VERSION ""

NS_ :

BS_:

BU_: Vector__XXX
BA_DEF_ BO_ "VFrameFormat" ENUM "StandardCAN","ExtendedCAN","reserved","J1939PG";
BA_DEF_DEF_ "VFrameFormat" 0;

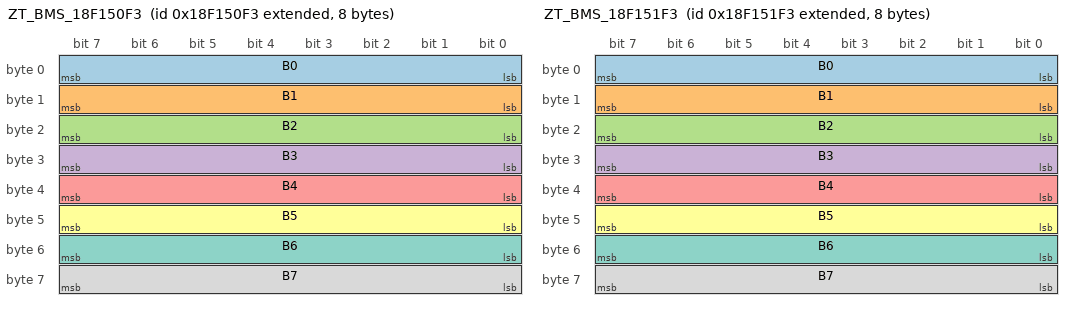
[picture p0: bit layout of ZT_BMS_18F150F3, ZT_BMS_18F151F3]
BO_ 2565951731 ZT_BMS_18F150F3: 8 Vector__XXX
 SG_ B0 : 0|8@1+ (1,0) [0|255] "" Vector__XXX
 SG_ B1 : 8|8@1+ (1,0) [0|255] "" Vector__XXX
 SG_ B2 : 16|8@1+ (1,0) [0|255] "" Vector__XXX
 SG_ B3 : 24|8@1+ (1,0) [0|255] "" Vector__XXX
 SG_ B4 : 32|8@1+ (1,0) [0|255] "" Vector__XXX
 SG_ B5 : 40|8@1+ (1,0) [0|255] "" Vector__XXX
 SG_ B6 : 48|8@1+ (1,0) [0|255] "" Vector__XXX
 SG_ B7 : 56|8@1+ (1,0) [0|255] "" Vector__XXX

BA_ "VFrameFormat" BO_ 2565951731 1;
CM_ BO_ 2565951731 "0xB3000005 中通新能源 > 纯电动客车 > 10-12米纯电公交客车 > 电池管理系统 | 0xB300006A 中通新能源 > 纯电动客车 > 电动新大巴客车 > 电池管理系统 | 部件: 电池管理系统";

BO_ 2565951987 ZT_BMS_18F151F3: 8 Vector__XXX
 SG_ B0 : 0|8@1+ (1,0) [0|255] "" Vector__XXX
 SG_ B1 : 8|8@1+ (1,0) [0|255] "" Vector__XXX
 SG_ B2 : 16|8@1+ (1,0) [0|255] "" Vector__XXX
 SG_ B3 : 24|8@1+ (1,0) [0|255] "" Vector__XXX
 SG_ B4 : 32|8@1+ (1,0) [0|255] "" Vector__XXX
 SG_ B5 : 40|8@1+ (1,0) [0|255] "" Vector__XXX
 SG_ B6 : 48|8@1+ (1,0) [0|255] "" Vector__XXX
 SG_ B7 : 56|8@1+ (1,0) [0|255] "" Vector__XXX

BA_ "VFrameFormat" BO_ 2565951987 1;
CM_ BO_ 2565951987 "0xB3000005 中通新能源 > 纯电动客车 > 10-12米纯电公交客车 > 电池管理系统 | 0xB300006A 中通新能源 > 纯电动客车 > 电动新大巴客车 > 电池管理系统 | 部件: 电池管理系统";

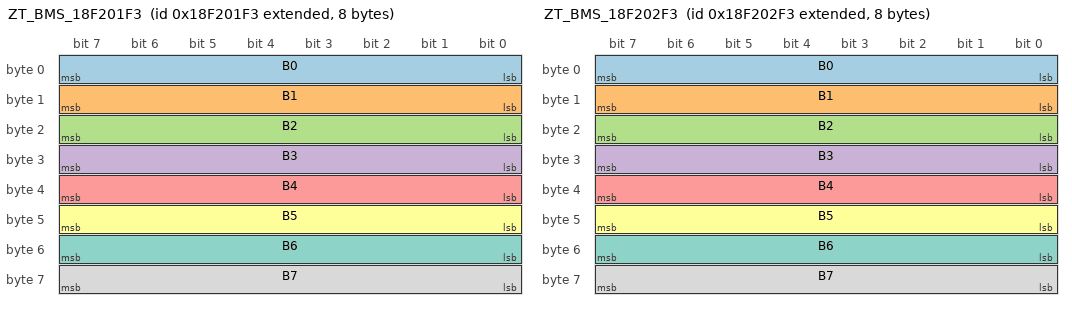
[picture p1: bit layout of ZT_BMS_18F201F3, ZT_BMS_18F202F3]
BO_ 2565997043 ZT_BMS_18F201F3: 8 Vector__XXX
 SG_ B0 : 0|8@1+ (1,0) [0|255] "" Vector__XXX
 SG_ B1 : 8|8@1+ (1,0) [0|255] "" Vector__XXX
 SG_ B2 : 16|8@1+ (1,0) [0|255] "" Vector__XXX
 SG_ B3 : 24|8@1+ (1,0) [0|255] "" Vector__XXX
 SG_ B4 : 32|8@1+ (1,0) [0|255] "" Vector__XXX
 SG_ B5 : 40|8@1+ (1,0) [0|255] "" Vector__XXX
 SG_ B6 : 48|8@1+ (1,0) [0|255] "" Vector__XXX
 SG_ B7 : 56|8@1+ (1,0) [0|255] "" Vector__XXX

BA_ "VFrameFormat" BO_ 2565997043 1;
CM_ BO_ 2565997043 "0xB3000005 中通新能源 > 纯电动客车 > 10-12米纯电公交客车 > 电池管理系统 | 0xB3000022 中通新能源 > 纯电动客车 > 6米微巴客车 > 电池管理系统 | 0xB300003D 中通新能源 > 纯电动客车 > 8米纯电公交客车 > 电池管理系统 | 0xB300006A 中通新能源 > 纯电动客车 > 电动新大巴客车 > 电池管理系统 | 0xB3000086 中通新能源 > 燃料电池客车 > 电池管理系统 | 0xB30000A8 中通新能源 > 澳巴混合动力 > 7米澳巴混合动力客车 > 电池管理系统 | 0xB30000C9 中通新能源 > 澳巴混合动力 > 9米11米澳巴混合动力客车 > 电池管理系统 | 部件: 电池管理系统";

BO_ 2565997299 ZT_BMS_18F202F3: 8 Vector__XXX
 SG_ B0 : 0|8@1+ (1,0) [0|255] "" Vector__XXX
 SG_ B1 : 8|8@1+ (1,0) [0|255] "" Vector__XXX
 SG_ B2 : 16|8@1+ (1,0) [0|255] "" Vector__XXX
 SG_ B3 : 24|8@1+ (1,0) [0|255] "" Vector__XXX
 SG_ B4 : 32|8@1+ (1,0) [0|255] "" Vector__XXX
 SG_ B5 : 40|8@1+ (1,0) [0|255] "" Vector__XXX
 SG_ B6 : 48|8@1+ (1,0) [0|255] "" Vector__XXX
 SG_ B7 : 56|8@1+ (1,0) [0|255] "" Vector__XXX

BA_ "VFrameFormat" BO_ 2565997299 1;
CM_ BO_ 2565997299 "0xB3000005 中通新能源 > 纯电动客车 > 10-12米纯电公交客车 > 电池管理系统 | 0xB3000022 中通新能源 > 纯电动客车 > 6米微巴客车 > 电池管理系统 | 0xB300003D 中通新能源 > 纯电动客车 > 8米纯电公交客车 > 电池管理系统 | 0xB300006A 中通新能源 > 纯电动客车 > 电动新大巴客车 > 电池管理系统 | 0xB3000086 中通新能源 > 燃料电池客车 > 电池管理系统 | 0xB30000A8 中通新能源 > 澳巴混合动力 > 7米澳巴混合动力客车 > 电池管理系统 | 0xB30000C9 中通新能源 > 澳巴混合动力 > 9米11米澳巴混合动力客车 > 电池管理系统 | 部件: 电池管理系统";

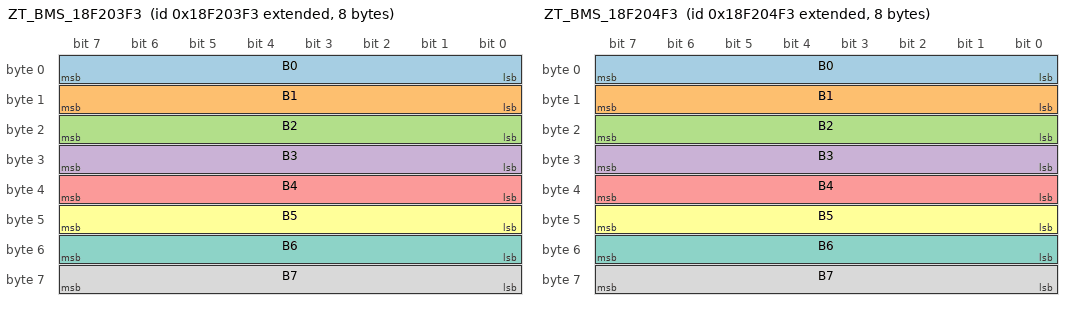
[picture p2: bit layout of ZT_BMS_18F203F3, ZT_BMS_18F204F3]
BO_ 2565997555 ZT_BMS_18F203F3: 8 Vector__XXX
 SG_ B0 : 0|8@1+ (1,0) [0|255] "" Vector__XXX
 SG_ B1 : 8|8@1+ (1,0) [0|255] "" Vector__XXX
 SG_ B2 : 16|8@1+ (1,0) [0|255] "" Vector__XXX
 SG_ B3 : 24|8@1+ (1,0) [0|255] "" Vector__XXX
 SG_ B4 : 32|8@1+ (1,0) [0|255] "" Vector__XXX
 SG_ B5 : 40|8@1+ (1,0) [0|255] "" Vector__XXX
 SG_ B6 : 48|8@1+ (1,0) [0|255] "" Vector__XXX
 SG_ B7 : 56|8@1+ (1,0) [0|255] "" Vector__XXX

BA_ "VFrameFormat" BO_ 2565997555 1;
CM_ BO_ 2565997555 "0xB3000005 中通新能源 > 纯电动客车 > 10-12米纯电公交客车 > 电池管理系统 | 0xB3000022 中通新能源 > 纯电动客车 > 6米微巴客车 > 电池管理系统 | 0xB300003D 中通新能源 > 纯电动客车 > 8米纯电公交客车 > 电池管理系统 | 0xB300006A 中通新能源 > 纯电动客车 > 电动新大巴客车 > 电池管理系统 | 0xB3000086 中通新能源 > 燃料电池客车 > 电池管理系统 | 0xB30000A8 中通新能源 > 澳巴混合动力 > 7米澳巴混合动力客车 > 电池管理系统 | 0xB30000C9 中通新能源 > 澳巴混合动力 > 9米11米澳巴混合动力客车 > 电池管理系统 | 部件: 电池管理系统";

BO_ 2565997811 ZT_BMS_18F204F3: 8 Vector__XXX
 SG_ B0 : 0|8@1+ (1,0) [0|255] "" Vector__XXX
 SG_ B1 : 8|8@1+ (1,0) [0|255] "" Vector__XXX
 SG_ B2 : 16|8@1+ (1,0) [0|255] "" Vector__XXX
 SG_ B3 : 24|8@1+ (1,0) [0|255] "" Vector__XXX
 SG_ B4 : 32|8@1+ (1,0) [0|255] "" Vector__XXX
 SG_ B5 : 40|8@1+ (1,0) [0|255] "" Vector__XXX
 SG_ B6 : 48|8@1+ (1,0) [0|255] "" Vector__XXX
 SG_ B7 : 56|8@1+ (1,0) [0|255] "" Vector__XXX

BA_ "VFrameFormat" BO_ 2565997811 1;
CM_ BO_ 2565997811 "0xB3000005 中通新能源 > 纯电动客车 > 10-12米纯电公交客车 > 电池管理系统 | 0xB300003D 中通新能源 > 纯电动客车 > 8米纯电公交客车 > 电池管理系统 | 0xB300006A 中通新能源 > 纯电动客车 > 电动新大巴客车 > 电池管理系统 | 0xB30000C9 中通新能源 > 澳巴混合动力 > 9米11米澳巴混合动力客车 > 电池管理系统 | 部件: 电池管理系统";

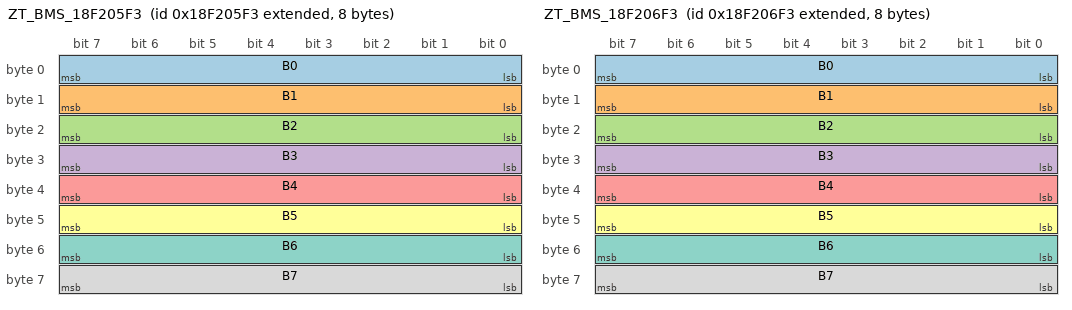
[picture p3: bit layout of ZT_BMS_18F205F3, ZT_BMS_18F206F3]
BO_ 2565998067 ZT_BMS_18F205F3: 8 Vector__XXX
 SG_ B0 : 0|8@1+ (1,0) [0|255] "" Vector__XXX
 SG_ B1 : 8|8@1+ (1,0) [0|255] "" Vector__XXX
 SG_ B2 : 16|8@1+ (1,0) [0|255] "" Vector__XXX
 SG_ B3 : 24|8@1+ (1,0) [0|255] "" Vector__XXX
 SG_ B4 : 32|8@1+ (1,0) [0|255] "" Vector__XXX
 SG_ B5 : 40|8@1+ (1,0) [0|255] "" Vector__XXX
 SG_ B6 : 48|8@1+ (1,0) [0|255] "" Vector__XXX
 SG_ B7 : 56|8@1+ (1,0) [0|255] "" Vector__XXX

BA_ "VFrameFormat" BO_ 2565998067 1;
CM_ BO_ 2565998067 "0xB3000005 中通新能源 > 纯电动客车 > 10-12米纯电公交客车 > 电池管理系统 | 0xB300006A 中通新能源 > 纯电动客车 > 电动新大巴客车 > 电池管理系统 | 部件: 电池管理系统";

BO_ 2565998323 ZT_BMS_18F206F3: 8 Vector__XXX
 SG_ B0 : 0|8@1+ (1,0) [0|255] "" Vector__XXX
 SG_ B1 : 8|8@1+ (1,0) [0|255] "" Vector__XXX
 SG_ B2 : 16|8@1+ (1,0) [0|255] "" Vector__XXX
 SG_ B3 : 24|8@1+ (1,0) [0|255] "" Vector__XXX
 SG_ B4 : 32|8@1+ (1,0) [0|255] "" Vector__XXX
 SG_ B5 : 40|8@1+ (1,0) [0|255] "" Vector__XXX
 SG_ B6 : 48|8@1+ (1,0) [0|255] "" Vector__XXX
 SG_ B7 : 56|8@1+ (1,0) [0|255] "" Vector__XXX

BA_ "VFrameFormat" BO_ 2565998323 1;
CM_ BO_ 2565998323 "0xB3000005 中通新能源 > 纯电动客车 > 10-12米纯电公交客车 > 电池管理系统 | 0xB300006A 中通新能源 > 纯电动客车 > 电动新大巴客车 > 电池管理系统 | 部件: 电池管理系统";

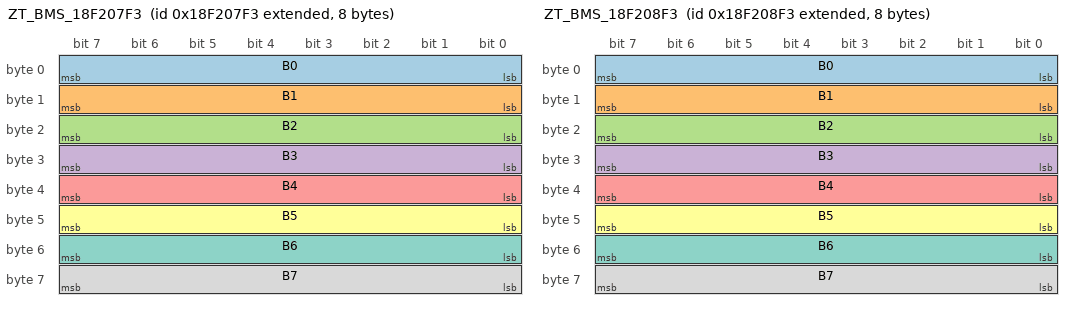
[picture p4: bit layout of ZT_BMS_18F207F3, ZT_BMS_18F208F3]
BO_ 2565998579 ZT_BMS_18F207F3: 8 Vector__XXX
 SG_ B0 : 0|8@1+ (1,0) [0|255] "" Vector__XXX
 SG_ B1 : 8|8@1+ (1,0) [0|255] "" Vector__XXX
 SG_ B2 : 16|8@1+ (1,0) [0|255] "" Vector__XXX
 SG_ B3 : 24|8@1+ (1,0) [0|255] "" Vector__XXX
 SG_ B4 : 32|8@1+ (1,0) [0|255] "" Vector__XXX
 SG_ B5 : 40|8@1+ (1,0) [0|255] "" Vector__XXX
 SG_ B6 : 48|8@1+ (1,0) [0|255] "" Vector__XXX
 SG_ B7 : 56|8@1+ (1,0) [0|255] "" Vector__XXX

BA_ "VFrameFormat" BO_ 2565998579 1;
CM_ BO_ 2565998579 "0xB3000005 中通新能源 > 纯电动客车 > 10-12米纯电公交客车 > 电池管理系统 | 部件: 电池管理系统";

BO_ 2565998835 ZT_BMS_18F208F3: 8 Vector__XXX
 SG_ B0 : 0|8@1+ (1,0) [0|255] "" Vector__XXX
 SG_ B1 : 8|8@1+ (1,0) [0|255] "" Vector__XXX
 SG_ B2 : 16|8@1+ (1,0) [0|255] "" Vector__XXX
 SG_ B3 : 24|8@1+ (1,0) [0|255] "" Vector__XXX
 SG_ B4 : 32|8@1+ (1,0) [0|255] "" Vector__XXX
 SG_ B5 : 40|8@1+ (1,0) [0|255] "" Vector__XXX
 SG_ B6 : 48|8@1+ (1,0) [0|255] "" Vector__XXX
 SG_ B7 : 56|8@1+ (1,0) [0|255] "" Vector__XXX

BA_ "VFrameFormat" BO_ 2565998835 1;
CM_ BO_ 2565998835 "0xB3000005 中通新能源 > 纯电动客车 > 10-12米纯电公交客车 > 电池管理系统 | 部件: 电池管理系统";

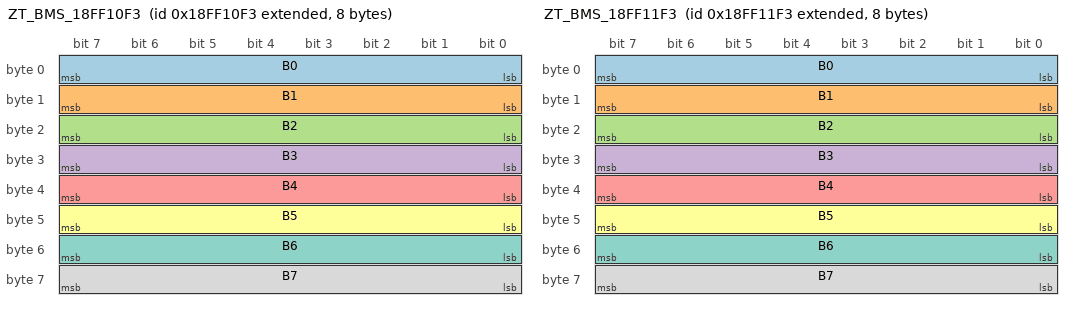
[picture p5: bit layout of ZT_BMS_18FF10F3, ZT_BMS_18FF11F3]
BO_ 2566852851 ZT_BMS_18FF10F3: 8 Vector__XXX
 SG_ B0 : 0|8@1+ (1,0) [0|255] "" Vector__XXX
 SG_ B1 : 8|8@1+ (1,0) [0|255] "" Vector__XXX
 SG_ B2 : 16|8@1+ (1,0) [0|255] "" Vector__XXX
 SG_ B3 : 24|8@1+ (1,0) [0|255] "" Vector__XXX
 SG_ B4 : 32|8@1+ (1,0) [0|255] "" Vector__XXX
 SG_ B5 : 40|8@1+ (1,0) [0|255] "" Vector__XXX
 SG_ B6 : 48|8@1+ (1,0) [0|255] "" Vector__XXX
 SG_ B7 : 56|8@1+ (1,0) [0|255] "" Vector__XXX

BA_ "VFrameFormat" BO_ 2566852851 1;
CM_ BO_ 2566852851 "0xB3000005 中通新能源 > 纯电动客车 > 10-12米纯电公交客车 > 电池管理系统 | 0xB3000022 中通新能源 > 纯电动客车 > 6米微巴客车 > 电池管理系统 | 0xB300003D 中通新能源 > 纯电动客车 > 8米纯电公交客车 > 电池管理系统 | 0xB300006A 中通新能源 > 纯电动客车 > 电动新大巴客车 > 电池管理系统 | 0xB3000086 中通新能源 > 燃料电池客车 > 电池管理系统 | 0xB30000A8 中通新能源 > 澳巴混合动力 > 7米澳巴混合动力客车 > 电池管理系统 | 0xB30000C9 中通新能源 > 澳巴混合动力 > 9米11米澳巴混合动力客车 > 电池管理系统 | 部件: 电池管理系统";

BO_ 2566853107 ZT_BMS_18FF11F3: 8 Vector__XXX
 SG_ B0 : 0|8@1+ (1,0) [0|255] "" Vector__XXX
 SG_ B1 : 8|8@1+ (1,0) [0|255] "" Vector__XXX
 SG_ B2 : 16|8@1+ (1,0) [0|255] "" Vector__XXX
 SG_ B3 : 24|8@1+ (1,0) [0|255] "" Vector__XXX
 SG_ B4 : 32|8@1+ (1,0) [0|255] "" Vector__XXX
 SG_ B5 : 40|8@1+ (1,0) [0|255] "" Vector__XXX
 SG_ B6 : 48|8@1+ (1,0) [0|255] "" Vector__XXX
 SG_ B7 : 56|8@1+ (1,0) [0|255] "" Vector__XXX

BA_ "VFrameFormat" BO_ 2566853107 1;
CM_ BO_ 2566853107 "0xB3000005 中通新能源 > 纯电动客车 > 10-12米纯电公交客车 > 电池管理系统 | 0xB3000022 中通新能源 > 纯电动客车 > 6米微巴客车 > 电池管理系统 | 0xB300003D 中通新能源 > 纯电动客车 > 8米纯电公交客车 > 电池管理系统 | 0xB300006A 中通新能源 > 纯电动客车 > 电动新大巴客车 > 电池管理系统 | 0xB3000086 中通新能源 > 燃料电池客车 > 电池管理系统 | 0xB30000A8 中通新能源 > 澳巴混合动力 > 7米澳巴混合动力客车 > 电池管理系统 | 0xB30000C9 中通新能源 > 澳巴混合动力 > 9米11米澳巴混合动力客车 > 电池管理系统 | 部件: 电池管理系统";

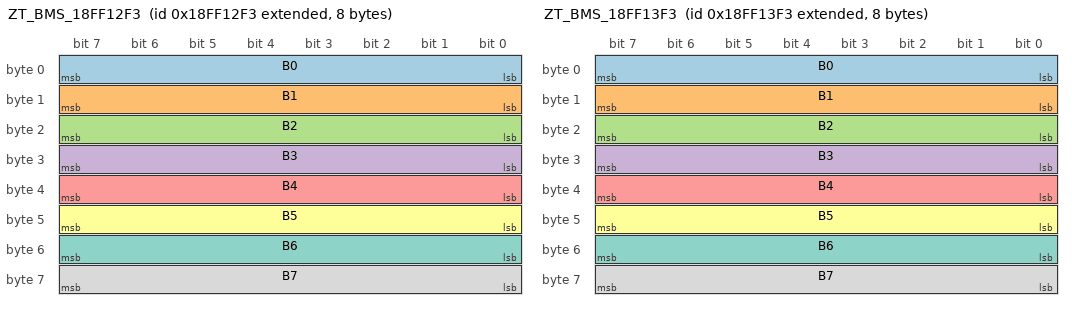
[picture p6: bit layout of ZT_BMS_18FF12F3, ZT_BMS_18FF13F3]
BO_ 2566853363 ZT_BMS_18FF12F3: 8 Vector__XXX
 SG_ B0 : 0|8@1+ (1,0) [0|255] "" Vector__XXX
 SG_ B1 : 8|8@1+ (1,0) [0|255] "" Vector__XXX
 SG_ B2 : 16|8@1+ (1,0) [0|255] "" Vector__XXX
 SG_ B3 : 24|8@1+ (1,0) [0|255] "" Vector__XXX
 SG_ B4 : 32|8@1+ (1,0) [0|255] "" Vector__XXX
 SG_ B5 : 40|8@1+ (1,0) [0|255] "" Vector__XXX
 SG_ B6 : 48|8@1+ (1,0) [0|255] "" Vector__XXX
 SG_ B7 : 56|8@1+ (1,0) [0|255] "" Vector__XXX

BA_ "VFrameFormat" BO_ 2566853363 1;
CM_ BO_ 2566853363 "0xB3000005 中通新能源 > 纯电动客车 > 10-12米纯电公交客车 > 电池管理系统 | 0xB3000022 中通新能源 > 纯电动客车 > 6米微巴客车 > 电池管理系统 | 0xB300003D 中通新能源 > 纯电动客车 > 8米纯电公交客车 > 电池管理系统 | 0xB300006A 中通新能源 > 纯电动客车 > 电动新大巴客车 > 电池管理系统 | 0xB3000086 中通新能源 > 燃料电池客车 > 电池管理系统 | 0xB30000A8 中通新能源 > 澳巴混合动力 > 7米澳巴混合动力客车 > 电池管理系统 | 0xB30000C9 中通新能源 > 澳巴混合动力 > 9米11米澳巴混合动力客车 > 电池管理系统 | 部件: 电池管理系统";

BO_ 2566853619 ZT_BMS_18FF13F3: 8 Vector__XXX
 SG_ B0 : 0|8@1+ (1,0) [0|255] "" Vector__XXX
 SG_ B1 : 8|8@1+ (1,0) [0|255] "" Vector__XXX
 SG_ B2 : 16|8@1+ (1,0) [0|255] "" Vector__XXX
 SG_ B3 : 24|8@1+ (1,0) [0|255] "" Vector__XXX
 SG_ B4 : 32|8@1+ (1,0) [0|255] "" Vector__XXX
 SG_ B5 : 40|8@1+ (1,0) [0|255] "" Vector__XXX
 SG_ B6 : 48|8@1+ (1,0) [0|255] "" Vector__XXX
 SG_ B7 : 56|8@1+ (1,0) [0|255] "" Vector__XXX

BA_ "VFrameFormat" BO_ 2566853619 1;
CM_ BO_ 2566853619 "0xB3000005 中通新能源 > 纯电动客车 > 10-12米纯电公交客车 > 电池管理系统 | 0xB3000022 中通新能源 > 纯电动客车 > 6米微巴客车 > 电池管理系统 | 0xB300003D 中通新能源 > 纯电动客车 > 8米纯电公交客车 > 电池管理系统 | 0xB300006A 中通新能源 > 纯电动客车 > 电动新大巴客车 > 电池管理系统 | 0xB3000086 中通新能源 > 燃料电池客车 > 电池管理系统 | 0xB30000A8 中通新能源 > 澳巴混合动力 > 7米澳巴混合动力客车 > 电池管理系统 | 0xB30000C9 中通新能源 > 澳巴混合动力 > 9米11米澳巴混合动力客车 > 电池管理系统 | 部件: 电池管理系统";

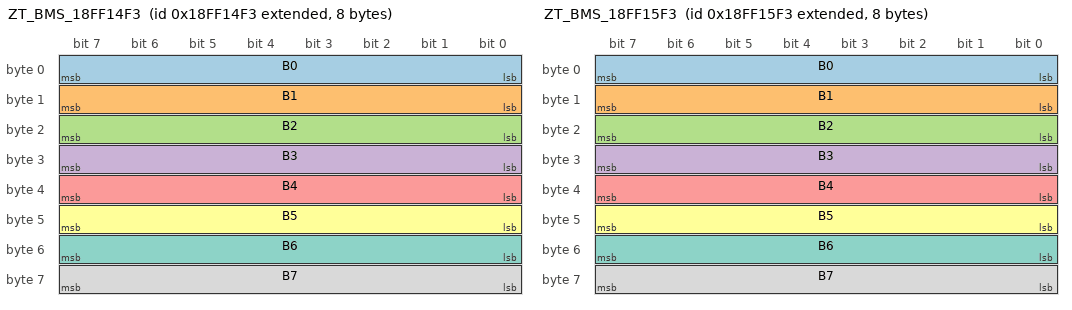
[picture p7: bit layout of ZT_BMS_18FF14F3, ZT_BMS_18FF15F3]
BO_ 2566853875 ZT_BMS_18FF14F3: 8 Vector__XXX
 SG_ B0 : 0|8@1+ (1,0) [0|255] "" Vector__XXX
 SG_ B1 : 8|8@1+ (1,0) [0|255] "" Vector__XXX
 SG_ B2 : 16|8@1+ (1,0) [0|255] "" Vector__XXX
 SG_ B3 : 24|8@1+ (1,0) [0|255] "" Vector__XXX
 SG_ B4 : 32|8@1+ (1,0) [0|255] "" Vector__XXX
 SG_ B5 : 40|8@1+ (1,0) [0|255] "" Vector__XXX
 SG_ B6 : 48|8@1+ (1,0) [0|255] "" Vector__XXX
 SG_ B7 : 56|8@1+ (1,0) [0|255] "" Vector__XXX

BA_ "VFrameFormat" BO_ 2566853875 1;
CM_ BO_ 2566853875 "0xB3000005 中通新能源 > 纯电动客车 > 10-12米纯电公交客车 > 电池管理系统 | 0xB3000022 中通新能源 > 纯电动客车 > 6米微巴客车 > 电池管理系统 | 0xB300003D 中通新能源 > 纯电动客车 > 8米纯电公交客车 > 电池管理系统 | 0xB300006A 中通新能源 > 纯电动客车 > 电动新大巴客车 > 电池管理系统 | 0xB3000086 中通新能源 > 燃料电池客车 > 电池管理系统 | 0xB30000A8 中通新能源 > 澳巴混合动力 > 7米澳巴混合动力客车 > 电池管理系统 | 0xB30000C9 中通新能源 > 澳巴混合动力 > 9米11米澳巴混合动力客车 > 电池管理系统 | 部件: 电池管理系统";

BO_ 2566854131 ZT_BMS_18FF15F3: 8 Vector__XXX
 SG_ B0 : 0|8@1+ (1,0) [0|255] "" Vector__XXX
 SG_ B1 : 8|8@1+ (1,0) [0|255] "" Vector__XXX
 SG_ B2 : 16|8@1+ (1,0) [0|255] "" Vector__XXX
 SG_ B3 : 24|8@1+ (1,0) [0|255] "" Vector__XXX
 SG_ B4 : 32|8@1+ (1,0) [0|255] "" Vector__XXX
 SG_ B5 : 40|8@1+ (1,0) [0|255] "" Vector__XXX
 SG_ B6 : 48|8@1+ (1,0) [0|255] "" Vector__XXX
 SG_ B7 : 56|8@1+ (1,0) [0|255] "" Vector__XXX

BA_ "VFrameFormat" BO_ 2566854131 1;
CM_ BO_ 2566854131 "0xB3000005 中通新能源 > 纯电动客车 > 10-12米纯电公交客车 > 电池管理系统 | 0xB3000022 中通新能源 > 纯电动客车 > 6米微巴客车 > 电池管理系统 | 0xB300003D 中通新能源 > 纯电动客车 > 8米纯电公交客车 > 电池管理系统 | 0xB300006A 中通新能源 > 纯电动客车 > 电动新大巴客车 > 电池管理系统 | 0xB3000086 中通新能源 > 燃料电池客车 > 电池管理系统 | 0xB30000A8 中通新能源 > 澳巴混合动力 > 7米澳巴混合动力客车 > 电池管理系统 | 0xB30000C9 中通新能源 > 澳巴混合动力 > 9米11米澳巴混合动力客车 > 电池管理系统 | 部件: 电池管理系统";

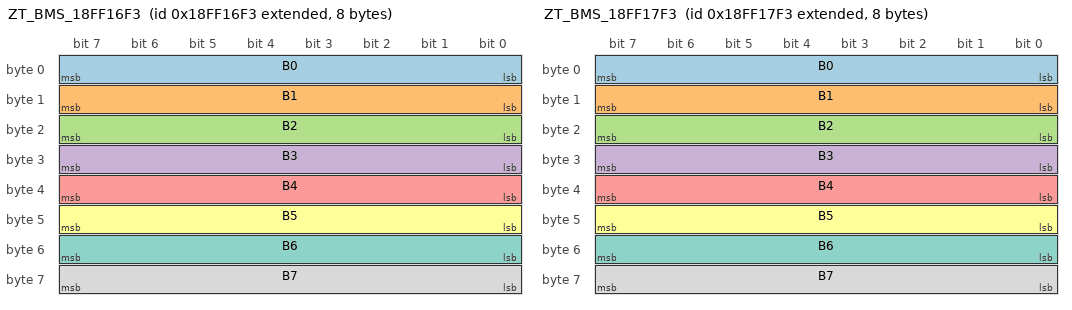
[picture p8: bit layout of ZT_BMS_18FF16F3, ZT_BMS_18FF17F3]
BO_ 2566854387 ZT_BMS_18FF16F3: 8 Vector__XXX
 SG_ B0 : 0|8@1+ (1,0) [0|255] "" Vector__XXX
 SG_ B1 : 8|8@1+ (1,0) [0|255] "" Vector__XXX
 SG_ B2 : 16|8@1+ (1,0) [0|255] "" Vector__XXX
 SG_ B3 : 24|8@1+ (1,0) [0|255] "" Vector__XXX
 SG_ B4 : 32|8@1+ (1,0) [0|255] "" Vector__XXX
 SG_ B5 : 40|8@1+ (1,0) [0|255] "" Vector__XXX
 SG_ B6 : 48|8@1+ (1,0) [0|255] "" Vector__XXX
 SG_ B7 : 56|8@1+ (1,0) [0|255] "" Vector__XXX

BA_ "VFrameFormat" BO_ 2566854387 1;
CM_ BO_ 2566854387 "0xB3000005 中通新能源 > 纯电动客车 > 10-12米纯电公交客车 > 电池管理系统 | 0xB300006A 中通新能源 > 纯电动客车 > 电动新大巴客车 > 电池管理系统 | 部件: 电池管理系统";

BO_ 2566854643 ZT_BMS_18FF17F3: 8 Vector__XXX
 SG_ B0 : 0|8@1+ (1,0) [0|255] "" Vector__XXX
 SG_ B1 : 8|8@1+ (1,0) [0|255] "" Vector__XXX
 SG_ B2 : 16|8@1+ (1,0) [0|255] "" Vector__XXX
 SG_ B3 : 24|8@1+ (1,0) [0|255] "" Vector__XXX
 SG_ B4 : 32|8@1+ (1,0) [0|255] "" Vector__XXX
 SG_ B5 : 40|8@1+ (1,0) [0|255] "" Vector__XXX
 SG_ B6 : 48|8@1+ (1,0) [0|255] "" Vector__XXX
 SG_ B7 : 56|8@1+ (1,0) [0|255] "" Vector__XXX

BA_ "VFrameFormat" BO_ 2566854643 1;
CM_ BO_ 2566854643 "0xB3000005 中通新能源 > 纯电动客车 > 10-12米纯电公交客车 > 电池管理系统 | 0xB300006A 中通新能源 > 纯电动客车 > 电动新大巴客车 > 电池管理系统 | 部件: 电池管理系统";

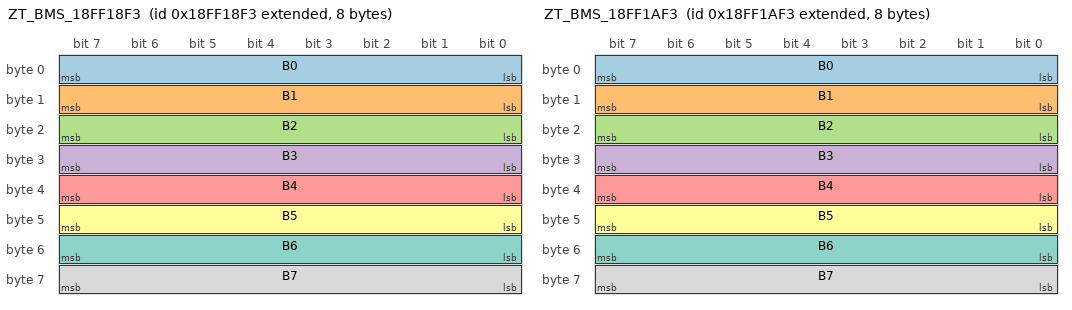
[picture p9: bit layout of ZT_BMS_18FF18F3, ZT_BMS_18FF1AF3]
BO_ 2566854899 ZT_BMS_18FF18F3: 8 Vector__XXX
 SG_ B0 : 0|8@1+ (1,0) [0|255] "" Vector__XXX
 SG_ B1 : 8|8@1+ (1,0) [0|255] "" Vector__XXX
 SG_ B2 : 16|8@1+ (1,0) [0|255] "" Vector__XXX
 SG_ B3 : 24|8@1+ (1,0) [0|255] "" Vector__XXX
 SG_ B4 : 32|8@1+ (1,0) [0|255] "" Vector__XXX
 SG_ B5 : 40|8@1+ (1,0) [0|255] "" Vector__XXX
 SG_ B6 : 48|8@1+ (1,0) [0|255] "" Vector__XXX
 SG_ B7 : 56|8@1+ (1,0) [0|255] "" Vector__XXX

BA_ "VFrameFormat" BO_ 2566854899 1;
CM_ BO_ 2566854899 "0xB3000005 中通新能源 > 纯电动客车 > 10-12米纯电公交客车 > 电池管理系统 | 0xB3000022 中通新能源 > 纯电动客车 > 6米微巴客车 > 电池管理系统 | 0xB300003D 中通新能源 > 纯电动客车 > 8米纯电公交客车 > 电池管理系统 | 0xB300006A 中通新能源 > 纯电动客车 > 电动新大巴客车 > 电池管理系统 | 0xB3000086 中通新能源 > 燃料电池客车 > 电池管理系统 | 0xB30000A8 中通新能源 > 澳巴混合动力 > 7米澳巴混合动力客车 > 电池管理系统 | 0xB30000C9 中通新能源 > 澳巴混合动力 > 9米11米澳巴混合动力客车 > 电池管理系统 | 部件: 电池管理系统";

BO_ 2566855411 ZT_BMS_18FF1AF3: 8 Vector__XXX
 SG_ B0 : 0|8@1+ (1,0) [0|255] "" Vector__XXX
 SG_ B1 : 8|8@1+ (1,0) [0|255] "" Vector__XXX
 SG_ B2 : 16|8@1+ (1,0) [0|255] "" Vector__XXX
 SG_ B3 : 24|8@1+ (1,0) [0|255] "" Vector__XXX
 SG_ B4 : 32|8@1+ (1,0) [0|255] "" Vector__XXX
 SG_ B5 : 40|8@1+ (1,0) [0|255] "" Vector__XXX
 SG_ B6 : 48|8@1+ (1,0) [0|255] "" Vector__XXX
 SG_ B7 : 56|8@1+ (1,0) [0|255] "" Vector__XXX

BA_ "VFrameFormat" BO_ 2566855411 1;
CM_ BO_ 2566855411 "0xB3000005 中通新能源 > 纯电动客车 > 10-12米纯电公交客车 > 电池管理系统 | 0xB300003D 中通新能源 > 纯电动客车 > 8米纯电公交客车 > 电池管理系统 | 0xB300006A 中通新能源 > 纯电动客车 > 电动新大巴客车 > 电池管理系统 | 0xB3000086 中通新能源 > 燃料电池客车 > 电池管理系统 | 0xB30000A8 中通新能源 > 澳巴混合动力 > 7米澳巴混合动力客车 > 电池管理系统 | 0xB30000C9 中通新能源 > 澳巴混合动力 > 9米11米澳巴混合动力客车 > 电池管理系统 | 部件: 电池管理系统";

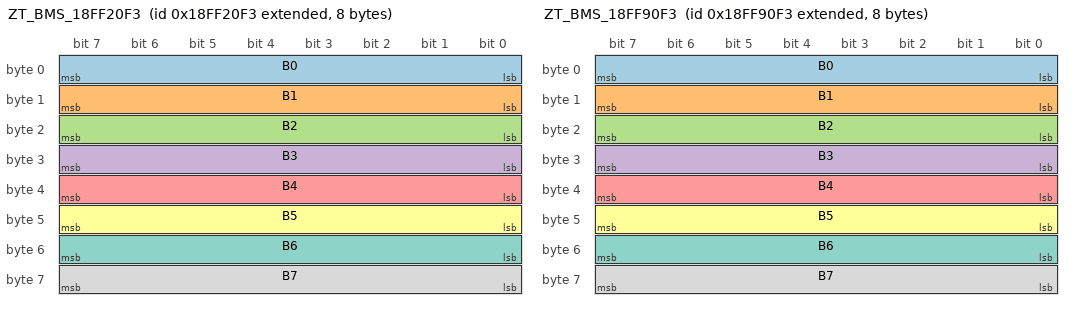
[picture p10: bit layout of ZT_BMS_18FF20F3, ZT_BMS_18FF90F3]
BO_ 2566856947 ZT_BMS_18FF20F3: 8 Vector__XXX
 SG_ B0 : 0|8@1+ (1,0) [0|255] "" Vector__XXX
 SG_ B1 : 8|8@1+ (1,0) [0|255] "" Vector__XXX
 SG_ B2 : 16|8@1+ (1,0) [0|255] "" Vector__XXX
 SG_ B3 : 24|8@1+ (1,0) [0|255] "" Vector__XXX
 SG_ B4 : 32|8@1+ (1,0) [0|255] "" Vector__XXX
 SG_ B5 : 40|8@1+ (1,0) [0|255] "" Vector__XXX
 SG_ B6 : 48|8@1+ (1,0) [0|255] "" Vector__XXX
 SG_ B7 : 56|8@1+ (1,0) [0|255] "" Vector__XXX

BA_ "VFrameFormat" BO_ 2566856947 1;
CM_ BO_ 2566856947 "0xB3000005 中通新能源 > 纯电动客车 > 10-12米纯电公交客车 > 电池管理系统 | 0xB3000022 中通新能源 > 纯电动客车 > 6米微巴客车 > 电池管理系统 | 0xB300003D 中通新能源 > 纯电动客车 > 8米纯电公交客车 > 电池管理系统 | 0xB300006A 中通新能源 > 纯电动客车 > 电动新大巴客车 > 电池管理系统 | 0xB3000086 中通新能源 > 燃料电池客车 > 电池管理系统 | 0xB30000A8 中通新能源 > 澳巴混合动力 > 7米澳巴混合动力客车 > 电池管理系统 | 0xB30000C9 中通新能源 > 澳巴混合动力 > 9米11米澳巴混合动力客车 > 电池管理系统 | 部件: 电池管理系统";

BO_ 2566885619 ZT_BMS_18FF90F3: 8 Vector__XXX
 SG_ B0 : 0|8@1+ (1,0) [0|255] "" Vector__XXX
 SG_ B1 : 8|8@1+ (1,0) [0|255] "" Vector__XXX
 SG_ B2 : 16|8@1+ (1,0) [0|255] "" Vector__XXX
 SG_ B3 : 24|8@1+ (1,0) [0|255] "" Vector__XXX
 SG_ B4 : 32|8@1+ (1,0) [0|255] "" Vector__XXX
 SG_ B5 : 40|8@1+ (1,0) [0|255] "" Vector__XXX
 SG_ B6 : 48|8@1+ (1,0) [0|255] "" Vector__XXX
 SG_ B7 : 56|8@1+ (1,0) [0|255] "" Vector__XXX

BA_ "VFrameFormat" BO_ 2566885619 1;
CM_ BO_ 2566885619 "0xB3000005 中通新能源 > 纯电动客车 > 10-12米纯电公交客车 > 电池管理系统 | 0xB3000022 中通新能源 > 纯电动客车 > 6米微巴客车 > 电池管理系统 | 0xB300003D 中通新能源 > 纯电动客车 > 8米纯电公交客车 > 电池管理系统 | 0xB300006A 中通新能源 > 纯电动客车 > 电动新大巴客车 > 电池管理系统 | 0xB3000086 中通新能源 > 燃料电池客车 > 电池管理系统 | 0xB30000A8 中通新能源 > 澳巴混合动力 > 7米澳巴混合动力客车 > 电池管理系统 | 0xB30000C9 中通新能源 > 澳巴混合动力 > 9米11米澳巴混合动力客车 > 电池管理系统 | 部件: 电池管理系统";

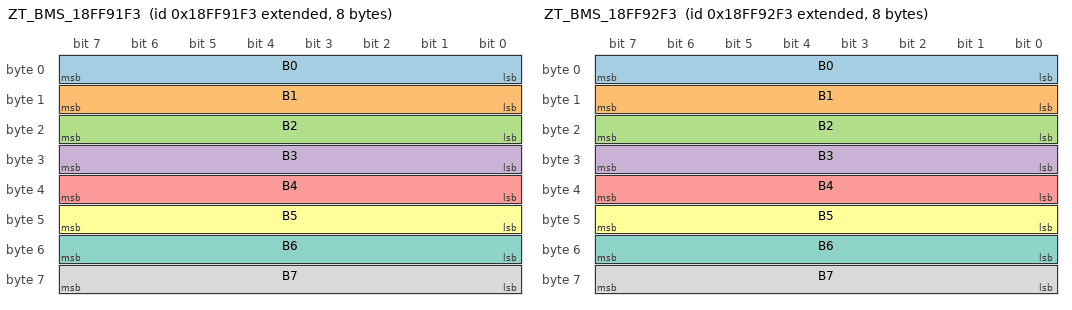
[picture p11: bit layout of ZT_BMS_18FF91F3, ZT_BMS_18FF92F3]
BO_ 2566885875 ZT_BMS_18FF91F3: 8 Vector__XXX
 SG_ B0 : 0|8@1+ (1,0) [0|255] "" Vector__XXX
 SG_ B1 : 8|8@1+ (1,0) [0|255] "" Vector__XXX
 SG_ B2 : 16|8@1+ (1,0) [0|255] "" Vector__XXX
 SG_ B3 : 24|8@1+ (1,0) [0|255] "" Vector__XXX
 SG_ B4 : 32|8@1+ (1,0) [0|255] "" Vector__XXX
 SG_ B5 : 40|8@1+ (1,0) [0|255] "" Vector__XXX
 SG_ B6 : 48|8@1+ (1,0) [0|255] "" Vector__XXX
 SG_ B7 : 56|8@1+ (1,0) [0|255] "" Vector__XXX

BA_ "VFrameFormat" BO_ 2566885875 1;
CM_ BO_ 2566885875 "0xB3000005 中通新能源 > 纯电动客车 > 10-12米纯电公交客车 > 电池管理系统 | 0xB3000022 中通新能源 > 纯电动客车 > 6米微巴客车 > 电池管理系统 | 0xB300003D 中通新能源 > 纯电动客车 > 8米纯电公交客车 > 电池管理系统 | 0xB300006A 中通新能源 > 纯电动客车 > 电动新大巴客车 > 电池管理系统 | 0xB3000086 中通新能源 > 燃料电池客车 > 电池管理系统 | 0xB30000A8 中通新能源 > 澳巴混合动力 > 7米澳巴混合动力客车 > 电池管理系统 | 0xB30000C9 中通新能源 > 澳巴混合动力 > 9米11米澳巴混合动力客车 > 电池管理系统 | 部件: 电池管理系统";

BO_ 2566886131 ZT_BMS_18FF92F3: 8 Vector__XXX
 SG_ B0 : 0|8@1+ (1,0) [0|255] "" Vector__XXX
 SG_ B1 : 8|8@1+ (1,0) [0|255] "" Vector__XXX
 SG_ B2 : 16|8@1+ (1,0) [0|255] "" Vector__XXX
 SG_ B3 : 24|8@1+ (1,0) [0|255] "" Vector__XXX
 SG_ B4 : 32|8@1+ (1,0) [0|255] "" Vector__XXX
 SG_ B5 : 40|8@1+ (1,0) [0|255] "" Vector__XXX
 SG_ B6 : 48|8@1+ (1,0) [0|255] "" Vector__XXX
 SG_ B7 : 56|8@1+ (1,0) [0|255] "" Vector__XXX

BA_ "VFrameFormat" BO_ 2566886131 1;
CM_ BO_ 2566886131 "0xB3000005 中通新能源 > 纯电动客车 > 10-12米纯电公交客车 > 电池管理系统 | 0xB3000022 中通新能源 > 纯电动客车 > 6米微巴客车 > 电池管理系统 | 0xB300003D 中通新能源 > 纯电动客车 > 8米纯电公交客车 > 电池管理系统 | 0xB300006A 中通新能源 > 纯电动客车 > 电动新大巴客车 > 电池管理系统 | 0xB3000086 中通新能源 > 燃料电池客车 > 电池管理系统 | 0xB30000A8 中通新能源 > 澳巴混合动力 > 7米澳巴混合动力客车 > 电池管理系统 | 0xB30000C9 中通新能源 > 澳巴混合动力 > 9米11米澳巴混合动力客车 > 电池管理系统 | 部件: 电池管理系统";

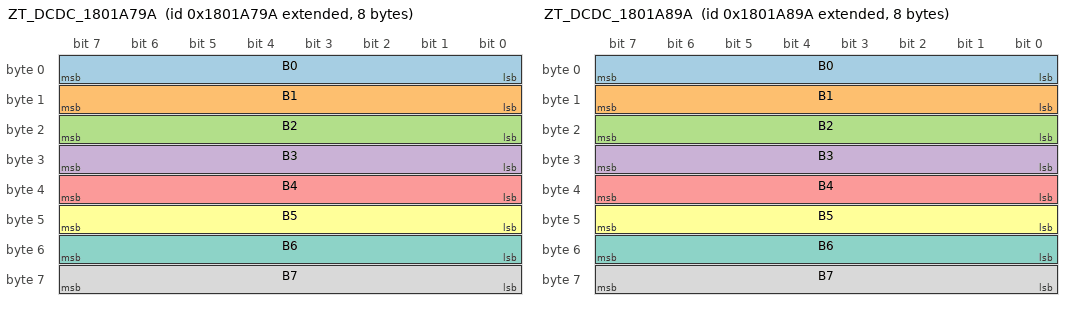
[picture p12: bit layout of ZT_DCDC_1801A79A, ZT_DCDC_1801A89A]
BO_ 2550245274 ZT_DCDC_1801A79A: 8 Vector__XXX
 SG_ B0 : 0|8@1+ (1,0) [0|255] "" Vector__XXX
 SG_ B1 : 8|8@1+ (1,0) [0|255] "" Vector__XXX
 SG_ B2 : 16|8@1+ (1,0) [0|255] "" Vector__XXX
 SG_ B3 : 24|8@1+ (1,0) [0|255] "" Vector__XXX
 SG_ B4 : 32|8@1+ (1,0) [0|255] "" Vector__XXX
 SG_ B5 : 40|8@1+ (1,0) [0|255] "" Vector__XXX
 SG_ B6 : 48|8@1+ (1,0) [0|255] "" Vector__XXX
 SG_ B7 : 56|8@1+ (1,0) [0|255] "" Vector__XXX

BA_ "VFrameFormat" BO_ 2550245274 1;
CM_ BO_ 2550245274 "0xB3000006 中通新能源 > 纯电动客车 > 10-12米纯电公交客车 > DCDC 直流变压器 | 0xB3000023 中通新能源 > 纯电动客车 > 6米微巴客车 > DCDC 直流变压器 | 0xB300003E 中通新能源 > 纯电动客车 > 8米纯电公交客车 > DCDC 直流变压器 | 0xB300006B 中通新能源 > 纯电动客车 > 电动新大巴客车 > DCDC 直流变压器 | 0xB30000A0 中通新能源 > 燃料电池客车 > 3KW DC/DC（燃料电池系统散热） | 0xB30000A9 中通新能源 > 澳巴混合动力 > 7米澳巴混合动力客车 > DCDC 直流变压器 | 0xB30000CA 中通新能源 > 澳巴混合动力 > 9米11米澳巴混合动力客车 > DCDC 直流变压器 | 部件: DCDC 直流变压器";

BO_ 2550245530 ZT_DCDC_1801A89A: 8 Vector__XXX
 SG_ B0 : 0|8@1+ (1,0) [0|255] "" Vector__XXX
 SG_ B1 : 8|8@1+ (1,0) [0|255] "" Vector__XXX
 SG_ B2 : 16|8@1+ (1,0) [0|255] "" Vector__XXX
 SG_ B3 : 24|8@1+ (1,0) [0|255] "" Vector__XXX
 SG_ B4 : 32|8@1+ (1,0) [0|255] "" Vector__XXX
 SG_ B5 : 40|8@1+ (1,0) [0|255] "" Vector__XXX
 SG_ B6 : 48|8@1+ (1,0) [0|255] "" Vector__XXX
 SG_ B7 : 56|8@1+ (1,0) [0|255] "" Vector__XXX

BA_ "VFrameFormat" BO_ 2550245530 1;
CM_ BO_ 2550245530 "0xB3000006 中通新能源 > 纯电动客车 > 10-12米纯电公交客车 > DCDC 直流变压器 | 0xB3000023 中通新能源 > 纯电动客车 > 6米微巴客车 > DCDC 直流变压器 | 0xB300003E 中通新能源 > 纯电动客车 > 8米纯电公交客车 > DCDC 直流变压器 | 0xB300006B 中通新能源 > 纯电动客车 > 电动新大巴客车 > DCDC 直流变压器 | 0xB30000A0 中通新能源 > 燃料电池客车 > 3KW DC/DC（燃料电池系统散热） | 0xB30000A9 中通新能源 > 澳巴混合动力 > 7米澳巴混合动力客车 > DCDC 直流变压器 | 0xB30000CA 中通新能源 > 澳巴混合动力 > 9米11米澳巴混合动力客车 > DCDC 直流变压器 | 部件: DCDC 直流变压器";

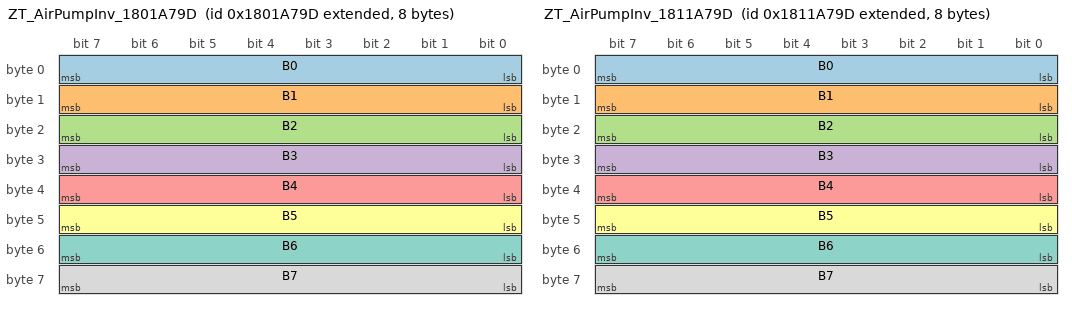
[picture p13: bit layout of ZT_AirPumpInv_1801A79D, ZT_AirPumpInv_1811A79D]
BO_ 2550245277 ZT_AirPumpInv_1801A79D: 8 Vector__XXX
 SG_ B0 : 0|8@1+ (1,0) [0|255] "" Vector__XXX
 SG_ B1 : 8|8@1+ (1,0) [0|255] "" Vector__XXX
 SG_ B2 : 16|8@1+ (1,0) [0|255] "" Vector__XXX
 SG_ B3 : 24|8@1+ (1,0) [0|255] "" Vector__XXX
 SG_ B4 : 32|8@1+ (1,0) [0|255] "" Vector__XXX
 SG_ B5 : 40|8@1+ (1,0) [0|255] "" Vector__XXX
 SG_ B6 : 48|8@1+ (1,0) [0|255] "" Vector__XXX
 SG_ B7 : 56|8@1+ (1,0) [0|255] "" Vector__XXX

BA_ "VFrameFormat" BO_ 2550245277 1;
CM_ BO_ 2550245277 "0xB3000008 中通新能源 > 纯电动客车 > 10-12米纯电公交客车 > 气泵 DC-AC | 0xB3000040 中通新能源 > 纯电动客车 > 8米纯电公交客车 > 气泵 DC-AC | 0xB300006D 中通新能源 > 纯电动客车 > 电动新大巴客车 > 气泵 DC-AC | 0xB3000089 中通新能源 > 燃料电池客车 > 气泵 DC-AC | 0xB30000AA 中通新能源 > 澳巴混合动力 > 7米澳巴混合动力客车 > 气泵 DC-AC | 0xB30000CB 中通新能源 > 澳巴混合动力 > 9米11米澳巴混合动力客车 > 气泵 DC-AC | 部件: 气泵 DC-AC";

BO_ 2551293853 ZT_AirPumpInv_1811A79D: 8 Vector__XXX
 SG_ B0 : 0|8@1+ (1,0) [0|255] "" Vector__XXX
 SG_ B1 : 8|8@1+ (1,0) [0|255] "" Vector__XXX
 SG_ B2 : 16|8@1+ (1,0) [0|255] "" Vector__XXX
 SG_ B3 : 24|8@1+ (1,0) [0|255] "" Vector__XXX
 SG_ B4 : 32|8@1+ (1,0) [0|255] "" Vector__XXX
 SG_ B5 : 40|8@1+ (1,0) [0|255] "" Vector__XXX
 SG_ B6 : 48|8@1+ (1,0) [0|255] "" Vector__XXX
 SG_ B7 : 56|8@1+ (1,0) [0|255] "" Vector__XXX

BA_ "VFrameFormat" BO_ 2551293853 1;
CM_ BO_ 2551293853 "0xB3000008 中通新能源 > 纯电动客车 > 10-12米纯电公交客车 > 气泵 DC-AC | 0xB3000040 中通新能源 > 纯电动客车 > 8米纯电公交客车 > 气泵 DC-AC | 0xB300006D 中通新能源 > 纯电动客车 > 电动新大巴客车 > 气泵 DC-AC | 0xB3000089 中通新能源 > 燃料电池客车 > 气泵 DC-AC | 0xB30000AA 中通新能源 > 澳巴混合动力 > 7米澳巴混合动力客车 > 气泵 DC-AC | 0xB30000CB 中通新能源 > 澳巴混合动力 > 9米11米澳巴混合动力客车 > 气泵 DC-AC | 部件: 气泵 DC-AC";

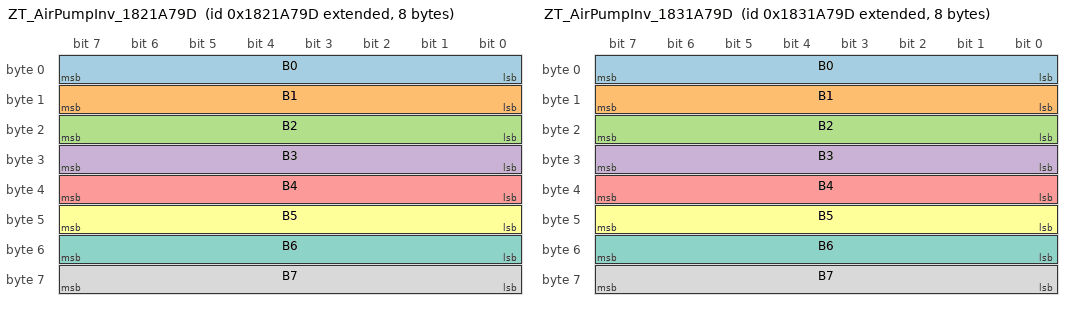
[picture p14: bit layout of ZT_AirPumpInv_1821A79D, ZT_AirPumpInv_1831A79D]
BO_ 2552342429 ZT_AirPumpInv_1821A79D: 8 Vector__XXX
 SG_ B0 : 0|8@1+ (1,0) [0|255] "" Vector__XXX
 SG_ B1 : 8|8@1+ (1,0) [0|255] "" Vector__XXX
 SG_ B2 : 16|8@1+ (1,0) [0|255] "" Vector__XXX
 SG_ B3 : 24|8@1+ (1,0) [0|255] "" Vector__XXX
 SG_ B4 : 32|8@1+ (1,0) [0|255] "" Vector__XXX
 SG_ B5 : 40|8@1+ (1,0) [0|255] "" Vector__XXX
 SG_ B6 : 48|8@1+ (1,0) [0|255] "" Vector__XXX
 SG_ B7 : 56|8@1+ (1,0) [0|255] "" Vector__XXX

BA_ "VFrameFormat" BO_ 2552342429 1;
CM_ BO_ 2552342429 "0xB3000008 中通新能源 > 纯电动客车 > 10-12米纯电公交客车 > 气泵 DC-AC | 0xB3000040 中通新能源 > 纯电动客车 > 8米纯电公交客车 > 气泵 DC-AC | 0xB300006D 中通新能源 > 纯电动客车 > 电动新大巴客车 > 气泵 DC-AC | 0xB3000089 中通新能源 > 燃料电池客车 > 气泵 DC-AC | 0xB30000AA 中通新能源 > 澳巴混合动力 > 7米澳巴混合动力客车 > 气泵 DC-AC | 0xB30000CB 中通新能源 > 澳巴混合动力 > 9米11米澳巴混合动力客车 > 气泵 DC-AC | 部件: 气泵 DC-AC";

BO_ 2553391005 ZT_AirPumpInv_1831A79D: 8 Vector__XXX
 SG_ B0 : 0|8@1+ (1,0) [0|255] "" Vector__XXX
 SG_ B1 : 8|8@1+ (1,0) [0|255] "" Vector__XXX
 SG_ B2 : 16|8@1+ (1,0) [0|255] "" Vector__XXX
 SG_ B3 : 24|8@1+ (1,0) [0|255] "" Vector__XXX
 SG_ B4 : 32|8@1+ (1,0) [0|255] "" Vector__XXX
 SG_ B5 : 40|8@1+ (1,0) [0|255] "" Vector__XXX
 SG_ B6 : 48|8@1+ (1,0) [0|255] "" Vector__XXX
 SG_ B7 : 56|8@1+ (1,0) [0|255] "" Vector__XXX

BA_ "VFrameFormat" BO_ 2553391005 1;
CM_ BO_ 2553391005 "0xB3000008 中通新能源 > 纯电动客车 > 10-12米纯电公交客车 > 气泵 DC-AC | 0xB3000040 中通新能源 > 纯电动客车 > 8米纯电公交客车 > 气泵 DC-AC | 0xB300006D 中通新能源 > 纯电动客车 > 电动新大巴客车 > 气泵 DC-AC | 0xB3000089 中通新能源 > 燃料电池客车 > 气泵 DC-AC | 0xB30000AA 中通新能源 > 澳巴混合动力 > 7米澳巴混合动力客车 > 气泵 DC-AC | 0xB30000CB 中通新能源 > 澳巴混合动力 > 9米11米澳巴混合动力客车 > 气泵 DC-AC | 部件: 气泵 DC-AC";

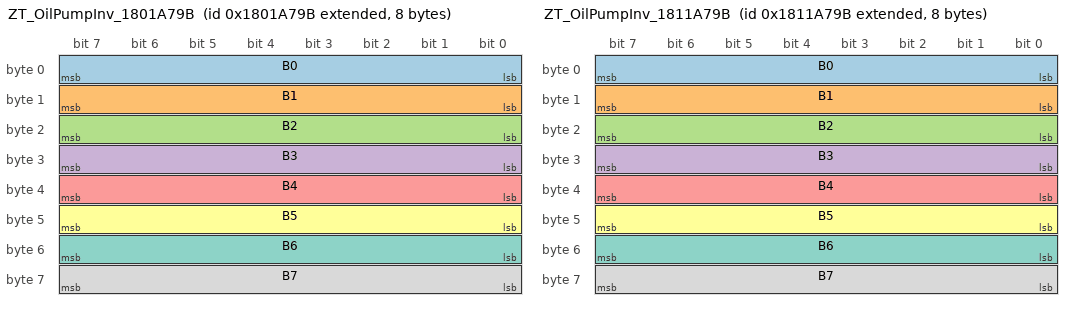
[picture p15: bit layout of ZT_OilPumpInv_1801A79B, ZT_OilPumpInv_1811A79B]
BO_ 2550245275 ZT_OilPumpInv_1801A79B: 8 Vector__XXX
 SG_ B0 : 0|8@1+ (1,0) [0|255] "" Vector__XXX
 SG_ B1 : 8|8@1+ (1,0) [0|255] "" Vector__XXX
 SG_ B2 : 16|8@1+ (1,0) [0|255] "" Vector__XXX
 SG_ B3 : 24|8@1+ (1,0) [0|255] "" Vector__XXX
 SG_ B4 : 32|8@1+ (1,0) [0|255] "" Vector__XXX
 SG_ B5 : 40|8@1+ (1,0) [0|255] "" Vector__XXX
 SG_ B6 : 48|8@1+ (1,0) [0|255] "" Vector__XXX
 SG_ B7 : 56|8@1+ (1,0) [0|255] "" Vector__XXX

BA_ "VFrameFormat" BO_ 2550245275 1;
CM_ BO_ 2550245275 "0xB3000009 中通新能源 > 纯电动客车 > 10-12米纯电公交客车 > 油泵 DC-AC | 0xB3000026 中通新能源 > 纯电动客车 > 6米微巴客车 > 油泵 DC-AC | 0xB3000041 中通新能源 > 纯电动客车 > 8米纯电公交客车 > 油泵 DC-AC | 0xB300006E 中通新能源 > 纯电动客车 > 电动新大巴客车 > 油泵 DC-AC | 0xB300008A 中通新能源 > 燃料电池客车 > 油泵 DC-AC | 0xB30000AB 中通新能源 > 澳巴混合动力 > 7米澳巴混合动力客车 > 油泵 DC-AC | 0xB30000CC 中通新能源 > 澳巴混合动力 > 9米11米澳巴混合动力客车 > 油泵 DC-AC | 部件: 油泵 DC-AC";

BO_ 2551293851 ZT_OilPumpInv_1811A79B: 8 Vector__XXX
 SG_ B0 : 0|8@1+ (1,0) [0|255] "" Vector__XXX
 SG_ B1 : 8|8@1+ (1,0) [0|255] "" Vector__XXX
 SG_ B2 : 16|8@1+ (1,0) [0|255] "" Vector__XXX
 SG_ B3 : 24|8@1+ (1,0) [0|255] "" Vector__XXX
 SG_ B4 : 32|8@1+ (1,0) [0|255] "" Vector__XXX
 SG_ B5 : 40|8@1+ (1,0) [0|255] "" Vector__XXX
 SG_ B6 : 48|8@1+ (1,0) [0|255] "" Vector__XXX
 SG_ B7 : 56|8@1+ (1,0) [0|255] "" Vector__XXX

BA_ "VFrameFormat" BO_ 2551293851 1;
CM_ BO_ 2551293851 "0xB3000009 中通新能源 > 纯电动客车 > 10-12米纯电公交客车 > 油泵 DC-AC | 0xB3000026 中通新能源 > 纯电动客车 > 6米微巴客车 > 油泵 DC-AC | 0xB3000041 中通新能源 > 纯电动客车 > 8米纯电公交客车 > 油泵 DC-AC | 0xB300006E 中通新能源 > 纯电动客车 > 电动新大巴客车 > 油泵 DC-AC | 0xB300008A 中通新能源 > 燃料电池客车 > 油泵 DC-AC | 0xB30000AB 中通新能源 > 澳巴混合动力 > 7米澳巴混合动力客车 > 油泵 DC-AC | 0xB30000CC 中通新能源 > 澳巴混合动力 > 9米11米澳巴混合动力客车 > 油泵 DC-AC | 部件: 油泵 DC-AC";

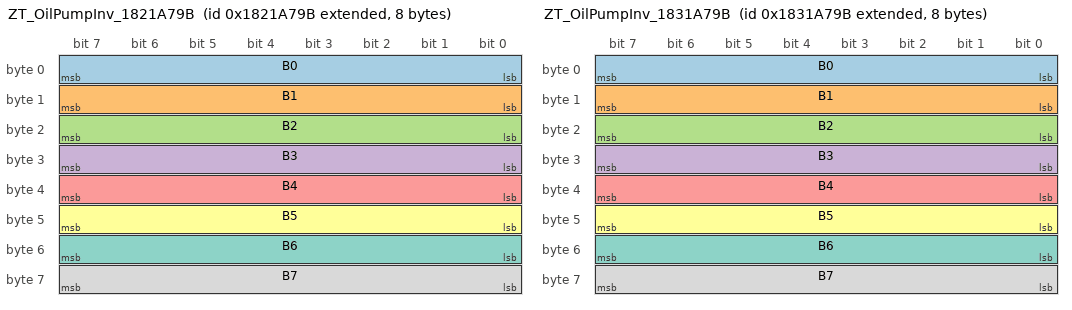
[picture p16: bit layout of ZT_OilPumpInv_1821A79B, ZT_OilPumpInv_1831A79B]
BO_ 2552342427 ZT_OilPumpInv_1821A79B: 8 Vector__XXX
 SG_ B0 : 0|8@1+ (1,0) [0|255] "" Vector__XXX
 SG_ B1 : 8|8@1+ (1,0) [0|255] "" Vector__XXX
 SG_ B2 : 16|8@1+ (1,0) [0|255] "" Vector__XXX
 SG_ B3 : 24|8@1+ (1,0) [0|255] "" Vector__XXX
 SG_ B4 : 32|8@1+ (1,0) [0|255] "" Vector__XXX
 SG_ B5 : 40|8@1+ (1,0) [0|255] "" Vector__XXX
 SG_ B6 : 48|8@1+ (1,0) [0|255] "" Vector__XXX
 SG_ B7 : 56|8@1+ (1,0) [0|255] "" Vector__XXX

BA_ "VFrameFormat" BO_ 2552342427 1;
CM_ BO_ 2552342427 "0xB3000009 中通新能源 > 纯电动客车 > 10-12米纯电公交客车 > 油泵 DC-AC | 0xB3000026 中通新能源 > 纯电动客车 > 6米微巴客车 > 油泵 DC-AC | 0xB3000041 中通新能源 > 纯电动客车 > 8米纯电公交客车 > 油泵 DC-AC | 0xB300006E 中通新能源 > 纯电动客车 > 电动新大巴客车 > 油泵 DC-AC | 0xB300008A 中通新能源 > 燃料电池客车 > 油泵 DC-AC | 0xB30000AB 中通新能源 > 澳巴混合动力 > 7米澳巴混合动力客车 > 油泵 DC-AC | 0xB30000CC 中通新能源 > 澳巴混合动力 > 9米11米澳巴混合动力客车 > 油泵 DC-AC | 部件: 油泵 DC-AC";

BO_ 2553391003 ZT_OilPumpInv_1831A79B: 8 Vector__XXX
 SG_ B0 : 0|8@1+ (1,0) [0|255] "" Vector__XXX
 SG_ B1 : 8|8@1+ (1,0) [0|255] "" Vector__XXX
 SG_ B2 : 16|8@1+ (1,0) [0|255] "" Vector__XXX
 SG_ B3 : 24|8@1+ (1,0) [0|255] "" Vector__XXX
 SG_ B4 : 32|8@1+ (1,0) [0|255] "" Vector__XXX
 SG_ B5 : 40|8@1+ (1,0) [0|255] "" Vector__XXX
 SG_ B6 : 48|8@1+ (1,0) [0|255] "" Vector__XXX
 SG_ B7 : 56|8@1+ (1,0) [0|255] "" Vector__XXX

BA_ "VFrameFormat" BO_ 2553391003 1;
CM_ BO_ 2553391003 "0xB3000009 中通新能源 > 纯电动客车 > 10-12米纯电公交客车 > 油泵 DC-AC | 0xB3000026 中通新能源 > 纯电动客车 > 6米微巴客车 > 油泵 DC-AC | 0xB3000041 中通新能源 > 纯电动客车 > 8米纯电公交客车 > 油泵 DC-AC | 0xB300006E 中通新能源 > 纯电动客车 > 电动新大巴客车 > 油泵 DC-AC | 0xB30000AB 中通新能源 > 澳巴混合动力 > 7米澳巴混合动力客车 > 油泵 DC-AC | 0xB30000CC 中通新能源 > 澳巴混合动力 > 9米11米澳巴混合动力客车 > 油泵 DC-AC | 部件: 油泵 DC-AC";

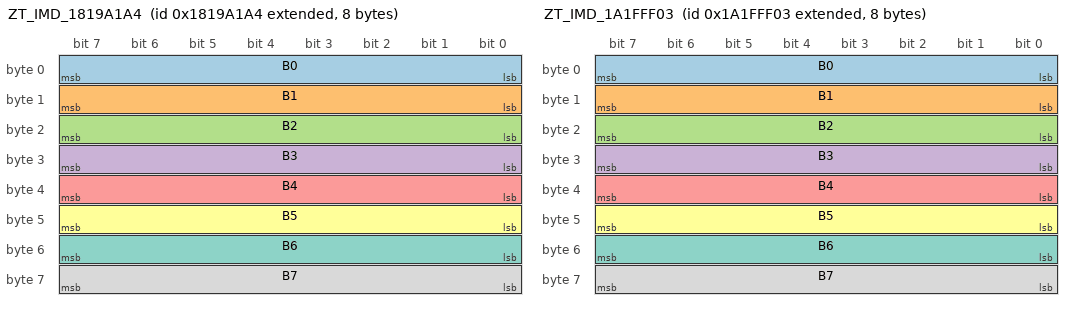
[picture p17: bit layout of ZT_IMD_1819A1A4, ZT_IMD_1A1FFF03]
BO_ 2551816612 ZT_IMD_1819A1A4: 8 Vector__XXX
 SG_ B0 : 0|8@1+ (1,0) [0|255] "" Vector__XXX
 SG_ B1 : 8|8@1+ (1,0) [0|255] "" Vector__XXX
 SG_ B2 : 16|8@1+ (1,0) [0|255] "" Vector__XXX
 SG_ B3 : 24|8@1+ (1,0) [0|255] "" Vector__XXX
 SG_ B4 : 32|8@1+ (1,0) [0|255] "" Vector__XXX
 SG_ B5 : 40|8@1+ (1,0) [0|255] "" Vector__XXX
 SG_ B6 : 48|8@1+ (1,0) [0|255] "" Vector__XXX
 SG_ B7 : 56|8@1+ (1,0) [0|255] "" Vector__XXX

BA_ "VFrameFormat" BO_ 2551816612 1;
CM_ BO_ 2551816612 "0xB300000B 中通新能源 > 纯电动客车 > 10-12米纯电公交客车 > 绝缘检测/监测 | 0xB3000028 中通新能源 > 纯电动客车 > 6米微巴客车 > 绝缘检测/监测 | 0xB3000043 中通新能源 > 纯电动客车 > 8米纯电公交客车 > 绝缘检测/监测 | 0xB300005E 中通新能源 > 纯电动客车 > 轻客6米纯电公交 > 绝缘检测仪 | 0xB3000070 中通新能源 > 纯电动客车 > 电动新大巴客车 > 绝缘检测/监测 | 0xB300008C 中通新能源 > 燃料电池客车 > 绝缘检测/监测 | 0xB30000AD 中通新能源 > 澳巴混合动力 > 7米澳巴混合动力客车 > 绝缘检测/监测 | 0xB30000CE 中通新能源 > 澳巴混合动力 > 9米11米澳巴混合动力客车 > 绝缘检测/监测 | 部件: 绝缘检测/监测";

BO_ 2585788163 ZT_IMD_1A1FFF03: 8 Vector__XXX
 SG_ B0 : 0|8@1+ (1,0) [0|255] "" Vector__XXX
 SG_ B1 : 8|8@1+ (1,0) [0|255] "" Vector__XXX
 SG_ B2 : 16|8@1+ (1,0) [0|255] "" Vector__XXX
 SG_ B3 : 24|8@1+ (1,0) [0|255] "" Vector__XXX
 SG_ B4 : 32|8@1+ (1,0) [0|255] "" Vector__XXX
 SG_ B5 : 40|8@1+ (1,0) [0|255] "" Vector__XXX
 SG_ B6 : 48|8@1+ (1,0) [0|255] "" Vector__XXX
 SG_ B7 : 56|8@1+ (1,0) [0|255] "" Vector__XXX

BA_ "VFrameFormat" BO_ 2585788163 1;
CM_ BO_ 2585788163 "0xB300000B 中通新能源 > 纯电动客车 > 10-12米纯电公交客车 > 绝缘检测/监测 | 0xB3000028 中通新能源 > 纯电动客车 > 6米微巴客车 > 绝缘检测/监测 | 0xB3000043 中通新能源 > 纯电动客车 > 8米纯电公交客车 > 绝缘检测/监测 | 0xB3000070 中通新能源 > 纯电动客车 > 电动新大巴客车 > 绝缘检测/监测 | 0xB30000A2 中通新能源 > 燃料电池客车 > 变速箱控制器 | 0xB30000AD 中通新能源 > 澳巴混合动力 > 7米澳巴混合动力客车 > 绝缘检测/监测 | 0xB30000CE 中通新能源 > 澳巴混合动力 > 9米11米澳巴混合动力客车 > 绝缘检测/监测 | 部件: 绝缘检测/监测";

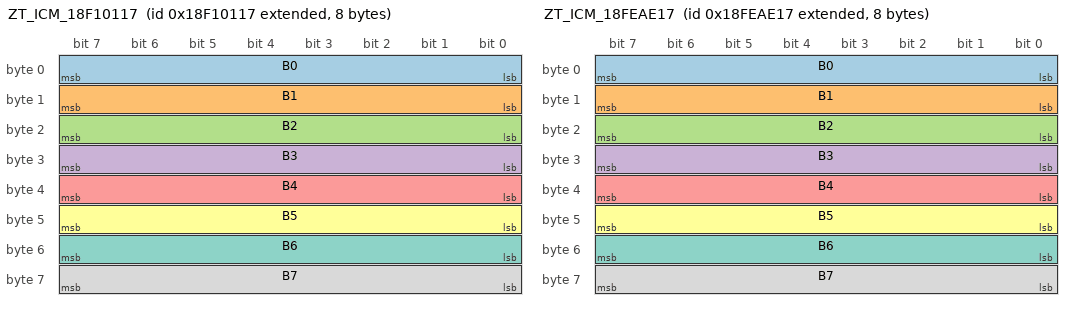
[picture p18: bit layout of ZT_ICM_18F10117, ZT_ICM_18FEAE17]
BO_ 2565931287 ZT_ICM_18F10117: 8 Vector__XXX
 SG_ B0 : 0|8@1+ (1,0) [0|255] "" Vector__XXX
 SG_ B1 : 8|8@1+ (1,0) [0|255] "" Vector__XXX
 SG_ B2 : 16|8@1+ (1,0) [0|255] "" Vector__XXX
 SG_ B3 : 24|8@1+ (1,0) [0|255] "" Vector__XXX
 SG_ B4 : 32|8@1+ (1,0) [0|255] "" Vector__XXX
 SG_ B5 : 40|8@1+ (1,0) [0|255] "" Vector__XXX
 SG_ B6 : 48|8@1+ (1,0) [0|255] "" Vector__XXX
 SG_ B7 : 56|8@1+ (1,0) [0|255] "" Vector__XXX

BA_ "VFrameFormat" BO_ 2565931287 1;
CM_ BO_ 2565931287 "0xB3000014 中通新能源 > 纯电动客车 > 10-12米纯电公交客车 > IC 组合仪表 | 0xB3000031 中通新能源 > 纯电动客车 > 6米微巴客车 > IC 组合仪表 | 0xB300004C 中通新能源 > 纯电动客车 > 8米纯电公交客车 > IC 组合仪表 | 0xB3000079 中通新能源 > 纯电动客车 > 电动新大巴客车 > IC 组合仪表 | 0xB3000095 中通新能源 > 燃料电池客车 > IC 组合仪表 | 0xB30000B6 中通新能源 > 澳巴混合动力 > 7米澳巴混合动力客车 > IC 组合仪表 | 0xB30000D7 中通新能源 > 澳巴混合动力 > 9米11米澳巴混合动力客车 > IC 组合仪表 | 部件: IC 组合仪表";

BO_ 2566827543 ZT_ICM_18FEAE17: 8 Vector__XXX
 SG_ B0 : 0|8@1+ (1,0) [0|255] "" Vector__XXX
 SG_ B1 : 8|8@1+ (1,0) [0|255] "" Vector__XXX
 SG_ B2 : 16|8@1+ (1,0) [0|255] "" Vector__XXX
 SG_ B3 : 24|8@1+ (1,0) [0|255] "" Vector__XXX
 SG_ B4 : 32|8@1+ (1,0) [0|255] "" Vector__XXX
 SG_ B5 : 40|8@1+ (1,0) [0|255] "" Vector__XXX
 SG_ B6 : 48|8@1+ (1,0) [0|255] "" Vector__XXX
 SG_ B7 : 56|8@1+ (1,0) [0|255] "" Vector__XXX

BA_ "VFrameFormat" BO_ 2566827543 1;
CM_ BO_ 2566827543 "0xB3000014 中通新能源 > 纯电动客车 > 10-12米纯电公交客车 > IC 组合仪表 | 0xB3000031 中通新能源 > 纯电动客车 > 6米微巴客车 > IC 组合仪表 | 0xB300004C 中通新能源 > 纯电动客车 > 8米纯电公交客车 > IC 组合仪表 | 0xB3000079 中通新能源 > 纯电动客车 > 电动新大巴客车 > IC 组合仪表 | 0xB3000095 中通新能源 > 燃料电池客车 > IC 组合仪表 | 0xB30000B6 中通新能源 > 澳巴混合动力 > 7米澳巴混合动力客车 > IC 组合仪表 | 0xB30000D7 中通新能源 > 澳巴混合动力 > 9米11米澳巴混合动力客车 > IC 组合仪表 | 部件: IC 组合仪表";

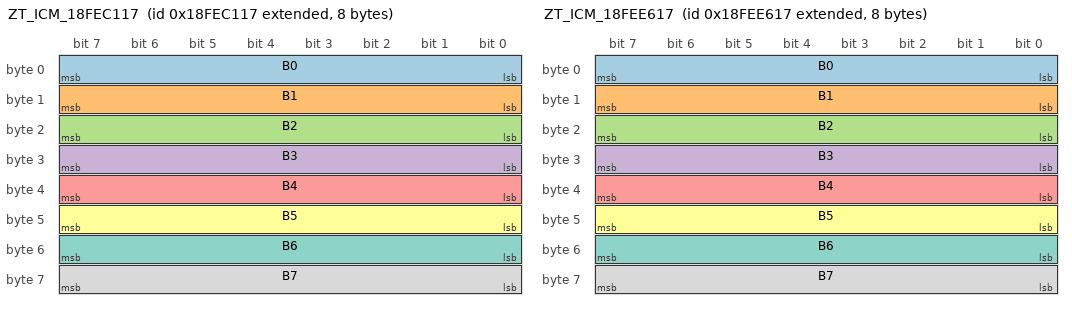
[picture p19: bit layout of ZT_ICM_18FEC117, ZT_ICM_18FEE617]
BO_ 2566832407 ZT_ICM_18FEC117: 8 Vector__XXX
 SG_ B0 : 0|8@1+ (1,0) [0|255] "" Vector__XXX
 SG_ B1 : 8|8@1+ (1,0) [0|255] "" Vector__XXX
 SG_ B2 : 16|8@1+ (1,0) [0|255] "" Vector__XXX
 SG_ B3 : 24|8@1+ (1,0) [0|255] "" Vector__XXX
 SG_ B4 : 32|8@1+ (1,0) [0|255] "" Vector__XXX
 SG_ B5 : 40|8@1+ (1,0) [0|255] "" Vector__XXX
 SG_ B6 : 48|8@1+ (1,0) [0|255] "" Vector__XXX
 SG_ B7 : 56|8@1+ (1,0) [0|255] "" Vector__XXX

BA_ "VFrameFormat" BO_ 2566832407 1;
CM_ BO_ 2566832407 "0xB3000014 中通新能源 > 纯电动客车 > 10-12米纯电公交客车 > IC 组合仪表 | 0xB3000031 中通新能源 > 纯电动客车 > 6米微巴客车 > IC 组合仪表 | 0xB300004C 中通新能源 > 纯电动客车 > 8米纯电公交客车 > IC 组合仪表 | 0xB3000079 中通新能源 > 纯电动客车 > 电动新大巴客车 > IC 组合仪表 | 0xB3000095 中通新能源 > 燃料电池客车 > IC 组合仪表 | 0xB30000B6 中通新能源 > 澳巴混合动力 > 7米澳巴混合动力客车 > IC 组合仪表 | 0xB30000D7 中通新能源 > 澳巴混合动力 > 9米11米澳巴混合动力客车 > IC 组合仪表 | 部件: IC 组合仪表";

BO_ 2566841879 ZT_ICM_18FEE617: 8 Vector__XXX
 SG_ B0 : 0|8@1+ (1,0) [0|255] "" Vector__XXX
 SG_ B1 : 8|8@1+ (1,0) [0|255] "" Vector__XXX
 SG_ B2 : 16|8@1+ (1,0) [0|255] "" Vector__XXX
 SG_ B3 : 24|8@1+ (1,0) [0|255] "" Vector__XXX
 SG_ B4 : 32|8@1+ (1,0) [0|255] "" Vector__XXX
 SG_ B5 : 40|8@1+ (1,0) [0|255] "" Vector__XXX
 SG_ B6 : 48|8@1+ (1,0) [0|255] "" Vector__XXX
 SG_ B7 : 56|8@1+ (1,0) [0|255] "" Vector__XXX

BA_ "VFrameFormat" BO_ 2566841879 1;
CM_ BO_ 2566841879 "0xB3000014 中通新能源 > 纯电动客车 > 10-12米纯电公交客车 > IC 组合仪表 | 0xB3000031 中通新能源 > 纯电动客车 > 6米微巴客车 > IC 组合仪表 | 0xB300004C 中通新能源 > 纯电动客车 > 8米纯电公交客车 > IC 组合仪表 | 0xB3000079 中通新能源 > 纯电动客车 > 电动新大巴客车 > IC 组合仪表 | 0xB3000095 中通新能源 > 燃料电池客车 > IC 组合仪表 | 0xB30000B6 中通新能源 > 澳巴混合动力 > 7米澳巴混合动力客车 > IC 组合仪表 | 0xB30000D7 中通新能源 > 澳巴混合动力 > 9米11米澳巴混合动力客车 > IC 组合仪表 | 部件: IC 组合仪表";

BO_ 2566844695 ZT_ICM_18FEF117: 8 Vector__XXX
 SG_ B0 : 0|8@1+ (1,0) [0|255] "" Vector__XXX
 SG_ B1 : 8|8@1+ (1,0) [0|255] "" Vector__XXX
 SG_ B2 : 16|8@1+ (1,0) [0|255] "" Vector__XXX
 SG_ B3 : 24|8@1+ (1,0) [0|255] "" Vector__XXX
 SG_ B4 : 32|8@1+ (1,0) [0|255] "" Vector__XXX
 SG_ B5 : 40|8@1+ (1,0) [0|255] "" Vector__XXX
 SG_ B6 : 48|8@1+ (1,0) [0|255] "" Vector__XXX
 SG_ B7 : 56|8@1+ (1,0) [0|255] "" Vector__XXX

BA_ "VFrameFormat" BO_ 2566844695 1;
CM_ BO_ 2566844695 "0xB3000014 中通新能源 > 纯电动客车 > 10-12米纯电公交客车 > IC 组合仪表 | 0xB3000031 中通新能源 > 纯电动客车 > 6米微巴客车 > IC 组合仪表 | 0xB300004C 中通新能源 > 纯电动客车 > 8米纯电公交客车 > IC 组合仪表 | 0xB3000079 中通新能源 > 纯电动客车 > 电动新大巴客车 > IC 组合仪表 | 0xB3000095 中通新能源 > 燃料电池客车 > IC 组合仪表 | 0xB30000B6 中通新能源 > 澳巴混合动力 > 7米澳巴混合动力客车 > IC 组合仪表 | 0xB30000D7 中通新能源 > 澳巴混合动力 > 9米11米澳巴混合动力客车 > IC 组合仪表 | 部件: IC 组合仪表";

BO_ 2566898201 ZT_EAC_18FFC219: 8 Vector__XXX
 SG_ B0 : 0|8@1+ (1,0) [0|255] "" Vector__XXX
 SG_ B1 : 8|8@1+ (1,0) [0|255] "" Vector__XXX
 SG_ B2 : 16|8@1+ (1,0) [0|255] "" Vector__XXX
 SG_ B3 : 24|8@1+ (1,0) [0|255] "" Vector__XXX
 SG_ B4 : 32|8@1+ (1,0) [0|255] "" Vector__XXX
 SG_ B5 : 40|8@1+ (1,0) [0|255] "" Vector__XXX
 SG_ B6 : 48|8@1+ (1,0) [0|255] "" Vector__XXX
 SG_ B7 : 56|8@1+ (1,0) [0|255] "" Vector__XXX

BA_ "VFrameFormat" BO_ 2566898201 1;
CM_ BO_ 2566898201 "0xB3000015 中通新能源 > 纯电动客车 > 10-12米纯电公交客车 > 电动空调 | 0xB3000032 中通新能源 > 纯电动客车 > 6米微巴客车 > 电动空调 | 0xB300004D 中通新能源 > 纯电动客车 > 8米纯电公交客车 > 电动空调 | 0xB300007A 中通新能源 > 纯电动客车 > 电动新大巴客车 > 电动空调 | 0xB3000096 中通新能源 > 燃料电池客车 > 电动空调 | 0xB30000D8 中通新能源 > 澳巴混合动力 > 9米11米澳巴混合动力客车 > 电动空调 | 部件: 电动空调";

BO_ 2566898457 ZT_EAC_18FFC319: 8 Vector__XXX
 SG_ B0 : 0|8@1+ (1,0) [0|255] "" Vector__XXX
 SG_ B1 : 8|8@1+ (1,0) [0|255] "" Vector__XXX
 SG_ B2 : 16|8@1+ (1,0) [0|255] "" Vector__XXX
 SG_ B3 : 24|8@1+ (1,0) [0|255] "" Vector__XXX
 SG_ B4 : 32|8@1+ (1,0) [0|255] "" Vector__XXX
 SG_ B5 : 40|8@1+ (1,0) [0|255] "" Vector__XXX
 SG_ B6 : 48|8@1+ (1,0) [0|255] "" Vector__XXX
 SG_ B7 : 56|8@1+ (1,0) [0|255] "" Vector__XXX

BA_ "VFrameFormat" BO_ 2566898457 1;
CM_ BO_ 2566898457 "0xB3000015 中通新能源 > 纯电动客车 > 10-12米纯电公交客车 > 电动空调 | 0xB3000032 中通新能源 > 纯电动客车 > 6米微巴客车 > 电动空调 | 0xB300004D 中通新能源 > 纯电动客车 > 8米纯电公交客车 > 电动空调 | 0xB300007A 中通新能源 > 纯电动客车 > 电动新大巴客车 > 电动空调 | 0xB3000096 中通新能源 > 燃料电池客车 > 电动空调 | 0xB30000D8 中通新能源 > 澳巴混合动力 > 9米11米澳巴混合动力客车 > 电动空调 | 部件: 电动空调";

BO_ 2566898713 ZT_EAC_18FFC419: 8 Vector__XXX
 SG_ B0 : 0|8@1+ (1,0) [0|255] "" Vector__XXX
 SG_ B1 : 8|8@1+ (1,0) [0|255] "" Vector__XXX
 SG_ B2 : 16|8@1+ (1,0) [0|255] "" Vector__XXX
 SG_ B3 : 24|8@1+ (1,0) [0|255] "" Vector__XXX
 SG_ B4 : 32|8@1+ (1,0) [0|255] "" Vector__XXX
 SG_ B5 : 40|8@1+ (1,0) [0|255] "" Vector__XXX
 SG_ B6 : 48|8@1+ (1,0) [0|255] "" Vector__XXX
 SG_ B7 : 56|8@1+ (1,0) [0|255] "" Vector__XXX

BA_ "VFrameFormat" BO_ 2566898713 1;
CM_ BO_ 2566898713 "0xB3000015 中通新能源 > 纯电动客车 > 10-12米纯电公交客车 > 电动空调 | 0xB3000032 中通新能源 > 纯电动客车 > 6米微巴客车 > 电动空调 | 0xB300004D 中通新能源 > 纯电动客车 > 8米纯电公交客车 > 电动空调 | 0xB300007A 中通新能源 > 纯电动客车 > 电动新大巴客车 > 电动空调 | 0xB3000096 中通新能源 > 燃料电池客车 > 电动空调 | 0xB30000D8 中通新能源 > 澳巴混合动力 > 9米11米澳巴混合动力客车 > 电动空调 | 部件: 电动空调";

BO_ 2566898969 ZT_EAC_18FFC519: 8 Vector__XXX
 SG_ B0 : 0|8@1+ (1,0) [0|255] "" Vector__XXX
 SG_ B1 : 8|8@1+ (1,0) [0|255] "" Vector__XXX
 SG_ B2 : 16|8@1+ (1,0) [0|255] "" Vector__XXX
 SG_ B3 : 24|8@1+ (1,0) [0|255] "" Vector__XXX
 SG_ B4 : 32|8@1+ (1,0) [0|255] "" Vector__XXX
 SG_ B5 : 40|8@1+ (1,0) [0|255] "" Vector__XXX
 SG_ B6 : 48|8@1+ (1,0) [0|255] "" Vector__XXX
 SG_ B7 : 56|8@1+ (1,0) [0|255] "" Vector__XXX

BA_ "VFrameFormat" BO_ 2566898969 1;
CM_ BO_ 2566898969 "0xB3000015 中通新能源 > 纯电动客车 > 10-12米纯电公交客车 > 电动空调 | 0xB3000032 中通新能源 > 纯电动客车 > 6米微巴客车 > 电动空调 | 0xB300004D 中通新能源 > 纯电动客车 > 8米纯电公交客车 > 电动空调 | 0xB30000D8 中通新能源 > 澳巴混合动力 > 9米11米澳巴混合动力客车 > 电动空调 | 部件: 电动空调";

BO_ 2566899225 ZT_EAC_18FFC619: 8 Vector__XXX
 SG_ B0 : 0|8@1+ (1,0) [0|255] "" Vector__XXX
 SG_ B1 : 8|8@1+ (1,0) [0|255] "" Vector__XXX
 SG_ B2 : 16|8@1+ (1,0) [0|255] "" Vector__XXX
 SG_ B3 : 24|8@1+ (1,0) [0|255] "" Vector__XXX
 SG_ B4 : 32|8@1+ (1,0) [0|255] "" Vector__XXX
 SG_ B5 : 40|8@1+ (1,0) [0|255] "" Vector__XXX
 SG_ B6 : 48|8@1+ (1,0) [0|255] "" Vector__XXX
 SG_ B7 : 56|8@1+ (1,0) [0|255] "" Vector__XXX

BA_ "VFrameFormat" BO_ 2566899225 1;
CM_ BO_ 2566899225 "0xB3000015 中通新能源 > 纯电动客车 > 10-12米纯电公交客车 > 电动空调 | 0xB3000032 中通新能源 > 纯电动客车 > 6米微巴客车 > 电动空调 | 0xB300004D 中通新能源 > 纯电动客车 > 8米纯电公交客车 > 电动空调 | 部件: 电动空调";

BO_ 2566897978 ZT_TMS_18FFC13A: 8 Vector__XXX
 SG_ B0 : 0|8@1+ (1,0) [0|255] "" Vector__XXX
 SG_ B1 : 8|8@1+ (1,0) [0|255] "" Vector__XXX
 SG_ B2 : 16|8@1+ (1,0) [0|255] "" Vector__XXX
 SG_ B3 : 24|8@1+ (1,0) [0|255] "" Vector__XXX
 SG_ B4 : 32|8@1+ (1,0) [0|255] "" Vector__XXX
 SG_ B5 : 40|8@1+ (1,0) [0|255] "" Vector__XXX
 SG_ B6 : 48|8@1+ (1,0) [0|255] "" Vector__XXX
 SG_ B7 : 56|8@1+ (1,0) [0|255] "" Vector__XXX

BA_ "VFrameFormat" BO_ 2566897978 1;
CM_ BO_ 2566897978 "0xB3000016 中通新能源 > 纯电动客车 > 10-12米纯电公交客车 > TMS 热管理 | 0xB300004E 中通新能源 > 纯电动客车 > 8米纯电公交客车 > TMS 热管理 | 0xB3000097 中通新能源 > 燃料电池客车 > TMS 水冷机组 | 0xB30000C9 中通新能源 > 澳巴混合动力 > 9米11米澳巴混合动力客车 > 电池管理系统 | 部件: TMS 热管理";

BO_ 2354095260 ZT_LVOilPumpCtrl_0C50A49C: 8 Vector__XXX
 SG_ B0 : 0|8@1+ (1,0) [0|255] "" Vector__XXX
 SG_ B1 : 8|8@1+ (1,0) [0|255] "" Vector__XXX
 SG_ B2 : 16|8@1+ (1,0) [0|255] "" Vector__XXX
 SG_ B3 : 24|8@1+ (1,0) [0|255] "" Vector__XXX
 SG_ B4 : 32|8@1+ (1,0) [0|255] "" Vector__XXX
 SG_ B5 : 40|8@1+ (1,0) [0|255] "" Vector__XXX
 SG_ B6 : 48|8@1+ (1,0) [0|255] "" Vector__XXX
 SG_ B7 : 56|8@1+ (1,0) [0|255] "" Vector__XXX

BA_ "VFrameFormat" BO_ 2354095260 1;
CM_ BO_ 2354095260 "0xB3000017 中通新能源 > 纯电动客车 > 10-12米纯电公交客车 > 低压油泵控制器 | 0xB3000034 中通新能源 > 纯电动客车 > 6米微巴客车 > 低压油泵控制器 | 0xB300004F 中通新能源 > 纯电动客车 > 8米纯电公交客车 > 低压油泵控制器 | 0xB3000058 中通新能源 > 纯电动客车 > 轻客6米纯电公交 > VCU 整车控制器 | 0xB300009F 中通新能源 > 燃料电池客车 > 6KW DC/DC（24V电瓶） | 0xB30000C4 中通新能源 > 澳巴混合动力 > 7米澳巴混合动力客车 > RCU 整车控制接收 | 0xB30000E6 中通新能源 > 澳巴混合动力 > 9米11米澳巴混合动力客车 > RCU 整车控制接收 | 部件: 低压油泵控制器";

BO_ 2559352232 ZT_LVOilPumpCtrl_188C9DA8: 8 Vector__XXX
 SG_ B0 : 0|8@1+ (1,0) [0|255] "" Vector__XXX
 SG_ B1 : 8|8@1+ (1,0) [0|255] "" Vector__XXX
 SG_ B2 : 16|8@1+ (1,0) [0|255] "" Vector__XXX
 SG_ B3 : 24|8@1+ (1,0) [0|255] "" Vector__XXX
 SG_ B4 : 32|8@1+ (1,0) [0|255] "" Vector__XXX
 SG_ B5 : 40|8@1+ (1,0) [0|255] "" Vector__XXX
 SG_ B6 : 48|8@1+ (1,0) [0|255] "" Vector__XXX
 SG_ B7 : 56|8@1+ (1,0) [0|255] "" Vector__XXX

BA_ "VFrameFormat" BO_ 2559352232 1;
CM_ BO_ 2559352232 "0xB3000017 中通新能源 > 纯电动客车 > 10-12米纯电公交客车 > 低压油泵控制器 | 0xB3000034 中通新能源 > 纯电动客车 > 6米微巴客车 > 低压油泵控制器 | 0xB300004F 中通新能源 > 纯电动客车 > 8米纯电公交客车 > 低压油泵控制器 | 0xB30000B9 中通新能源 > 澳巴混合动力 > 7米澳巴混合动力客车 > 低压油泵控制器 | 0xB30000DA 中通新能源 > 澳巴混合动力 > 9米11米澳巴混合动力客车 > 低压油泵控制器 | 部件: 低压油泵控制器";

BO_ 2566866420 ZT_ChgCAN_18FF45F4: 8 Vector__XXX
 SG_ B0 : 0|8@1+ (1,0) [0|255] "" Vector__XXX
 SG_ B1 : 8|8@1+ (1,0) [0|255] "" Vector__XXX
 SG_ B2 : 16|8@1+ (1,0) [0|255] "" Vector__XXX
 SG_ B3 : 24|8@1+ (1,0) [0|255] "" Vector__XXX
 SG_ B4 : 32|8@1+ (1,0) [0|255] "" Vector__XXX
 SG_ B5 : 40|8@1+ (1,0) [0|255] "" Vector__XXX
 SG_ B6 : 48|8@1+ (1,0) [0|255] "" Vector__XXX
 SG_ B7 : 56|8@1+ (1,0) [0|255] "" Vector__XXX

BA_ "VFrameFormat" BO_ 2566866420 1;
CM_ BO_ 2566866420 "0xB300001A 中通新能源 > 纯电动客车 > 10-12米纯电公交客车 > 充电 CAN 网络 | 0xB3000052 中通新能源 > 纯电动客车 > 8米纯电公交客车 > 充电 CAN 网络 | 0xB300009B 中通新能源 > 燃料电池客车 > 充电 CAN 网络 | 0xB30000BC 中通新能源 > 澳巴混合动力 > 7米澳巴混合动力客车 > 充电 CAN 网络 | 0xB30000DD 中通新能源 > 澳巴混合动力 > 9米11米澳巴混合动力客车 > 充电 CAN 网络 | 部件: 充电 CAN 网络";

BO_ 2566849200 ZT_RMT_18FF02B0: 8 Vector__XXX
 SG_ B0 : 0|8@1+ (1,0) [0|255] "" Vector__XXX
 SG_ B1 : 8|8@1+ (1,0) [0|255] "" Vector__XXX
 SG_ B2 : 16|8@1+ (1,0) [0|255] "" Vector__XXX
 SG_ B3 : 24|8@1+ (1,0) [0|255] "" Vector__XXX
 SG_ B4 : 32|8@1+ (1,0) [0|255] "" Vector__XXX
 SG_ B5 : 40|8@1+ (1,0) [0|255] "" Vector__XXX
 SG_ B6 : 48|8@1+ (1,0) [0|255] "" Vector__XXX
 SG_ B7 : 56|8@1+ (1,0) [0|255] "" Vector__XXX

BA_ "VFrameFormat" BO_ 2566849200 1;
CM_ BO_ 2566849200 "0xB300001B 中通新能源 > 纯电动客车 > 10-12米纯电公交客车 > 远程监控终端 | 0xB3000037 中通新能源 > 纯电动客车 > 6米微巴客车 > 远程监控终端 | 0xB3000053 中通新能源 > 纯电动客车 > 8米纯电公交客车 > 远程监控终端 | 0xB300007F 中通新能源 > 纯电动客车 > 电动新大巴客车 > 远程监控终端 | 0xB300009C 中通新能源 > 燃料电池客车 > 远程监控终端 | 0xB30000BD 中通新能源 > 澳巴混合动力 > 7米澳巴混合动力客车 > 远程监控终端 | 0xB30000DE 中通新能源 > 澳巴混合动力 > 9米11米澳巴混合动力客车 > 远程监控终端 | 部件: 远程监控终端";

BO_ 2566871633 ZT_Smoke_18FF5A51: 8 Vector__XXX
 SG_ B0 : 0|8@1+ (1,0) [0|255] "" Vector__XXX
 SG_ B1 : 8|8@1+ (1,0) [0|255] "" Vector__XXX
 SG_ B2 : 16|8@1+ (1,0) [0|255] "" Vector__XXX
 SG_ B3 : 24|8@1+ (1,0) [0|255] "" Vector__XXX
 SG_ B4 : 32|8@1+ (1,0) [0|255] "" Vector__XXX
 SG_ B5 : 40|8@1+ (1,0) [0|255] "" Vector__XXX
 SG_ B6 : 48|8@1+ (1,0) [0|255] "" Vector__XXX
 SG_ B7 : 56|8@1+ (1,0) [0|255] "" Vector__XXX

BA_ "VFrameFormat" BO_ 2566871633 1;
CM_ BO_ 2566871633 "0xB300001C 中通新能源 > 纯电动客车 > 10-12米纯电公交客车 > 烟雾报警/灭火 | 0xB3000054 中通新能源 > 纯电动客车 > 8米纯电公交客车 > 烟雾报警/灭火 | 0xB3000080 中通新能源 > 纯电动客车 > 电动新大巴客车 > 烟雾报警/灭火 | 0xB30000E1 中通新能源 > 澳巴混合动力 > 9米11米澳巴混合动力客车 > 烟雾报警模块 | 部件: 烟雾报警/灭火";

BO_ 2559574255 ZT_VCU_189000EF: 8 Vector__XXX
 SG_ B0 : 0|8@1+ (1,0) [0|255] "" Vector__XXX
 SG_ B1 : 8|8@1+ (1,0) [0|255] "" Vector__XXX
 SG_ B2 : 16|8@1+ (1,0) [0|255] "" Vector__XXX
 SG_ B3 : 24|8@1+ (1,0) [0|255] "" Vector__XXX
 SG_ B4 : 32|8@1+ (1,0) [0|255] "" Vector__XXX
 SG_ B5 : 40|8@1+ (1,0) [0|255] "" Vector__XXX
 SG_ B6 : 48|8@1+ (1,0) [0|255] "" Vector__XXX
 SG_ B7 : 56|8@1+ (1,0) [0|255] "" Vector__XXX

BA_ "VFrameFormat" BO_ 2559574255 1;
CM_ BO_ 2559574255 "0xB300001F 中通新能源 > 纯电动客车 > 6米微巴客车 > VCU 整车控制器 | 0xB3000083 中通新能源 > 燃料电池客车 > VCU 整车控制器 | 部件: VCU 整车控制器";

BO_ 2566899183 ZT_VCU_18FFC5EF: 8 Vector__XXX
 SG_ B0 : 0|8@1+ (1,0) [0|255] "" Vector__XXX
 SG_ B1 : 8|8@1+ (1,0) [0|255] "" Vector__XXX
 SG_ B2 : 16|8@1+ (1,0) [0|255] "" Vector__XXX
 SG_ B3 : 24|8@1+ (1,0) [0|255] "" Vector__XXX
 SG_ B4 : 32|8@1+ (1,0) [0|255] "" Vector__XXX
 SG_ B5 : 40|8@1+ (1,0) [0|255] "" Vector__XXX
 SG_ B6 : 48|8@1+ (1,0) [0|255] "" Vector__XXX
 SG_ B7 : 56|8@1+ (1,0) [0|255] "" Vector__XXX

BA_ "VFrameFormat" BO_ 2566899183 1;
CM_ BO_ 2566899183 "0xB300001F 中通新能源 > 纯电动客车 > 6米微巴客车 > VCU 整车控制器 | 部件: VCU 整车控制器";

BO_ 2566000663 ZT_ICM_18F21017: 8 Vector__XXX
 SG_ B0 : 0|8@1+ (1,0) [0|255] "" Vector__XXX
 SG_ B1 : 8|8@1+ (1,0) [0|255] "" Vector__XXX
 SG_ B2 : 16|8@1+ (1,0) [0|255] "" Vector__XXX
 SG_ B3 : 24|8@1+ (1,0) [0|255] "" Vector__XXX
 SG_ B4 : 32|8@1+ (1,0) [0|255] "" Vector__XXX
 SG_ B5 : 40|8@1+ (1,0) [0|255] "" Vector__XXX
 SG_ B6 : 48|8@1+ (1,0) [0|255] "" Vector__XXX
 SG_ B7 : 56|8@1+ (1,0) [0|255] "" Vector__XXX

BA_ "VFrameFormat" BO_ 2566000663 1;
CM_ BO_ 2566000663 "0xB3000031 中通新能源 > 纯电动客车 > 6米微巴客车 > IC 组合仪表 | 0xB30000B6 中通新能源 > 澳巴混合动力 > 7米澳巴混合动力客车 > IC 组合仪表 | 部件: IC 组合仪表";

BO_ 2264865011 ZT_BMS_06FF18F3: 8 Vector__XXX
 SG_ B0 : 0|8@1+ (1,0) [0|255] "" Vector__XXX
 SG_ B1 : 8|8@1+ (1,0) [0|255] "" Vector__XXX
 SG_ B2 : 16|8@1+ (1,0) [0|255] "" Vector__XXX
 SG_ B3 : 24|8@1+ (1,0) [0|255] "" Vector__XXX
 SG_ B4 : 32|8@1+ (1,0) [0|255] "" Vector__XXX
 SG_ B5 : 40|8@1+ (1,0) [0|255] "" Vector__XXX
 SG_ B6 : 48|8@1+ (1,0) [0|255] "" Vector__XXX
 SG_ B7 : 56|8@1+ (1,0) [0|255] "" Vector__XXX

BA_ "VFrameFormat" BO_ 2264865011 1;
CM_ BO_ 2264865011 "0xB3000057 中通新能源 > 纯电动客车 > 轻客6米纯电公交 > BMS 电池管理系统 | 部件: BMS 电池管理系统";

BO_ 2365553923 ZT_BMS_0CFF7D03: 8 Vector__XXX
 SG_ B0 : 0|8@1+ (1,0) [0|255] "" Vector__XXX
 SG_ B1 : 8|8@1+ (1,0) [0|255] "" Vector__XXX
 SG_ B2 : 16|8@1+ (1,0) [0|255] "" Vector__XXX
 SG_ B3 : 24|8@1+ (1,0) [0|255] "" Vector__XXX
 SG_ B4 : 32|8@1+ (1,0) [0|255] "" Vector__XXX
 SG_ B5 : 40|8@1+ (1,0) [0|255] "" Vector__XXX
 SG_ B6 : 48|8@1+ (1,0) [0|255] "" Vector__XXX
 SG_ B7 : 56|8@1+ (1,0) [0|255] "" Vector__XXX

BA_ "VFrameFormat" BO_ 2365553923 1;
CM_ BO_ 2365553923 "0xB3000057 中通新能源 > 纯电动客车 > 轻客6米纯电公交 > BMS 电池管理系统 | 部件: BMS 电池管理系统";

BO_ 2365554179 ZT_BMS_0CFF7E03: 8 Vector__XXX
 SG_ B0 : 0|8@1+ (1,0) [0|255] "" Vector__XXX
 SG_ B1 : 8|8@1+ (1,0) [0|255] "" Vector__XXX
 SG_ B2 : 16|8@1+ (1,0) [0|255] "" Vector__XXX
 SG_ B3 : 24|8@1+ (1,0) [0|255] "" Vector__XXX
 SG_ B4 : 32|8@1+ (1,0) [0|255] "" Vector__XXX
 SG_ B5 : 40|8@1+ (1,0) [0|255] "" Vector__XXX
 SG_ B6 : 48|8@1+ (1,0) [0|255] "" Vector__XXX
 SG_ B7 : 56|8@1+ (1,0) [0|255] "" Vector__XXX

BA_ "VFrameFormat" BO_ 2365554179 1;
CM_ BO_ 2365554179 "0xB3000057 中通新能源 > 纯电动客车 > 轻客6米纯电公交 > BMS 电池管理系统 | 部件: BMS 电池管理系统";

BO_ 2365554435 ZT_BMS_0CFF7F03: 8 Vector__XXX
 SG_ B0 : 0|8@1+ (1,0) [0|255] "" Vector__XXX
 SG_ B1 : 8|8@1+ (1,0) [0|255] "" Vector__XXX
 SG_ B2 : 16|8@1+ (1,0) [0|255] "" Vector__XXX
 SG_ B3 : 24|8@1+ (1,0) [0|255] "" Vector__XXX
 SG_ B4 : 32|8@1+ (1,0) [0|255] "" Vector__XXX
 SG_ B5 : 40|8@1+ (1,0) [0|255] "" Vector__XXX
 SG_ B6 : 48|8@1+ (1,0) [0|255] "" Vector__XXX
 SG_ B7 : 56|8@1+ (1,0) [0|255] "" Vector__XXX

BA_ "VFrameFormat" BO_ 2365554435 1;
CM_ BO_ 2365554435 "0xB3000057 中通新能源 > 纯电动客车 > 轻客6米纯电公交 > BMS 电池管理系统 | 部件: BMS 电池管理系统";

BO_ 2365554691 ZT_BMS_0CFF8003: 8 Vector__XXX
 SG_ B0 : 0|8@1+ (1,0) [0|255] "" Vector__XXX
 SG_ B1 : 8|8@1+ (1,0) [0|255] "" Vector__XXX
 SG_ B2 : 16|8@1+ (1,0) [0|255] "" Vector__XXX
 SG_ B3 : 24|8@1+ (1,0) [0|255] "" Vector__XXX
 SG_ B4 : 32|8@1+ (1,0) [0|255] "" Vector__XXX
 SG_ B5 : 40|8@1+ (1,0) [0|255] "" Vector__XXX
 SG_ B6 : 48|8@1+ (1,0) [0|255] "" Vector__XXX
 SG_ B7 : 56|8@1+ (1,0) [0|255] "" Vector__XXX

BA_ "VFrameFormat" BO_ 2365554691 1;
CM_ BO_ 2365554691 "0xB3000057 中通新能源 > 纯电动客车 > 轻客6米纯电公交 > BMS 电池管理系统 | 部件: BMS 电池管理系统";

BO_ 2365554947 ZT_BMS_0CFF8103: 8 Vector__XXX
 SG_ B0 : 0|8@1+ (1,0) [0|255] "" Vector__XXX
 SG_ B1 : 8|8@1+ (1,0) [0|255] "" Vector__XXX
 SG_ B2 : 16|8@1+ (1,0) [0|255] "" Vector__XXX
 SG_ B3 : 24|8@1+ (1,0) [0|255] "" Vector__XXX
 SG_ B4 : 32|8@1+ (1,0) [0|255] "" Vector__XXX
 SG_ B5 : 40|8@1+ (1,0) [0|255] "" Vector__XXX
 SG_ B6 : 48|8@1+ (1,0) [0|255] "" Vector__XXX
 SG_ B7 : 56|8@1+ (1,0) [0|255] "" Vector__XXX

BA_ "VFrameFormat" BO_ 2365554947 1;
CM_ BO_ 2365554947 "0xB3000057 中通新能源 > 纯电动客车 > 轻客6米纯电公交 > BMS 电池管理系统 | 部件: BMS 电池管理系统";

BO_ 2365555203 ZT_BMS_0CFF8203: 8 Vector__XXX
 SG_ B0 : 0|8@1+ (1,0) [0|255] "" Vector__XXX
 SG_ B1 : 8|8@1+ (1,0) [0|255] "" Vector__XXX
 SG_ B2 : 16|8@1+ (1,0) [0|255] "" Vector__XXX
 SG_ B3 : 24|8@1+ (1,0) [0|255] "" Vector__XXX
 SG_ B4 : 32|8@1+ (1,0) [0|255] "" Vector__XXX
 SG_ B5 : 40|8@1+ (1,0) [0|255] "" Vector__XXX
 SG_ B6 : 48|8@1+ (1,0) [0|255] "" Vector__XXX
 SG_ B7 : 56|8@1+ (1,0) [0|255] "" Vector__XXX

BA_ "VFrameFormat" BO_ 2365555203 1;
CM_ BO_ 2365555203 "0xB3000057 中通新能源 > 纯电动客车 > 轻客6米纯电公交 > BMS 电池管理系统 | 部件: BMS 电池管理系统";

BO_ 2550193155 ZT_BMS_1800DC03: 8 Vector__XXX
 SG_ B0 : 0|8@1+ (1,0) [0|255] "" Vector__XXX
 SG_ B1 : 8|8@1+ (1,0) [0|255] "" Vector__XXX
 SG_ B2 : 16|8@1+ (1,0) [0|255] "" Vector__XXX
 SG_ B3 : 24|8@1+ (1,0) [0|255] "" Vector__XXX
 SG_ B4 : 32|8@1+ (1,0) [0|255] "" Vector__XXX
 SG_ B5 : 40|8@1+ (1,0) [0|255] "" Vector__XXX
 SG_ B6 : 48|8@1+ (1,0) [0|255] "" Vector__XXX
 SG_ B7 : 56|8@1+ (1,0) [0|255] "" Vector__XXX

BA_ "VFrameFormat" BO_ 2550193155 1;
CM_ BO_ 2550193155 "0xB3000057 中通新能源 > 纯电动客车 > 轻客6米纯电公交 > BMS 电池管理系统 | 部件: BMS 电池管理系统";

BO_ 2550193411 ZT_BMS_1800DD03: 8 Vector__XXX
 SG_ B0 : 0|8@1+ (1,0) [0|255] "" Vector__XXX
 SG_ B1 : 8|8@1+ (1,0) [0|255] "" Vector__XXX
 SG_ B2 : 16|8@1+ (1,0) [0|255] "" Vector__XXX
 SG_ B3 : 24|8@1+ (1,0) [0|255] "" Vector__XXX
 SG_ B4 : 32|8@1+ (1,0) [0|255] "" Vector__XXX
 SG_ B5 : 40|8@1+ (1,0) [0|255] "" Vector__XXX
 SG_ B6 : 48|8@1+ (1,0) [0|255] "" Vector__XXX
 SG_ B7 : 56|8@1+ (1,0) [0|255] "" Vector__XXX

BA_ "VFrameFormat" BO_ 2550193411 1;
CM_ BO_ 2550193411 "0xB3000057 中通新能源 > 纯电动客车 > 轻客6米纯电公交 > BMS 电池管理系统 | 部件: BMS 电池管理系统";

BO_ 2550258691 ZT_BMS_1801DC03: 8 Vector__XXX
 SG_ B0 : 0|8@1+ (1,0) [0|255] "" Vector__XXX
 SG_ B1 : 8|8@1+ (1,0) [0|255] "" Vector__XXX
 SG_ B2 : 16|8@1+ (1,0) [0|255] "" Vector__XXX
 SG_ B3 : 24|8@1+ (1,0) [0|255] "" Vector__XXX
 SG_ B4 : 32|8@1+ (1,0) [0|255] "" Vector__XXX
 SG_ B5 : 40|8@1+ (1,0) [0|255] "" Vector__XXX
 SG_ B6 : 48|8@1+ (1,0) [0|255] "" Vector__XXX
 SG_ B7 : 56|8@1+ (1,0) [0|255] "" Vector__XXX

BA_ "VFrameFormat" BO_ 2550258691 1;
CM_ BO_ 2550258691 "0xB3000057 中通新能源 > 纯电动客车 > 轻客6米纯电公交 > BMS 电池管理系统 | 部件: BMS 电池管理系统";

BO_ 2550258947 ZT_BMS_1801DD03: 8 Vector__XXX
 SG_ B0 : 0|8@1+ (1,0) [0|255] "" Vector__XXX
 SG_ B1 : 8|8@1+ (1,0) [0|255] "" Vector__XXX
 SG_ B2 : 16|8@1+ (1,0) [0|255] "" Vector__XXX
 SG_ B3 : 24|8@1+ (1,0) [0|255] "" Vector__XXX
 SG_ B4 : 32|8@1+ (1,0) [0|255] "" Vector__XXX
 SG_ B5 : 40|8@1+ (1,0) [0|255] "" Vector__XXX
 SG_ B6 : 48|8@1+ (1,0) [0|255] "" Vector__XXX
 SG_ B7 : 56|8@1+ (1,0) [0|255] "" Vector__XXX

BA_ "VFrameFormat" BO_ 2550258947 1;
CM_ BO_ 2550258947 "0xB3000057 中通新能源 > 纯电动客车 > 轻客6米纯电公交 > BMS 电池管理系统 | 部件: BMS 电池管理系统";

BO_ 2550324227 ZT_BMS_1802DC03: 8 Vector__XXX
 SG_ B0 : 0|8@1+ (1,0) [0|255] "" Vector__XXX
 SG_ B1 : 8|8@1+ (1,0) [0|255] "" Vector__XXX
 SG_ B2 : 16|8@1+ (1,0) [0|255] "" Vector__XXX
 SG_ B3 : 24|8@1+ (1,0) [0|255] "" Vector__XXX
 SG_ B4 : 32|8@1+ (1,0) [0|255] "" Vector__XXX
 SG_ B5 : 40|8@1+ (1,0) [0|255] "" Vector__XXX
 SG_ B6 : 48|8@1+ (1,0) [0|255] "" Vector__XXX
 SG_ B7 : 56|8@1+ (1,0) [0|255] "" Vector__XXX

BA_ "VFrameFormat" BO_ 2550324227 1;
CM_ BO_ 2550324227 "0xB3000057 中通新能源 > 纯电动客车 > 轻客6米纯电公交 > BMS 电池管理系统 | 部件: BMS 电池管理系统";

BO_ 2550324483 ZT_BMS_1802DD03: 8 Vector__XXX
 SG_ B0 : 0|8@1+ (1,0) [0|255] "" Vector__XXX
 SG_ B1 : 8|8@1+ (1,0) [0|255] "" Vector__XXX
 SG_ B2 : 16|8@1+ (1,0) [0|255] "" Vector__XXX
 SG_ B3 : 24|8@1+ (1,0) [0|255] "" Vector__XXX
 SG_ B4 : 32|8@1+ (1,0) [0|255] "" Vector__XXX
 SG_ B5 : 40|8@1+ (1,0) [0|255] "" Vector__XXX
 SG_ B6 : 48|8@1+ (1,0) [0|255] "" Vector__XXX
 SG_ B7 : 56|8@1+ (1,0) [0|255] "" Vector__XXX

BA_ "VFrameFormat" BO_ 2550324483 1;
CM_ BO_ 2550324483 "0xB3000057 中通新能源 > 纯电动客车 > 轻客6米纯电公交 > BMS 电池管理系统 | 部件: BMS 电池管理系统";

BO_ 2550389763 ZT_BMS_1803DC03: 8 Vector__XXX
 SG_ B0 : 0|8@1+ (1,0) [0|255] "" Vector__XXX
 SG_ B1 : 8|8@1+ (1,0) [0|255] "" Vector__XXX
 SG_ B2 : 16|8@1+ (1,0) [0|255] "" Vector__XXX
 SG_ B3 : 24|8@1+ (1,0) [0|255] "" Vector__XXX
 SG_ B4 : 32|8@1+ (1,0) [0|255] "" Vector__XXX
 SG_ B5 : 40|8@1+ (1,0) [0|255] "" Vector__XXX
 SG_ B6 : 48|8@1+ (1,0) [0|255] "" Vector__XXX
 SG_ B7 : 56|8@1+ (1,0) [0|255] "" Vector__XXX

BA_ "VFrameFormat" BO_ 2550389763 1;
CM_ BO_ 2550389763 "0xB3000057 中通新能源 > 纯电动客车 > 轻客6米纯电公交 > BMS 电池管理系统 | 部件: BMS 电池管理系统";

BO_ 2550390019 ZT_BMS_1803DD03: 8 Vector__XXX
 SG_ B0 : 0|8@1+ (1,0) [0|255] "" Vector__XXX
 SG_ B1 : 8|8@1+ (1,0) [0|255] "" Vector__XXX
 SG_ B2 : 16|8@1+ (1,0) [0|255] "" Vector__XXX
 SG_ B3 : 24|8@1+ (1,0) [0|255] "" Vector__XXX
 SG_ B4 : 32|8@1+ (1,0) [0|255] "" Vector__XXX
 SG_ B5 : 40|8@1+ (1,0) [0|255] "" Vector__XXX
 SG_ B6 : 48|8@1+ (1,0) [0|255] "" Vector__XXX
 SG_ B7 : 56|8@1+ (1,0) [0|255] "" Vector__XXX

BA_ "VFrameFormat" BO_ 2550390019 1;
CM_ BO_ 2550390019 "0xB3000057 中通新能源 > 纯电动客车 > 轻客6米纯电公交 > BMS 电池管理系统 | 部件: BMS 电池管理系统";

BO_ 2550455299 ZT_BMS_1804DC03: 8 Vector__XXX
 SG_ B0 : 0|8@1+ (1,0) [0|255] "" Vector__XXX
 SG_ B1 : 8|8@1+ (1,0) [0|255] "" Vector__XXX
 SG_ B2 : 16|8@1+ (1,0) [0|255] "" Vector__XXX
 SG_ B3 : 24|8@1+ (1,0) [0|255] "" Vector__XXX
 SG_ B4 : 32|8@1+ (1,0) [0|255] "" Vector__XXX
 SG_ B5 : 40|8@1+ (1,0) [0|255] "" Vector__XXX
 SG_ B6 : 48|8@1+ (1,0) [0|255] "" Vector__XXX
 SG_ B7 : 56|8@1+ (1,0) [0|255] "" Vector__XXX

BA_ "VFrameFormat" BO_ 2550455299 1;
CM_ BO_ 2550455299 "0xB3000057 中通新能源 > 纯电动客车 > 轻客6米纯电公交 > BMS 电池管理系统 | 部件: BMS 电池管理系统";

BO_ 2550455555 ZT_BMS_1804DD03: 8 Vector__XXX
 SG_ B0 : 0|8@1+ (1,0) [0|255] "" Vector__XXX
 SG_ B1 : 8|8@1+ (1,0) [0|255] "" Vector__XXX
 SG_ B2 : 16|8@1+ (1,0) [0|255] "" Vector__XXX
 SG_ B3 : 24|8@1+ (1,0) [0|255] "" Vector__XXX
 SG_ B4 : 32|8@1+ (1,0) [0|255] "" Vector__XXX
 SG_ B5 : 40|8@1+ (1,0) [0|255] "" Vector__XXX
 SG_ B6 : 48|8@1+ (1,0) [0|255] "" Vector__XXX
 SG_ B7 : 56|8@1+ (1,0) [0|255] "" Vector__XXX

BA_ "VFrameFormat" BO_ 2550455555 1;
CM_ BO_ 2550455555 "0xB3000057 中通新能源 > 纯电动客车 > 轻客6米纯电公交 > BMS 电池管理系统 | 部件: BMS 电池管理系统";

BO_ 2550520835 ZT_BMS_1805DC03: 8 Vector__XXX
 SG_ B0 : 0|8@1+ (1,0) [0|255] "" Vector__XXX
 SG_ B1 : 8|8@1+ (1,0) [0|255] "" Vector__XXX
 SG_ B2 : 16|8@1+ (1,0) [0|255] "" Vector__XXX
 SG_ B3 : 24|8@1+ (1,0) [0|255] "" Vector__XXX
 SG_ B4 : 32|8@1+ (1,0) [0|255] "" Vector__XXX
 SG_ B5 : 40|8@1+ (1,0) [0|255] "" Vector__XXX
 SG_ B6 : 48|8@1+ (1,0) [0|255] "" Vector__XXX
 SG_ B7 : 56|8@1+ (1,0) [0|255] "" Vector__XXX

BA_ "VFrameFormat" BO_ 2550520835 1;
CM_ BO_ 2550520835 "0xB3000057 中通新能源 > 纯电动客车 > 轻客6米纯电公交 > BMS 电池管理系统 | 部件: BMS 电池管理系统";

BO_ 2550521091 ZT_BMS_1805DD03: 8 Vector__XXX
 SG_ B0 : 0|8@1+ (1,0) [0|255] "" Vector__XXX
 SG_ B1 : 8|8@1+ (1,0) [0|255] "" Vector__XXX
 SG_ B2 : 16|8@1+ (1,0) [0|255] "" Vector__XXX
 SG_ B3 : 24|8@1+ (1,0) [0|255] "" Vector__XXX
 SG_ B4 : 32|8@1+ (1,0) [0|255] "" Vector__XXX
 SG_ B5 : 40|8@1+ (1,0) [0|255] "" Vector__XXX
 SG_ B6 : 48|8@1+ (1,0) [0|255] "" Vector__XXX
 SG_ B7 : 56|8@1+ (1,0) [0|255] "" Vector__XXX

BA_ "VFrameFormat" BO_ 2550521091 1;
CM_ BO_ 2550521091 "0xB3000057 中通新能源 > 纯电动客车 > 轻客6米纯电公交 > BMS 电池管理系统 | 部件: BMS 电池管理系统";

BO_ 2550586371 ZT_BMS_1806DC03: 8 Vector__XXX
 SG_ B0 : 0|8@1+ (1,0) [0|255] "" Vector__XXX
 SG_ B1 : 8|8@1+ (1,0) [0|255] "" Vector__XXX
 SG_ B2 : 16|8@1+ (1,0) [0|255] "" Vector__XXX
 SG_ B3 : 24|8@1+ (1,0) [0|255] "" Vector__XXX
 SG_ B4 : 32|8@1+ (1,0) [0|255] "" Vector__XXX
 SG_ B5 : 40|8@1+ (1,0) [0|255] "" Vector__XXX
 SG_ B6 : 48|8@1+ (1,0) [0|255] "" Vector__XXX
 SG_ B7 : 56|8@1+ (1,0) [0|255] "" Vector__XXX

BA_ "VFrameFormat" BO_ 2550586371 1;
CM_ BO_ 2550586371 "0xB3000057 中通新能源 > 纯电动客车 > 轻客6米纯电公交 > BMS 电池管理系统 | 部件: BMS 电池管理系统";

BO_ 2550651907 ZT_BMS_1807DC03: 8 Vector__XXX
 SG_ B0 : 0|8@1+ (1,0) [0|255] "" Vector__XXX
 SG_ B1 : 8|8@1+ (1,0) [0|255] "" Vector__XXX
 SG_ B2 : 16|8@1+ (1,0) [0|255] "" Vector__XXX
 SG_ B3 : 24|8@1+ (1,0) [0|255] "" Vector__XXX
 SG_ B4 : 32|8@1+ (1,0) [0|255] "" Vector__XXX
 SG_ B5 : 40|8@1+ (1,0) [0|255] "" Vector__XXX
 SG_ B6 : 48|8@1+ (1,0) [0|255] "" Vector__XXX
 SG_ B7 : 56|8@1+ (1,0) [0|255] "" Vector__XXX

BA_ "VFrameFormat" BO_ 2550651907 1;
CM_ BO_ 2550651907 "0xB3000057 中通新能源 > 纯电动客车 > 轻客6米纯电公交 > BMS 电池管理系统 | 部件: BMS 电池管理系统";

BO_ 2550717443 ZT_BMS_1808DC03: 8 Vector__XXX
 SG_ B0 : 0|8@1+ (1,0) [0|255] "" Vector__XXX
 SG_ B1 : 8|8@1+ (1,0) [0|255] "" Vector__XXX
 SG_ B2 : 16|8@1+ (1,0) [0|255] "" Vector__XXX
 SG_ B3 : 24|8@1+ (1,0) [0|255] "" Vector__XXX
 SG_ B4 : 32|8@1+ (1,0) [0|255] "" Vector__XXX
 SG_ B5 : 40|8@1+ (1,0) [0|255] "" Vector__XXX
 SG_ B6 : 48|8@1+ (1,0) [0|255] "" Vector__XXX
 SG_ B7 : 56|8@1+ (1,0) [0|255] "" Vector__XXX

BA_ "VFrameFormat" BO_ 2550717443 1;
CM_ BO_ 2550717443 "0xB3000057 中通新能源 > 纯电动客车 > 轻客6米纯电公交 > BMS 电池管理系统 | 部件: BMS 电池管理系统";

BO_ 2550782979 ZT_BMS_1809DC03: 8 Vector__XXX
 SG_ B0 : 0|8@1+ (1,0) [0|255] "" Vector__XXX
 SG_ B1 : 8|8@1+ (1,0) [0|255] "" Vector__XXX
 SG_ B2 : 16|8@1+ (1,0) [0|255] "" Vector__XXX
 SG_ B3 : 24|8@1+ (1,0) [0|255] "" Vector__XXX
 SG_ B4 : 32|8@1+ (1,0) [0|255] "" Vector__XXX
 SG_ B5 : 40|8@1+ (1,0) [0|255] "" Vector__XXX
 SG_ B6 : 48|8@1+ (1,0) [0|255] "" Vector__XXX
 SG_ B7 : 56|8@1+ (1,0) [0|255] "" Vector__XXX

BA_ "VFrameFormat" BO_ 2550782979 1;
CM_ BO_ 2550782979 "0xB3000057 中通新能源 > 纯电动客车 > 轻客6米纯电公交 > BMS 电池管理系统 | 部件: BMS 电池管理系统";

BO_ 2550848515 ZT_BMS_180ADC03: 8 Vector__XXX
 SG_ B0 : 0|8@1+ (1,0) [0|255] "" Vector__XXX
 SG_ B1 : 8|8@1+ (1,0) [0|255] "" Vector__XXX
 SG_ B2 : 16|8@1+ (1,0) [0|255] "" Vector__XXX
 SG_ B3 : 24|8@1+ (1,0) [0|255] "" Vector__XXX
 SG_ B4 : 32|8@1+ (1,0) [0|255] "" Vector__XXX
 SG_ B5 : 40|8@1+ (1,0) [0|255] "" Vector__XXX
 SG_ B6 : 48|8@1+ (1,0) [0|255] "" Vector__XXX
 SG_ B7 : 56|8@1+ (1,0) [0|255] "" Vector__XXX

BA_ "VFrameFormat" BO_ 2550848515 1;
CM_ BO_ 2550848515 "0xB3000057 中通新能源 > 纯电动客车 > 轻客6米纯电公交 > BMS 电池管理系统 | 部件: BMS 电池管理系统";

BO_ 2550914051 ZT_BMS_180BDC03: 8 Vector__XXX
 SG_ B0 : 0|8@1+ (1,0) [0|255] "" Vector__XXX
 SG_ B1 : 8|8@1+ (1,0) [0|255] "" Vector__XXX
 SG_ B2 : 16|8@1+ (1,0) [0|255] "" Vector__XXX
 SG_ B3 : 24|8@1+ (1,0) [0|255] "" Vector__XXX
 SG_ B4 : 32|8@1+ (1,0) [0|255] "" Vector__XXX
 SG_ B5 : 40|8@1+ (1,0) [0|255] "" Vector__XXX
 SG_ B6 : 48|8@1+ (1,0) [0|255] "" Vector__XXX
 SG_ B7 : 56|8@1+ (1,0) [0|255] "" Vector__XXX

BA_ "VFrameFormat" BO_ 2550914051 1;
CM_ BO_ 2550914051 "0xB3000057 中通新能源 > 纯电动客车 > 轻客6米纯电公交 > BMS 电池管理系统 | 部件: BMS 电池管理系统";

BO_ 2550979587 ZT_BMS_180CDC03: 8 Vector__XXX
 SG_ B0 : 0|8@1+ (1,0) [0|255] "" Vector__XXX
 SG_ B1 : 8|8@1+ (1,0) [0|255] "" Vector__XXX
 SG_ B2 : 16|8@1+ (1,0) [0|255] "" Vector__XXX
 SG_ B3 : 24|8@1+ (1,0) [0|255] "" Vector__XXX
 SG_ B4 : 32|8@1+ (1,0) [0|255] "" Vector__XXX
 SG_ B5 : 40|8@1+ (1,0) [0|255] "" Vector__XXX
 SG_ B6 : 48|8@1+ (1,0) [0|255] "" Vector__XXX
 SG_ B7 : 56|8@1+ (1,0) [0|255] "" Vector__XXX

BA_ "VFrameFormat" BO_ 2550979587 1;
CM_ BO_ 2550979587 "0xB3000057 中通新能源 > 纯电动客车 > 轻客6米纯电公交 > BMS 电池管理系统 | 部件: BMS 电池管理系统";

BO_ 2551045123 ZT_BMS_180DDC03: 8 Vector__XXX
 SG_ B0 : 0|8@1+ (1,0) [0|255] "" Vector__XXX
 SG_ B1 : 8|8@1+ (1,0) [0|255] "" Vector__XXX
 SG_ B2 : 16|8@1+ (1,0) [0|255] "" Vector__XXX
 SG_ B3 : 24|8@1+ (1,0) [0|255] "" Vector__XXX
 SG_ B4 : 32|8@1+ (1,0) [0|255] "" Vector__XXX
 SG_ B5 : 40|8@1+ (1,0) [0|255] "" Vector__XXX
 SG_ B6 : 48|8@1+ (1,0) [0|255] "" Vector__XXX
 SG_ B7 : 56|8@1+ (1,0) [0|255] "" Vector__XXX

BA_ "VFrameFormat" BO_ 2551045123 1;
CM_ BO_ 2551045123 "0xB3000057 中通新能源 > 纯电动客车 > 轻客6米纯电公交 > BMS 电池管理系统 | 部件: BMS 电池管理系统";

BO_ 2551110659 ZT_BMS_180EDC03: 8 Vector__XXX
 SG_ B0 : 0|8@1+ (1,0) [0|255] "" Vector__XXX
 SG_ B1 : 8|8@1+ (1,0) [0|255] "" Vector__XXX
 SG_ B2 : 16|8@1+ (1,0) [0|255] "" Vector__XXX
 SG_ B3 : 24|8@1+ (1,0) [0|255] "" Vector__XXX
 SG_ B4 : 32|8@1+ (1,0) [0|255] "" Vector__XXX
 SG_ B5 : 40|8@1+ (1,0) [0|255] "" Vector__XXX
 SG_ B6 : 48|8@1+ (1,0) [0|255] "" Vector__XXX
 SG_ B7 : 56|8@1+ (1,0) [0|255] "" Vector__XXX

BA_ "VFrameFormat" BO_ 2551110659 1;
CM_ BO_ 2551110659 "0xB3000057 中通新能源 > 纯电动客车 > 轻客6米纯电公交 > BMS 电池管理系统 | 部件: BMS 电池管理系统";

BO_ 2551176195 ZT_BMS_180FDC03: 8 Vector__XXX
 SG_ B0 : 0|8@1+ (1,0) [0|255] "" Vector__XXX
 SG_ B1 : 8|8@1+ (1,0) [0|255] "" Vector__XXX
 SG_ B2 : 16|8@1+ (1,0) [0|255] "" Vector__XXX
 SG_ B3 : 24|8@1+ (1,0) [0|255] "" Vector__XXX
 SG_ B4 : 32|8@1+ (1,0) [0|255] "" Vector__XXX
 SG_ B5 : 40|8@1+ (1,0) [0|255] "" Vector__XXX
 SG_ B6 : 48|8@1+ (1,0) [0|255] "" Vector__XXX
 SG_ B7 : 56|8@1+ (1,0) [0|255] "" Vector__XXX

BA_ "VFrameFormat" BO_ 2551176195 1;
CM_ BO_ 2551176195 "0xB3000057 中通新能源 > 纯电动客车 > 轻客6米纯电公交 > BMS 电池管理系统 | 部件: BMS 电池管理系统";

BO_ 2551241731 ZT_BMS_1810DC03: 8 Vector__XXX
 SG_ B0 : 0|8@1+ (1,0) [0|255] "" Vector__XXX
 SG_ B1 : 8|8@1+ (1,0) [0|255] "" Vector__XXX
 SG_ B2 : 16|8@1+ (1,0) [0|255] "" Vector__XXX
 SG_ B3 : 24|8@1+ (1,0) [0|255] "" Vector__XXX
 SG_ B4 : 32|8@1+ (1,0) [0|255] "" Vector__XXX
 SG_ B5 : 40|8@1+ (1,0) [0|255] "" Vector__XXX
 SG_ B6 : 48|8@1+ (1,0) [0|255] "" Vector__XXX
 SG_ B7 : 56|8@1+ (1,0) [0|255] "" Vector__XXX

BA_ "VFrameFormat" BO_ 2551241731 1;
CM_ BO_ 2551241731 "0xB3000057 中通新能源 > 纯电动客车 > 轻客6米纯电公交 > BMS 电池管理系统 | 部件: BMS 电池管理系统";

BO_ 2551307267 ZT_BMS_1811DC03: 8 Vector__XXX
 SG_ B0 : 0|8@1+ (1,0) [0|255] "" Vector__XXX
 SG_ B1 : 8|8@1+ (1,0) [0|255] "" Vector__XXX
 SG_ B2 : 16|8@1+ (1,0) [0|255] "" Vector__XXX
 SG_ B3 : 24|8@1+ (1,0) [0|255] "" Vector__XXX
 SG_ B4 : 32|8@1+ (1,0) [0|255] "" Vector__XXX
 SG_ B5 : 40|8@1+ (1,0) [0|255] "" Vector__XXX
 SG_ B6 : 48|8@1+ (1,0) [0|255] "" Vector__XXX
 SG_ B7 : 56|8@1+ (1,0) [0|255] "" Vector__XXX

BA_ "VFrameFormat" BO_ 2551307267 1;
CM_ BO_ 2551307267 "0xB3000057 中通新能源 > 纯电动客车 > 轻客6米纯电公交 > BMS 电池管理系统 | 部件: BMS 电池管理系统";

BO_ 2551372803 ZT_BMS_1812DC03: 8 Vector__XXX
 SG_ B0 : 0|8@1+ (1,0) [0|255] "" Vector__XXX
 SG_ B1 : 8|8@1+ (1,0) [0|255] "" Vector__XXX
 SG_ B2 : 16|8@1+ (1,0) [0|255] "" Vector__XXX
 SG_ B3 : 24|8@1+ (1,0) [0|255] "" Vector__XXX
 SG_ B4 : 32|8@1+ (1,0) [0|255] "" Vector__XXX
 SG_ B5 : 40|8@1+ (1,0) [0|255] "" Vector__XXX
 SG_ B6 : 48|8@1+ (1,0) [0|255] "" Vector__XXX
 SG_ B7 : 56|8@1+ (1,0) [0|255] "" Vector__XXX

BA_ "VFrameFormat" BO_ 2551372803 1;
CM_ BO_ 2551372803 "0xB3000057 中通新能源 > 纯电动客车 > 轻客6米纯电公交 > BMS 电池管理系统 | 部件: BMS 电池管理系统";

BO_ 2551438339 ZT_BMS_1813DC03: 8 Vector__XXX
 SG_ B0 : 0|8@1+ (1,0) [0|255] "" Vector__XXX
 SG_ B1 : 8|8@1+ (1,0) [0|255] "" Vector__XXX
 SG_ B2 : 16|8@1+ (1,0) [0|255] "" Vector__XXX
 SG_ B3 : 24|8@1+ (1,0) [0|255] "" Vector__XXX
 SG_ B4 : 32|8@1+ (1,0) [0|255] "" Vector__XXX
 SG_ B5 : 40|8@1+ (1,0) [0|255] "" Vector__XXX
 SG_ B6 : 48|8@1+ (1,0) [0|255] "" Vector__XXX
 SG_ B7 : 56|8@1+ (1,0) [0|255] "" Vector__XXX

BA_ "VFrameFormat" BO_ 2551438339 1;
CM_ BO_ 2551438339 "0xB3000057 中通新能源 > 纯电动客车 > 轻客6米纯电公交 > BMS 电池管理系统 | 部件: BMS 电池管理系统";

BO_ 2551503875 ZT_BMS_1814DC03: 8 Vector__XXX
 SG_ B0 : 0|8@1+ (1,0) [0|255] "" Vector__XXX
 SG_ B1 : 8|8@1+ (1,0) [0|255] "" Vector__XXX
 SG_ B2 : 16|8@1+ (1,0) [0|255] "" Vector__XXX
 SG_ B3 : 24|8@1+ (1,0) [0|255] "" Vector__XXX
 SG_ B4 : 32|8@1+ (1,0) [0|255] "" Vector__XXX
 SG_ B5 : 40|8@1+ (1,0) [0|255] "" Vector__XXX
 SG_ B6 : 48|8@1+ (1,0) [0|255] "" Vector__XXX
 SG_ B7 : 56|8@1+ (1,0) [0|255] "" Vector__XXX

BA_ "VFrameFormat" BO_ 2551503875 1;
CM_ BO_ 2551503875 "0xB3000057 中通新能源 > 纯电动客车 > 轻客6米纯电公交 > BMS 电池管理系统 | 部件: BMS 电池管理系统";

BO_ 2566838787 ZT_BMS_18FEDA03: 8 Vector__XXX
 SG_ B0 : 0|8@1+ (1,0) [0|255] "" Vector__XXX
 SG_ B1 : 8|8@1+ (1,0) [0|255] "" Vector__XXX
 SG_ B2 : 16|8@1+ (1,0) [0|255] "" Vector__XXX
 SG_ B3 : 24|8@1+ (1,0) [0|255] "" Vector__XXX
 SG_ B4 : 32|8@1+ (1,0) [0|255] "" Vector__XXX
 SG_ B5 : 40|8@1+ (1,0) [0|255] "" Vector__XXX
 SG_ B6 : 48|8@1+ (1,0) [0|255] "" Vector__XXX
 SG_ B7 : 56|8@1+ (1,0) [0|255] "" Vector__XXX

BA_ "VFrameFormat" BO_ 2566838787 1;
CM_ BO_ 2566838787 "0xB3000057 中通新能源 > 纯电动客车 > 轻客6米纯电公交 > BMS 电池管理系统 | 部件: BMS 电池管理系统";

BO_ 2566881027 ZT_BMS_18FF7F03: 8 Vector__XXX
 SG_ B0 : 0|8@1+ (1,0) [0|255] "" Vector__XXX
 SG_ B1 : 8|8@1+ (1,0) [0|255] "" Vector__XXX
 SG_ B2 : 16|8@1+ (1,0) [0|255] "" Vector__XXX
 SG_ B3 : 24|8@1+ (1,0) [0|255] "" Vector__XXX
 SG_ B4 : 32|8@1+ (1,0) [0|255] "" Vector__XXX
 SG_ B5 : 40|8@1+ (1,0) [0|255] "" Vector__XXX
 SG_ B6 : 48|8@1+ (1,0) [0|255] "" Vector__XXX
 SG_ B7 : 56|8@1+ (1,0) [0|255] "" Vector__XXX

BA_ "VFrameFormat" BO_ 2566881027 1;
CM_ BO_ 2566881027 "0xB3000057 中通新能源 > 纯电动客车 > 轻客6米纯电公交 > BMS 电池管理系统 | 部件: BMS 电池管理系统";

BO_ 2566882051 ZT_BMS_18FF8303: 8 Vector__XXX
 SG_ B0 : 0|8@1+ (1,0) [0|255] "" Vector__XXX
 SG_ B1 : 8|8@1+ (1,0) [0|255] "" Vector__XXX
 SG_ B2 : 16|8@1+ (1,0) [0|255] "" Vector__XXX
 SG_ B3 : 24|8@1+ (1,0) [0|255] "" Vector__XXX
 SG_ B4 : 32|8@1+ (1,0) [0|255] "" Vector__XXX
 SG_ B5 : 40|8@1+ (1,0) [0|255] "" Vector__XXX
 SG_ B6 : 48|8@1+ (1,0) [0|255] "" Vector__XXX
 SG_ B7 : 56|8@1+ (1,0) [0|255] "" Vector__XXX

BA_ "VFrameFormat" BO_ 2566882051 1;
CM_ BO_ 2566882051 "0xB3000057 中通新能源 > 纯电动客车 > 轻客6米纯电公交 > BMS 电池管理系统 | 部件: BMS 电池管理系统";

BO_ 2352780956 ZT_VCU_0C3C969C: 8 Vector__XXX
 SG_ B0 : 0|8@1+ (1,0) [0|255] "" Vector__XXX
 SG_ B1 : 8|8@1+ (1,0) [0|255] "" Vector__XXX
 SG_ B2 : 16|8@1+ (1,0) [0|255] "" Vector__XXX
 SG_ B3 : 24|8@1+ (1,0) [0|255] "" Vector__XXX
 SG_ B4 : 32|8@1+ (1,0) [0|255] "" Vector__XXX
 SG_ B5 : 40|8@1+ (1,0) [0|255] "" Vector__XXX
 SG_ B6 : 48|8@1+ (1,0) [0|255] "" Vector__XXX
 SG_ B7 : 56|8@1+ (1,0) [0|255] "" Vector__XXX

BA_ "VFrameFormat" BO_ 2352780956 1;
CM_ BO_ 2352780956 "0xB3000058 中通新能源 > 纯电动客车 > 轻客6米纯电公交 > VCU 整车控制器 | 部件: VCU 整车控制器";

BO_ 2352846492 ZT_VCU_0C3D969C: 8 Vector__XXX
 SG_ B0 : 0|8@1+ (1,0) [0|255] "" Vector__XXX
 SG_ B1 : 8|8@1+ (1,0) [0|255] "" Vector__XXX
 SG_ B2 : 16|8@1+ (1,0) [0|255] "" Vector__XXX
 SG_ B3 : 24|8@1+ (1,0) [0|255] "" Vector__XXX
 SG_ B4 : 32|8@1+ (1,0) [0|255] "" Vector__XXX
 SG_ B5 : 40|8@1+ (1,0) [0|255] "" Vector__XXX
 SG_ B6 : 48|8@1+ (1,0) [0|255] "" Vector__XXX
 SG_ B7 : 56|8@1+ (1,0) [0|255] "" Vector__XXX

BA_ "VFrameFormat" BO_ 2352846492 1;
CM_ BO_ 2352846492 "0xB3000058 中通新能源 > 纯电动客车 > 轻客6米纯电公交 > VCU 整车控制器 | 部件: VCU 整车控制器";

BO_ 2352912028 ZT_VCU_0C3E969C: 8 Vector__XXX
 SG_ B0 : 0|8@1+ (1,0) [0|255] "" Vector__XXX
 SG_ B1 : 8|8@1+ (1,0) [0|255] "" Vector__XXX
 SG_ B2 : 16|8@1+ (1,0) [0|255] "" Vector__XXX
 SG_ B3 : 24|8@1+ (1,0) [0|255] "" Vector__XXX
 SG_ B4 : 32|8@1+ (1,0) [0|255] "" Vector__XXX
 SG_ B5 : 40|8@1+ (1,0) [0|255] "" Vector__XXX
 SG_ B6 : 48|8@1+ (1,0) [0|255] "" Vector__XXX
 SG_ B7 : 56|8@1+ (1,0) [0|255] "" Vector__XXX

BA_ "VFrameFormat" BO_ 2352912028 1;
CM_ BO_ 2352912028 "0xB3000058 中通新能源 > 纯电动客车 > 轻客6米纯电公交 > VCU 整车控制器 | 部件: VCU 整车控制器";

BO_ 2352977564 ZT_VCU_0C3F969C: 8 Vector__XXX
 SG_ B0 : 0|8@1+ (1,0) [0|255] "" Vector__XXX
 SG_ B1 : 8|8@1+ (1,0) [0|255] "" Vector__XXX
 SG_ B2 : 16|8@1+ (1,0) [0|255] "" Vector__XXX
 SG_ B3 : 24|8@1+ (1,0) [0|255] "" Vector__XXX
 SG_ B4 : 32|8@1+ (1,0) [0|255] "" Vector__XXX
 SG_ B5 : 40|8@1+ (1,0) [0|255] "" Vector__XXX
 SG_ B6 : 48|8@1+ (1,0) [0|255] "" Vector__XXX
 SG_ B7 : 56|8@1+ (1,0) [0|255] "" Vector__XXX

BA_ "VFrameFormat" BO_ 2352977564 1;
CM_ BO_ 2352977564 "0xB3000058 中通新能源 > 纯电动客车 > 轻客6米纯电公交 > VCU 整车控制器 | 部件: VCU 整车控制器";

BO_ 2353043100 ZT_VCU_0C40969C: 8 Vector__XXX
 SG_ B0 : 0|8@1+ (1,0) [0|255] "" Vector__XXX
 SG_ B1 : 8|8@1+ (1,0) [0|255] "" Vector__XXX
 SG_ B2 : 16|8@1+ (1,0) [0|255] "" Vector__XXX
 SG_ B3 : 24|8@1+ (1,0) [0|255] "" Vector__XXX
 SG_ B4 : 32|8@1+ (1,0) [0|255] "" Vector__XXX
 SG_ B5 : 40|8@1+ (1,0) [0|255] "" Vector__XXX
 SG_ B6 : 48|8@1+ (1,0) [0|255] "" Vector__XXX
 SG_ B7 : 56|8@1+ (1,0) [0|255] "" Vector__XXX

BA_ "VFrameFormat" BO_ 2353043100 1;
CM_ BO_ 2353043100 "0xB3000058 中通新能源 > 纯电动客车 > 轻客6米纯电公交 > VCU 整车控制器 | 部件: VCU 整车控制器";

BO_ 2353174172 ZT_VCU_0C42969C: 8 Vector__XXX
 SG_ B0 : 0|8@1+ (1,0) [0|255] "" Vector__XXX
 SG_ B1 : 8|8@1+ (1,0) [0|255] "" Vector__XXX
 SG_ B2 : 16|8@1+ (1,0) [0|255] "" Vector__XXX
 SG_ B3 : 24|8@1+ (1,0) [0|255] "" Vector__XXX
 SG_ B4 : 32|8@1+ (1,0) [0|255] "" Vector__XXX
 SG_ B5 : 40|8@1+ (1,0) [0|255] "" Vector__XXX
 SG_ B6 : 48|8@1+ (1,0) [0|255] "" Vector__XXX
 SG_ B7 : 56|8@1+ (1,0) [0|255] "" Vector__XXX

BA_ "VFrameFormat" BO_ 2353174172 1;
CM_ BO_ 2353174172 "0xB3000058 中通新能源 > 纯电动客车 > 轻客6米纯电公交 > VCU 整车控制器 | 部件: VCU 整车控制器";

BO_ 2365527297 ZT_VCU_0CFF1501: 8 Vector__XXX
 SG_ B0 : 0|8@1+ (1,0) [0|255] "" Vector__XXX
 SG_ B1 : 8|8@1+ (1,0) [0|255] "" Vector__XXX
 SG_ B2 : 16|8@1+ (1,0) [0|255] "" Vector__XXX
 SG_ B3 : 24|8@1+ (1,0) [0|255] "" Vector__XXX
 SG_ B4 : 32|8@1+ (1,0) [0|255] "" Vector__XXX
 SG_ B5 : 40|8@1+ (1,0) [0|255] "" Vector__XXX
 SG_ B6 : 48|8@1+ (1,0) [0|255] "" Vector__XXX
 SG_ B7 : 56|8@1+ (1,0) [0|255] "" Vector__XXX

BA_ "VFrameFormat" BO_ 2365527297 1;
CM_ BO_ 2365527297 "0xB3000058 中通新能源 > 纯电动客车 > 轻客6米纯电公交 > VCU 整车控制器 | 部件: VCU 整车控制器";

BO_ 2566838940 ZT_VCU_18FEDA9C: 8 Vector__XXX
 SG_ B0 : 0|8@1+ (1,0) [0|255] "" Vector__XXX
 SG_ B1 : 8|8@1+ (1,0) [0|255] "" Vector__XXX
 SG_ B2 : 16|8@1+ (1,0) [0|255] "" Vector__XXX
 SG_ B3 : 24|8@1+ (1,0) [0|255] "" Vector__XXX
 SG_ B4 : 32|8@1+ (1,0) [0|255] "" Vector__XXX
 SG_ B5 : 40|8@1+ (1,0) [0|255] "" Vector__XXX
 SG_ B6 : 48|8@1+ (1,0) [0|255] "" Vector__XXX
 SG_ B7 : 56|8@1+ (1,0) [0|255] "" Vector__XXX

BA_ "VFrameFormat" BO_ 2566838940 1;
CM_ BO_ 2566838940 "0xB3000058 中通新能源 > 纯电动客车 > 轻客6米纯电公交 > VCU 整车控制器 | 部件: VCU 整车控制器";

BO_ 2566848495 ZT_VCU_18FEFFEF: 8 Vector__XXX
 SG_ B0 : 0|8@1+ (1,0) [0|255] "" Vector__XXX
 SG_ B1 : 8|8@1+ (1,0) [0|255] "" Vector__XXX
 SG_ B2 : 16|8@1+ (1,0) [0|255] "" Vector__XXX
 SG_ B3 : 24|8@1+ (1,0) [0|255] "" Vector__XXX
 SG_ B4 : 32|8@1+ (1,0) [0|255] "" Vector__XXX
 SG_ B5 : 40|8@1+ (1,0) [0|255] "" Vector__XXX
 SG_ B6 : 48|8@1+ (1,0) [0|255] "" Vector__XXX
 SG_ B7 : 56|8@1+ (1,0) [0|255] "" Vector__XXX

BA_ "VFrameFormat" BO_ 2566848495 1;
CM_ BO_ 2566848495 "0xB3000058 中通新能源 > 纯电动客车 > 轻客6米纯电公交 > VCU 整车控制器 | 部件: VCU 整车控制器";

BO_ 2566881025 ZT_VCU_18FF7F01: 8 Vector__XXX
 SG_ B0 : 0|8@1+ (1,0) [0|255] "" Vector__XXX
 SG_ B1 : 8|8@1+ (1,0) [0|255] "" Vector__XXX
 SG_ B2 : 16|8@1+ (1,0) [0|255] "" Vector__XXX
 SG_ B3 : 24|8@1+ (1,0) [0|255] "" Vector__XXX
 SG_ B4 : 32|8@1+ (1,0) [0|255] "" Vector__XXX
 SG_ B5 : 40|8@1+ (1,0) [0|255] "" Vector__XXX
 SG_ B6 : 48|8@1+ (1,0) [0|255] "" Vector__XXX
 SG_ B7 : 56|8@1+ (1,0) [0|255] "" Vector__XXX

BA_ "VFrameFormat" BO_ 2566881025 1;
CM_ BO_ 2566881025 "0xB3000058 中通新能源 > 纯电动客车 > 轻客6米纯电公交 > VCU 整车控制器 | 部件: VCU 整车控制器";

BO_ 2352782486 ZT_ICM_0C3C9C96: 8 Vector__XXX
 SG_ B0 : 0|8@1+ (1,0) [0|255] "" Vector__XXX
 SG_ B1 : 8|8@1+ (1,0) [0|255] "" Vector__XXX
 SG_ B2 : 16|8@1+ (1,0) [0|255] "" Vector__XXX
 SG_ B3 : 24|8@1+ (1,0) [0|255] "" Vector__XXX
 SG_ B4 : 32|8@1+ (1,0) [0|255] "" Vector__XXX
 SG_ B5 : 40|8@1+ (1,0) [0|255] "" Vector__XXX
 SG_ B6 : 48|8@1+ (1,0) [0|255] "" Vector__XXX
 SG_ B7 : 56|8@1+ (1,0) [0|255] "" Vector__XXX

BA_ "VFrameFormat" BO_ 2352782486 1;
CM_ BO_ 2352782486 "0xB3000059 中通新能源 > 纯电动客车 > 轻客6米纯电公交 > IC 组合仪表 | 部件: IC 组合仪表";

BO_ 2352848022 ZT_ICM_0C3D9C96: 8 Vector__XXX
 SG_ B0 : 0|8@1+ (1,0) [0|255] "" Vector__XXX
 SG_ B1 : 8|8@1+ (1,0) [0|255] "" Vector__XXX
 SG_ B2 : 16|8@1+ (1,0) [0|255] "" Vector__XXX
 SG_ B3 : 24|8@1+ (1,0) [0|255] "" Vector__XXX
 SG_ B4 : 32|8@1+ (1,0) [0|255] "" Vector__XXX
 SG_ B5 : 40|8@1+ (1,0) [0|255] "" Vector__XXX
 SG_ B6 : 48|8@1+ (1,0) [0|255] "" Vector__XXX
 SG_ B7 : 56|8@1+ (1,0) [0|255] "" Vector__XXX

BA_ "VFrameFormat" BO_ 2352848022 1;
CM_ BO_ 2352848022 "0xB3000059 中通新能源 > 纯电动客车 > 轻客6米纯电公交 > IC 组合仪表 | 部件: IC 组合仪表";

BO_ 2353110166 ZT_ICM_0C419C96: 8 Vector__XXX
 SG_ B0 : 0|8@1+ (1,0) [0|255] "" Vector__XXX
 SG_ B1 : 8|8@1+ (1,0) [0|255] "" Vector__XXX
 SG_ B2 : 16|8@1+ (1,0) [0|255] "" Vector__XXX
 SG_ B3 : 24|8@1+ (1,0) [0|255] "" Vector__XXX
 SG_ B4 : 32|8@1+ (1,0) [0|255] "" Vector__XXX
 SG_ B5 : 40|8@1+ (1,0) [0|255] "" Vector__XXX
 SG_ B6 : 48|8@1+ (1,0) [0|255] "" Vector__XXX
 SG_ B7 : 56|8@1+ (1,0) [0|255] "" Vector__XXX

BA_ "VFrameFormat" BO_ 2353110166 1;
CM_ BO_ 2353110166 "0xB3000059 中通新能源 > 纯电动客车 > 轻客6米纯电公交 > IC 组合仪表 | 部件: IC 组合仪表";

BO_ 2566838934 ZT_ICM_18FEDA96: 8 Vector__XXX
 SG_ B0 : 0|8@1+ (1,0) [0|255] "" Vector__XXX
 SG_ B1 : 8|8@1+ (1,0) [0|255] "" Vector__XXX
 SG_ B2 : 16|8@1+ (1,0) [0|255] "" Vector__XXX
 SG_ B3 : 24|8@1+ (1,0) [0|255] "" Vector__XXX
 SG_ B4 : 32|8@1+ (1,0) [0|255] "" Vector__XXX
 SG_ B5 : 40|8@1+ (1,0) [0|255] "" Vector__XXX
 SG_ B6 : 48|8@1+ (1,0) [0|255] "" Vector__XXX
 SG_ B7 : 56|8@1+ (1,0) [0|255] "" Vector__XXX

BA_ "VFrameFormat" BO_ 2566838934 1;
CM_ BO_ 2566838934 "0xB3000059 中通新能源 > 纯电动客车 > 轻客6米纯电公交 > IC 组合仪表 | 部件: IC 组合仪表";

BO_ 2565939184 ZT_MCU_18F11FF0: 8 Vector__XXX
 SG_ B0 : 0|8@1+ (1,0) [0|255] "" Vector__XXX
 SG_ B1 : 8|8@1+ (1,0) [0|255] "" Vector__XXX
 SG_ B2 : 16|8@1+ (1,0) [0|255] "" Vector__XXX
 SG_ B3 : 24|8@1+ (1,0) [0|255] "" Vector__XXX
 SG_ B4 : 32|8@1+ (1,0) [0|255] "" Vector__XXX
 SG_ B5 : 40|8@1+ (1,0) [0|255] "" Vector__XXX
 SG_ B6 : 48|8@1+ (1,0) [0|255] "" Vector__XXX
 SG_ B7 : 56|8@1+ (1,0) [0|255] "" Vector__XXX

BA_ "VFrameFormat" BO_ 2565939184 1;
CM_ BO_ 2565939184 "0xB300005A 中通新能源 > 纯电动客车 > 轻客6米纯电公交 > 电机控制器 | 部件: 电机控制器";

BO_ 2565939440 ZT_MCU_18F120F0: 8 Vector__XXX
 SG_ B0 : 0|8@1+ (1,0) [0|255] "" Vector__XXX
 SG_ B1 : 8|8@1+ (1,0) [0|255] "" Vector__XXX
 SG_ B2 : 16|8@1+ (1,0) [0|255] "" Vector__XXX
 SG_ B3 : 24|8@1+ (1,0) [0|255] "" Vector__XXX
 SG_ B4 : 32|8@1+ (1,0) [0|255] "" Vector__XXX
 SG_ B5 : 40|8@1+ (1,0) [0|255] "" Vector__XXX
 SG_ B6 : 48|8@1+ (1,0) [0|255] "" Vector__XXX
 SG_ B7 : 56|8@1+ (1,0) [0|255] "" Vector__XXX

BA_ "VFrameFormat" BO_ 2565939440 1;
CM_ BO_ 2565939440 "0xB300005A 中通新能源 > 纯电动客车 > 轻客6米纯电公交 > 电机控制器 | 部件: 电机控制器";

BO_ 2565939696 ZT_MCU_18F121F0: 8 Vector__XXX
 SG_ B0 : 0|8@1+ (1,0) [0|255] "" Vector__XXX
 SG_ B1 : 8|8@1+ (1,0) [0|255] "" Vector__XXX
 SG_ B2 : 16|8@1+ (1,0) [0|255] "" Vector__XXX
 SG_ B3 : 24|8@1+ (1,0) [0|255] "" Vector__XXX
 SG_ B4 : 32|8@1+ (1,0) [0|255] "" Vector__XXX
 SG_ B5 : 40|8@1+ (1,0) [0|255] "" Vector__XXX
 SG_ B6 : 48|8@1+ (1,0) [0|255] "" Vector__XXX
 SG_ B7 : 56|8@1+ (1,0) [0|255] "" Vector__XXX

BA_ "VFrameFormat" BO_ 2565939696 1;
CM_ BO_ 2565939696 "0xB300005A 中通新能源 > 纯电动客车 > 轻客6米纯电公交 > 电机控制器 | 部件: 电机控制器";

BO_ 2565939952 ZT_MCU_18F122F0: 8 Vector__XXX
 SG_ B0 : 0|8@1+ (1,0) [0|255] "" Vector__XXX
 SG_ B1 : 8|8@1+ (1,0) [0|255] "" Vector__XXX
 SG_ B2 : 16|8@1+ (1,0) [0|255] "" Vector__XXX
 SG_ B3 : 24|8@1+ (1,0) [0|255] "" Vector__XXX
 SG_ B4 : 32|8@1+ (1,0) [0|255] "" Vector__XXX
 SG_ B5 : 40|8@1+ (1,0) [0|255] "" Vector__XXX
 SG_ B6 : 48|8@1+ (1,0) [0|255] "" Vector__XXX
 SG_ B7 : 56|8@1+ (1,0) [0|255] "" Vector__XXX

BA_ "VFrameFormat" BO_ 2565939952 1;
CM_ BO_ 2565939952 "0xB300005A 中通新能源 > 纯电动客车 > 轻客6米纯电公交 > 电机控制器 | 部件: 电机控制器";

BO_ 2566839024 ZT_MCU_18FEDAF0: 8 Vector__XXX
 SG_ B0 : 0|8@1+ (1,0) [0|255] "" Vector__XXX
 SG_ B1 : 8|8@1+ (1,0) [0|255] "" Vector__XXX
 SG_ B2 : 16|8@1+ (1,0) [0|255] "" Vector__XXX
 SG_ B3 : 24|8@1+ (1,0) [0|255] "" Vector__XXX
 SG_ B4 : 32|8@1+ (1,0) [0|255] "" Vector__XXX
 SG_ B5 : 40|8@1+ (1,0) [0|255] "" Vector__XXX
 SG_ B6 : 48|8@1+ (1,0) [0|255] "" Vector__XXX
 SG_ B7 : 56|8@1+ (1,0) [0|255] "" Vector__XXX

BA_ "VFrameFormat" BO_ 2566839024 1;
CM_ BO_ 2566839024 "0xB300005A 中通新能源 > 纯电动客车 > 轻客6米纯电公交 > 电机控制器 | 部件: 电机控制器";

BO_ 2364605095 ZT_DCDC_0CF102A7: 8 Vector__XXX
 SG_ B0 : 0|8@1+ (1,0) [0|255] "" Vector__XXX
 SG_ B1 : 8|8@1+ (1,0) [0|255] "" Vector__XXX
 SG_ B2 : 16|8@1+ (1,0) [0|255] "" Vector__XXX
 SG_ B3 : 24|8@1+ (1,0) [0|255] "" Vector__XXX
 SG_ B4 : 32|8@1+ (1,0) [0|255] "" Vector__XXX
 SG_ B5 : 40|8@1+ (1,0) [0|255] "" Vector__XXX
 SG_ B6 : 48|8@1+ (1,0) [0|255] "" Vector__XXX
 SG_ B7 : 56|8@1+ (1,0) [0|255] "" Vector__XXX

BA_ "VFrameFormat" BO_ 2364605095 1;
CM_ BO_ 2364605095 "0xB300005B 中通新能源 > 纯电动客车 > 轻客6米纯电公交 > DCDC | 部件: DCDC";

BO_ 2558303399 ZT_DCDC_187C9CA7: 8 Vector__XXX
 SG_ B0 : 0|8@1+ (1,0) [0|255] "" Vector__XXX
 SG_ B1 : 8|8@1+ (1,0) [0|255] "" Vector__XXX
 SG_ B2 : 16|8@1+ (1,0) [0|255] "" Vector__XXX
 SG_ B3 : 24|8@1+ (1,0) [0|255] "" Vector__XXX
 SG_ B4 : 32|8@1+ (1,0) [0|255] "" Vector__XXX
 SG_ B5 : 40|8@1+ (1,0) [0|255] "" Vector__XXX
 SG_ B6 : 48|8@1+ (1,0) [0|255] "" Vector__XXX
 SG_ B7 : 56|8@1+ (1,0) [0|255] "" Vector__XXX

BA_ "VFrameFormat" BO_ 2558303399 1;
CM_ BO_ 2558303399 "0xB300005B 中通新能源 > 纯电动客车 > 轻客6米纯电公交 > DCDC | 部件: DCDC";

BO_ 2556206245 ZT_OilPumpInv_185C9CA5: 8 Vector__XXX
 SG_ B0 : 0|8@1+ (1,0) [0|255] "" Vector__XXX
 SG_ B1 : 8|8@1+ (1,0) [0|255] "" Vector__XXX
 SG_ B2 : 16|8@1+ (1,0) [0|255] "" Vector__XXX
 SG_ B3 : 24|8@1+ (1,0) [0|255] "" Vector__XXX
 SG_ B4 : 32|8@1+ (1,0) [0|255] "" Vector__XXX
 SG_ B5 : 40|8@1+ (1,0) [0|255] "" Vector__XXX
 SG_ B6 : 48|8@1+ (1,0) [0|255] "" Vector__XXX
 SG_ B7 : 56|8@1+ (1,0) [0|255] "" Vector__XXX

BA_ "VFrameFormat" BO_ 2556206245 1;
CM_ BO_ 2556206245 "0xB300005C 中通新能源 > 纯电动客车 > 轻客6米纯电公交 > 油泵DCAC | 部件: 油泵DCAC";

BO_ 2556271781 ZT_OilPumpInv_185D9CA5: 8 Vector__XXX
 SG_ B0 : 0|8@1+ (1,0) [0|255] "" Vector__XXX
 SG_ B1 : 8|8@1+ (1,0) [0|255] "" Vector__XXX
 SG_ B2 : 16|8@1+ (1,0) [0|255] "" Vector__XXX
 SG_ B3 : 24|8@1+ (1,0) [0|255] "" Vector__XXX
 SG_ B4 : 32|8@1+ (1,0) [0|255] "" Vector__XXX
 SG_ B5 : 40|8@1+ (1,0) [0|255] "" Vector__XXX
 SG_ B6 : 48|8@1+ (1,0) [0|255] "" Vector__XXX
 SG_ B7 : 56|8@1+ (1,0) [0|255] "" Vector__XXX

BA_ "VFrameFormat" BO_ 2556271781 1;
CM_ BO_ 2556271781 "0xB300005C 中通新能源 > 纯电动客车 > 轻客6米纯电公交 > 油泵DCAC | 部件: 油泵DCAC";

BO_ 2557254822 ZT_AirPumpInv_186C9CA6: 8 Vector__XXX
 SG_ B0 : 0|8@1+ (1,0) [0|255] "" Vector__XXX
 SG_ B1 : 8|8@1+ (1,0) [0|255] "" Vector__XXX
 SG_ B2 : 16|8@1+ (1,0) [0|255] "" Vector__XXX
 SG_ B3 : 24|8@1+ (1,0) [0|255] "" Vector__XXX
 SG_ B4 : 32|8@1+ (1,0) [0|255] "" Vector__XXX
 SG_ B5 : 40|8@1+ (1,0) [0|255] "" Vector__XXX
 SG_ B6 : 48|8@1+ (1,0) [0|255] "" Vector__XXX
 SG_ B7 : 56|8@1+ (1,0) [0|255] "" Vector__XXX

BA_ "VFrameFormat" BO_ 2557254822 1;
CM_ BO_ 2557254822 "0xB300005D 中通新能源 > 纯电动客车 > 轻客6米纯电公交 > 气泵DCAC | 部件: 气泵DCAC";

BO_ 2557320358 ZT_AirPumpInv_186D9CA6: 8 Vector__XXX
 SG_ B0 : 0|8@1+ (1,0) [0|255] "" Vector__XXX
 SG_ B1 : 8|8@1+ (1,0) [0|255] "" Vector__XXX
 SG_ B2 : 16|8@1+ (1,0) [0|255] "" Vector__XXX
 SG_ B3 : 24|8@1+ (1,0) [0|255] "" Vector__XXX
 SG_ B4 : 32|8@1+ (1,0) [0|255] "" Vector__XXX
 SG_ B5 : 40|8@1+ (1,0) [0|255] "" Vector__XXX
 SG_ B6 : 48|8@1+ (1,0) [0|255] "" Vector__XXX
 SG_ B7 : 56|8@1+ (1,0) [0|255] "" Vector__XXX

BA_ "VFrameFormat" BO_ 2557320358 1;
CM_ BO_ 2557320358 "0xB300005D 中通新能源 > 纯电动客车 > 轻客6米纯电公交 > 气泵DCAC | 部件: 气泵DCAC";

BO_ 2566909951 ZT_RMT_18FFEFFF: 8 Vector__XXX
 SG_ B0 : 0|8@1+ (1,0) [0|255] "" Vector__XXX
 SG_ B1 : 8|8@1+ (1,0) [0|255] "" Vector__XXX
 SG_ B2 : 16|8@1+ (1,0) [0|255] "" Vector__XXX
 SG_ B3 : 24|8@1+ (1,0) [0|255] "" Vector__XXX
 SG_ B4 : 32|8@1+ (1,0) [0|255] "" Vector__XXX
 SG_ B5 : 40|8@1+ (1,0) [0|255] "" Vector__XXX
 SG_ B6 : 48|8@1+ (1,0) [0|255] "" Vector__XXX
 SG_ B7 : 56|8@1+ (1,0) [0|255] "" Vector__XXX

BA_ "VFrameFormat" BO_ 2566909951 1;
CM_ BO_ 2566909951 "0xB300005F 中通新能源 > 纯电动客车 > 轻客6米纯电公交 > 远程监控终端 | 部件: 远程监控终端";

BO_ 2565865739 ZT_Misc_18F0010B: 8 Vector__XXX
 SG_ B0 : 0|8@1+ (1,0) [0|255] "" Vector__XXX
 SG_ B1 : 8|8@1+ (1,0) [0|255] "" Vector__XXX
 SG_ B2 : 16|8@1+ (1,0) [0|255] "" Vector__XXX
 SG_ B3 : 24|8@1+ (1,0) [0|255] "" Vector__XXX
 SG_ B4 : 32|8@1+ (1,0) [0|255] "" Vector__XXX
 SG_ B5 : 40|8@1+ (1,0) [0|255] "" Vector__XXX
 SG_ B6 : 48|8@1+ (1,0) [0|255] "" Vector__XXX
 SG_ B7 : 56|8@1+ (1,0) [0|255] "" Vector__XXX

BA_ "VFrameFormat" BO_ 2565865739 1;
CM_ BO_ 2565865739 "0xB3000060 中通新能源 > 纯电动客车 > 轻客6米纯电公交 > ABS | 部件: ABS";

BO_ 2566852847 ZT_VCU_18FF10EF: 8 Vector__XXX
 SG_ B0 : 0|8@1+ (1,0) [0|255] "" Vector__XXX
 SG_ B1 : 8|8@1+ (1,0) [0|255] "" Vector__XXX
 SG_ B2 : 16|8@1+ (1,0) [0|255] "" Vector__XXX
 SG_ B3 : 24|8@1+ (1,0) [0|255] "" Vector__XXX
 SG_ B4 : 32|8@1+ (1,0) [0|255] "" Vector__XXX
 SG_ B5 : 40|8@1+ (1,0) [0|255] "" Vector__XXX
 SG_ B6 : 48|8@1+ (1,0) [0|255] "" Vector__XXX
 SG_ B7 : 56|8@1+ (1,0) [0|255] "" Vector__XXX

BA_ "VFrameFormat" BO_ 2566852847 1;
CM_ BO_ 2566852847 "0xB3000083 中通新能源 > 燃料电池客车 > VCU 整车控制器 | 0xB30000A6 中通新能源 > 澳巴混合动力 > 7米澳巴混合动力客车 > VCU 整车控制器 | 部件: VCU 整车控制器";

BO_ 2566871791 ZT_VCU_18FF5AEF: 8 Vector__XXX
 SG_ B0 : 0|8@1+ (1,0) [0|255] "" Vector__XXX
 SG_ B1 : 8|8@1+ (1,0) [0|255] "" Vector__XXX
 SG_ B2 : 16|8@1+ (1,0) [0|255] "" Vector__XXX
 SG_ B3 : 24|8@1+ (1,0) [0|255] "" Vector__XXX
 SG_ B4 : 32|8@1+ (1,0) [0|255] "" Vector__XXX
 SG_ B5 : 40|8@1+ (1,0) [0|255] "" Vector__XXX
 SG_ B6 : 48|8@1+ (1,0) [0|255] "" Vector__XXX
 SG_ B7 : 56|8@1+ (1,0) [0|255] "" Vector__XXX

BA_ "VFrameFormat" BO_ 2566871791 1;
CM_ BO_ 2566871791 "0xB3000083 中通新能源 > 燃料电池客车 > VCU 整车控制器 | 部件: VCU 整车控制器";

BO_ 2550245279 ZT_AuxPower_1801A79F: 8 Vector__XXX
 SG_ B0 : 0|8@1+ (1,0) [0|255] "" Vector__XXX
 SG_ B1 : 8|8@1+ (1,0) [0|255] "" Vector__XXX
 SG_ B2 : 16|8@1+ (1,0) [0|255] "" Vector__XXX
 SG_ B3 : 24|8@1+ (1,0) [0|255] "" Vector__XXX
 SG_ B4 : 32|8@1+ (1,0) [0|255] "" Vector__XXX
 SG_ B5 : 40|8@1+ (1,0) [0|255] "" Vector__XXX
 SG_ B6 : 48|8@1+ (1,0) [0|255] "" Vector__XXX
 SG_ B7 : 56|8@1+ (1,0) [0|255] "" Vector__XXX

BA_ "VFrameFormat" BO_ 2550245279 1;
CM_ BO_ 2550245279 "0xB300008B 中通新能源 > 燃料电池客车 > 集成电源辅助 | 0xB30000AC 中通新能源 > 澳巴混合动力 > 7米澳巴混合动力客车 > 集成电源辅助 | 0xB30000CD 中通新能源 > 澳巴混合动力 > 9米11米澳巴混合动力客车 > 集成电源辅助 | 部件: 集成电源辅助";

BO_ 2559351976 ZT_LVOilPumpCtrl_188C9CA8: 8 Vector__XXX
 SG_ B0 : 0|8@1+ (1,0) [0|255] "" Vector__XXX
 SG_ B1 : 8|8@1+ (1,0) [0|255] "" Vector__XXX
 SG_ B2 : 16|8@1+ (1,0) [0|255] "" Vector__XXX
 SG_ B3 : 24|8@1+ (1,0) [0|255] "" Vector__XXX
 SG_ B4 : 32|8@1+ (1,0) [0|255] "" Vector__XXX
 SG_ B5 : 40|8@1+ (1,0) [0|255] "" Vector__XXX
 SG_ B6 : 48|8@1+ (1,0) [0|255] "" Vector__XXX
 SG_ B7 : 56|8@1+ (1,0) [0|255] "" Vector__XXX

BA_ "VFrameFormat" BO_ 2559351976 1;
CM_ BO_ 2559351976 "0xB3000098 中通新能源 > 燃料电池客车 > 低压油泵控制器 | 部件: 低压油泵控制器";

BO_ 2566834932 ZT_ChgCAN_18FECAF4: 8 Vector__XXX
 SG_ B0 : 0|8@1+ (1,0) [0|255] "" Vector__XXX
 SG_ B1 : 8|8@1+ (1,0) [0|255] "" Vector__XXX
 SG_ B2 : 16|8@1+ (1,0) [0|255] "" Vector__XXX
 SG_ B3 : 24|8@1+ (1,0) [0|255] "" Vector__XXX
 SG_ B4 : 32|8@1+ (1,0) [0|255] "" Vector__XXX
 SG_ B5 : 40|8@1+ (1,0) [0|255] "" Vector__XXX
 SG_ B6 : 48|8@1+ (1,0) [0|255] "" Vector__XXX
 SG_ B7 : 56|8@1+ (1,0) [0|255] "" Vector__XXX

BA_ "VFrameFormat" BO_ 2566834932 1;
CM_ BO_ 2566834932 "0xB300009B 中通新能源 > 燃料电池客车 > 充电 CAN 网络 | 部件: 充电 CAN 网络";

BO_ 2566889972 ZT_ChgCAN_18FFA1F4: 8 Vector__XXX
 SG_ B0 : 0|8@1+ (1,0) [0|255] "" Vector__XXX
 SG_ B1 : 8|8@1+ (1,0) [0|255] "" Vector__XXX
 SG_ B2 : 16|8@1+ (1,0) [0|255] "" Vector__XXX
 SG_ B3 : 24|8@1+ (1,0) [0|255] "" Vector__XXX
 SG_ B4 : 32|8@1+ (1,0) [0|255] "" Vector__XXX
 SG_ B5 : 40|8@1+ (1,0) [0|255] "" Vector__XXX
 SG_ B6 : 48|8@1+ (1,0) [0|255] "" Vector__XXX
 SG_ B7 : 56|8@1+ (1,0) [0|255] "" Vector__XXX

BA_ "VFrameFormat" BO_ 2566889972 1;
CM_ BO_ 2566889972 "0xB300009B 中通新能源 > 燃料电池客车 > 充电 CAN 网络 | 部件: 充电 CAN 网络";

BO_ 2566890228 ZT_ChgCAN_18FFA2F4: 8 Vector__XXX
 SG_ B0 : 0|8@1+ (1,0) [0|255] "" Vector__XXX
 SG_ B1 : 8|8@1+ (1,0) [0|255] "" Vector__XXX
 SG_ B2 : 16|8@1+ (1,0) [0|255] "" Vector__XXX
 SG_ B3 : 24|8@1+ (1,0) [0|255] "" Vector__XXX
 SG_ B4 : 32|8@1+ (1,0) [0|255] "" Vector__XXX
 SG_ B5 : 40|8@1+ (1,0) [0|255] "" Vector__XXX
 SG_ B6 : 48|8@1+ (1,0) [0|255] "" Vector__XXX
 SG_ B7 : 56|8@1+ (1,0) [0|255] "" Vector__XXX

BA_ "VFrameFormat" BO_ 2566890228 1;
CM_ BO_ 2566890228 "0xB300009B 中通新能源 > 燃料电池客车 > 充电 CAN 网络 | 部件: 充电 CAN 网络";

BO_ 2566890484 ZT_ChgCAN_18FFA3F4: 8 Vector__XXX
 SG_ B0 : 0|8@1+ (1,0) [0|255] "" Vector__XXX
 SG_ B1 : 8|8@1+ (1,0) [0|255] "" Vector__XXX
 SG_ B2 : 16|8@1+ (1,0) [0|255] "" Vector__XXX
 SG_ B3 : 24|8@1+ (1,0) [0|255] "" Vector__XXX
 SG_ B4 : 32|8@1+ (1,0) [0|255] "" Vector__XXX
 SG_ B5 : 40|8@1+ (1,0) [0|255] "" Vector__XXX
 SG_ B6 : 48|8@1+ (1,0) [0|255] "" Vector__XXX
 SG_ B7 : 56|8@1+ (1,0) [0|255] "" Vector__XXX

BA_ "VFrameFormat" BO_ 2566890484 1;
CM_ BO_ 2566890484 "0xB300009B 中通新能源 > 燃料电池客车 > 充电 CAN 网络 | 部件: 充电 CAN 网络";

BO_ 2566890740 ZT_ChgCAN_18FFA4F4: 8 Vector__XXX
 SG_ B0 : 0|8@1+ (1,0) [0|255] "" Vector__XXX
 SG_ B1 : 8|8@1+ (1,0) [0|255] "" Vector__XXX
 SG_ B2 : 16|8@1+ (1,0) [0|255] "" Vector__XXX
 SG_ B3 : 24|8@1+ (1,0) [0|255] "" Vector__XXX
 SG_ B4 : 32|8@1+ (1,0) [0|255] "" Vector__XXX
 SG_ B5 : 40|8@1+ (1,0) [0|255] "" Vector__XXX
 SG_ B6 : 48|8@1+ (1,0) [0|255] "" Vector__XXX
 SG_ B7 : 56|8@1+ (1,0) [0|255] "" Vector__XXX

BA_ "VFrameFormat" BO_ 2566890740 1;
CM_ BO_ 2566890740 "0xB300009B 中通新能源 > 燃料电池客车 > 充电 CAN 网络 | 部件: 充电 CAN 网络";

BO_ 2566890996 ZT_ChgCAN_18FFA5F4: 8 Vector__XXX
 SG_ B0 : 0|8@1+ (1,0) [0|255] "" Vector__XXX
 SG_ B1 : 8|8@1+ (1,0) [0|255] "" Vector__XXX
 SG_ B2 : 16|8@1+ (1,0) [0|255] "" Vector__XXX
 SG_ B3 : 24|8@1+ (1,0) [0|255] "" Vector__XXX
 SG_ B4 : 32|8@1+ (1,0) [0|255] "" Vector__XXX
 SG_ B5 : 40|8@1+ (1,0) [0|255] "" Vector__XXX
 SG_ B6 : 48|8@1+ (1,0) [0|255] "" Vector__XXX
 SG_ B7 : 56|8@1+ (1,0) [0|255] "" Vector__XXX

BA_ "VFrameFormat" BO_ 2566890996 1;
CM_ BO_ 2566890996 "0xB300009B 中通新能源 > 燃料电池客车 > 充电 CAN 网络 | 部件: 充电 CAN 网络";

BO_ 2566891252 ZT_ChgCAN_18FFA6F4: 8 Vector__XXX
 SG_ B0 : 0|8@1+ (1,0) [0|255] "" Vector__XXX
 SG_ B1 : 8|8@1+ (1,0) [0|255] "" Vector__XXX
 SG_ B2 : 16|8@1+ (1,0) [0|255] "" Vector__XXX
 SG_ B3 : 24|8@1+ (1,0) [0|255] "" Vector__XXX
 SG_ B4 : 32|8@1+ (1,0) [0|255] "" Vector__XXX
 SG_ B5 : 40|8@1+ (1,0) [0|255] "" Vector__XXX
 SG_ B6 : 48|8@1+ (1,0) [0|255] "" Vector__XXX
 SG_ B7 : 56|8@1+ (1,0) [0|255] "" Vector__XXX

BA_ "VFrameFormat" BO_ 2566891252 1;
CM_ BO_ 2566891252 "0xB300009B 中通新能源 > 燃料电池客车 > 充电 CAN 网络 | 部件: 充电 CAN 网络";

BO_ 2566891508 ZT_ChgCAN_18FFA7F4: 8 Vector__XXX
 SG_ B0 : 0|8@1+ (1,0) [0|255] "" Vector__XXX
 SG_ B1 : 8|8@1+ (1,0) [0|255] "" Vector__XXX
 SG_ B2 : 16|8@1+ (1,0) [0|255] "" Vector__XXX
 SG_ B3 : 24|8@1+ (1,0) [0|255] "" Vector__XXX
 SG_ B4 : 32|8@1+ (1,0) [0|255] "" Vector__XXX
 SG_ B5 : 40|8@1+ (1,0) [0|255] "" Vector__XXX
 SG_ B6 : 48|8@1+ (1,0) [0|255] "" Vector__XXX
 SG_ B7 : 56|8@1+ (1,0) [0|255] "" Vector__XXX

BA_ "VFrameFormat" BO_ 2566891508 1;
CM_ BO_ 2566891508 "0xB300009B 中通新能源 > 燃料电池客车 > 充电 CAN 网络 | 部件: 充电 CAN 网络";

BO_ 2566891764 ZT_ChgCAN_18FFA8F4: 8 Vector__XXX
 SG_ B0 : 0|8@1+ (1,0) [0|255] "" Vector__XXX
 SG_ B1 : 8|8@1+ (1,0) [0|255] "" Vector__XXX
 SG_ B2 : 16|8@1+ (1,0) [0|255] "" Vector__XXX
 SG_ B3 : 24|8@1+ (1,0) [0|255] "" Vector__XXX
 SG_ B4 : 32|8@1+ (1,0) [0|255] "" Vector__XXX
 SG_ B5 : 40|8@1+ (1,0) [0|255] "" Vector__XXX
 SG_ B6 : 48|8@1+ (1,0) [0|255] "" Vector__XXX
 SG_ B7 : 56|8@1+ (1,0) [0|255] "" Vector__XXX

BA_ "VFrameFormat" BO_ 2566891764 1;
CM_ BO_ 2566891764 "0xB300009B 中通新能源 > 燃料电池客车 > 充电 CAN 网络 | 部件: 充电 CAN 网络";

BO_ 0 ZT_FCEngine_00000000: 8 Vector__XXX
 SG_ B0 : 0|8@1+ (1,0) [0|255] "" Vector__XXX
 SG_ B1 : 8|8@1+ (1,0) [0|255] "" Vector__XXX
 SG_ B2 : 16|8@1+ (1,0) [0|255] "" Vector__XXX
 SG_ B3 : 24|8@1+ (1,0) [0|255] "" Vector__XXX
 SG_ B4 : 32|8@1+ (1,0) [0|255] "" Vector__XXX
 SG_ B5 : 40|8@1+ (1,0) [0|255] "" Vector__XXX
 SG_ B6 : 48|8@1+ (1,0) [0|255] "" Vector__XXX
 SG_ B7 : 56|8@1+ (1,0) [0|255] "" Vector__XXX

CM_ BO_ 0 "0xB300009D 中通新能源 > 燃料电池客车 > 燃料电池发动机 | 部件: 燃料电池发动机 | 注意: CSV 中该条为占位 ID 00000000, 可能无效";

BO_ 2164197927 ZT_FCEngine_00FF0A27: 8 Vector__XXX
 SG_ B0 : 0|8@1+ (1,0) [0|255] "" Vector__XXX
 SG_ B1 : 8|8@1+ (1,0) [0|255] "" Vector__XXX
 SG_ B2 : 16|8@1+ (1,0) [0|255] "" Vector__XXX
 SG_ B3 : 24|8@1+ (1,0) [0|255] "" Vector__XXX
 SG_ B4 : 32|8@1+ (1,0) [0|255] "" Vector__XXX
 SG_ B5 : 40|8@1+ (1,0) [0|255] "" Vector__XXX
 SG_ B6 : 48|8@1+ (1,0) [0|255] "" Vector__XXX
 SG_ B7 : 56|8@1+ (1,0) [0|255] "" Vector__XXX

BA_ "VFrameFormat" BO_ 2164197927 1;
CM_ BO_ 2164197927 "0xB300009D 中通新能源 > 燃料电池客车 > 燃料电池发动机 | 部件: 燃料电池发动机";

BO_ 2164198183 ZT_FCEngine_00FF0B27: 8 Vector__XXX
 SG_ B0 : 0|8@1+ (1,0) [0|255] "" Vector__XXX
 SG_ B1 : 8|8@1+ (1,0) [0|255] "" Vector__XXX
 SG_ B2 : 16|8@1+ (1,0) [0|255] "" Vector__XXX
 SG_ B3 : 24|8@1+ (1,0) [0|255] "" Vector__XXX
 SG_ B4 : 32|8@1+ (1,0) [0|255] "" Vector__XXX
 SG_ B5 : 40|8@1+ (1,0) [0|255] "" Vector__XXX
 SG_ B6 : 48|8@1+ (1,0) [0|255] "" Vector__XXX
 SG_ B7 : 56|8@1+ (1,0) [0|255] "" Vector__XXX

BA_ "VFrameFormat" BO_ 2164198183 1;
CM_ BO_ 2164198183 "0xB300009D 中通新能源 > 燃料电池客车 > 燃料电池发动机 | 部件: 燃料电池发动机";

BO_ 2552315154 ZT_FCEngine_18213D12: 8 Vector__XXX
 SG_ B0 : 0|8@1+ (1,0) [0|255] "" Vector__XXX
 SG_ B1 : 8|8@1+ (1,0) [0|255] "" Vector__XXX
 SG_ B2 : 16|8@1+ (1,0) [0|255] "" Vector__XXX
 SG_ B3 : 24|8@1+ (1,0) [0|255] "" Vector__XXX
 SG_ B4 : 32|8@1+ (1,0) [0|255] "" Vector__XXX
 SG_ B5 : 40|8@1+ (1,0) [0|255] "" Vector__XXX
 SG_ B6 : 48|8@1+ (1,0) [0|255] "" Vector__XXX
 SG_ B7 : 56|8@1+ (1,0) [0|255] "" Vector__XXX

BA_ "VFrameFormat" BO_ 2552315154 1;
CM_ BO_ 2552315154 "0xB300009D 中通新能源 > 燃料电池客车 > 燃料电池发动机 | 部件: 燃料电池发动机";

BO_ 2552380690 ZT_FCEngine_18223D12: 8 Vector__XXX
 SG_ B0 : 0|8@1+ (1,0) [0|255] "" Vector__XXX
 SG_ B1 : 8|8@1+ (1,0) [0|255] "" Vector__XXX
 SG_ B2 : 16|8@1+ (1,0) [0|255] "" Vector__XXX
 SG_ B3 : 24|8@1+ (1,0) [0|255] "" Vector__XXX
 SG_ B4 : 32|8@1+ (1,0) [0|255] "" Vector__XXX
 SG_ B5 : 40|8@1+ (1,0) [0|255] "" Vector__XXX
 SG_ B6 : 48|8@1+ (1,0) [0|255] "" Vector__XXX
 SG_ B7 : 56|8@1+ (1,0) [0|255] "" Vector__XXX

BA_ "VFrameFormat" BO_ 2552380690 1;
CM_ BO_ 2552380690 "0xB300009D 中通新能源 > 燃料电池客车 > 燃料电池发动机 | 部件: 燃料电池发动机";

BO_ 2552446226 ZT_FCEngine_18233D12: 8 Vector__XXX
 SG_ B0 : 0|8@1+ (1,0) [0|255] "" Vector__XXX
 SG_ B1 : 8|8@1+ (1,0) [0|255] "" Vector__XXX
 SG_ B2 : 16|8@1+ (1,0) [0|255] "" Vector__XXX
 SG_ B3 : 24|8@1+ (1,0) [0|255] "" Vector__XXX
 SG_ B4 : 32|8@1+ (1,0) [0|255] "" Vector__XXX
 SG_ B5 : 40|8@1+ (1,0) [0|255] "" Vector__XXX
 SG_ B6 : 48|8@1+ (1,0) [0|255] "" Vector__XXX
 SG_ B7 : 56|8@1+ (1,0) [0|255] "" Vector__XXX

BA_ "VFrameFormat" BO_ 2552446226 1;
CM_ BO_ 2552446226 "0xB300009D 中通新能源 > 燃料电池客车 > 燃料电池发动机 | 部件: 燃料电池发动机";

BO_ 2552511762 ZT_FCEngine_18243D12: 8 Vector__XXX
 SG_ B0 : 0|8@1+ (1,0) [0|255] "" Vector__XXX
 SG_ B1 : 8|8@1+ (1,0) [0|255] "" Vector__XXX
 SG_ B2 : 16|8@1+ (1,0) [0|255] "" Vector__XXX
 SG_ B3 : 24|8@1+ (1,0) [0|255] "" Vector__XXX
 SG_ B4 : 32|8@1+ (1,0) [0|255] "" Vector__XXX
 SG_ B5 : 40|8@1+ (1,0) [0|255] "" Vector__XXX
 SG_ B6 : 48|8@1+ (1,0) [0|255] "" Vector__XXX
 SG_ B7 : 56|8@1+ (1,0) [0|255] "" Vector__XXX

BA_ "VFrameFormat" BO_ 2552511762 1;
CM_ BO_ 2552511762 "0xB300009D 中通新能源 > 燃料电池客车 > 燃料电池发动机 | 部件: 燃料电池发动机";

BO_ 2566860818 ZT_FCEngine_18FF3012: 8 Vector__XXX
 SG_ B0 : 0|8@1+ (1,0) [0|255] "" Vector__XXX
 SG_ B1 : 8|8@1+ (1,0) [0|255] "" Vector__XXX
 SG_ B2 : 16|8@1+ (1,0) [0|255] "" Vector__XXX
 SG_ B3 : 24|8@1+ (1,0) [0|255] "" Vector__XXX
 SG_ B4 : 32|8@1+ (1,0) [0|255] "" Vector__XXX
 SG_ B5 : 40|8@1+ (1,0) [0|255] "" Vector__XXX
 SG_ B6 : 48|8@1+ (1,0) [0|255] "" Vector__XXX
 SG_ B7 : 56|8@1+ (1,0) [0|255] "" Vector__XXX

BA_ "VFrameFormat" BO_ 2566860818 1;
CM_ BO_ 2566860818 "0xB300009D 中通新能源 > 燃料电池客车 > 燃料电池发动机 | 部件: 燃料电池发动机";

BO_ 2566861074 ZT_FCEngine_18FF3112: 8 Vector__XXX
 SG_ B0 : 0|8@1+ (1,0) [0|255] "" Vector__XXX
 SG_ B1 : 8|8@1+ (1,0) [0|255] "" Vector__XXX
 SG_ B2 : 16|8@1+ (1,0) [0|255] "" Vector__XXX
 SG_ B3 : 24|8@1+ (1,0) [0|255] "" Vector__XXX
 SG_ B4 : 32|8@1+ (1,0) [0|255] "" Vector__XXX
 SG_ B5 : 40|8@1+ (1,0) [0|255] "" Vector__XXX
 SG_ B6 : 48|8@1+ (1,0) [0|255] "" Vector__XXX
 SG_ B7 : 56|8@1+ (1,0) [0|255] "" Vector__XXX

BA_ "VFrameFormat" BO_ 2566861074 1;
CM_ BO_ 2566861074 "0xB300009D 中通新能源 > 燃料电池客车 > 燃料电池发动机 | 部件: 燃料电池发动机";

BO_ 2566861330 ZT_FCEngine_18FF3212: 8 Vector__XXX
 SG_ B0 : 0|8@1+ (1,0) [0|255] "" Vector__XXX
 SG_ B1 : 8|8@1+ (1,0) [0|255] "" Vector__XXX
 SG_ B2 : 16|8@1+ (1,0) [0|255] "" Vector__XXX
 SG_ B3 : 24|8@1+ (1,0) [0|255] "" Vector__XXX
 SG_ B4 : 32|8@1+ (1,0) [0|255] "" Vector__XXX
 SG_ B5 : 40|8@1+ (1,0) [0|255] "" Vector__XXX
 SG_ B6 : 48|8@1+ (1,0) [0|255] "" Vector__XXX
 SG_ B7 : 56|8@1+ (1,0) [0|255] "" Vector__XXX

BA_ "VFrameFormat" BO_ 2566861330 1;
CM_ BO_ 2566861330 "0xB300009D 中通新能源 > 燃料电池客车 > 燃料电池发动机 | 部件: 燃料电池发动机";

BO_ 2566861586 ZT_FCEngine_18FF3312: 8 Vector__XXX
 SG_ B0 : 0|8@1+ (1,0) [0|255] "" Vector__XXX
 SG_ B1 : 8|8@1+ (1,0) [0|255] "" Vector__XXX
 SG_ B2 : 16|8@1+ (1,0) [0|255] "" Vector__XXX
 SG_ B3 : 24|8@1+ (1,0) [0|255] "" Vector__XXX
 SG_ B4 : 32|8@1+ (1,0) [0|255] "" Vector__XXX
 SG_ B5 : 40|8@1+ (1,0) [0|255] "" Vector__XXX
 SG_ B6 : 48|8@1+ (1,0) [0|255] "" Vector__XXX
 SG_ B7 : 56|8@1+ (1,0) [0|255] "" Vector__XXX

BA_ "VFrameFormat" BO_ 2566861586 1;
CM_ BO_ 2566861586 "0xB300009D 中通新能源 > 燃料电池客车 > 燃料电池发动机 | 部件: 燃料电池发动机";

BO_ 2566877458 ZT_FCEngine_18FF7112: 8 Vector__XXX
 SG_ B0 : 0|8@1+ (1,0) [0|255] "" Vector__XXX
 SG_ B1 : 8|8@1+ (1,0) [0|255] "" Vector__XXX
 SG_ B2 : 16|8@1+ (1,0) [0|255] "" Vector__XXX
 SG_ B3 : 24|8@1+ (1,0) [0|255] "" Vector__XXX
 SG_ B4 : 32|8@1+ (1,0) [0|255] "" Vector__XXX
 SG_ B5 : 40|8@1+ (1,0) [0|255] "" Vector__XXX
 SG_ B6 : 48|8@1+ (1,0) [0|255] "" Vector__XXX
 SG_ B7 : 56|8@1+ (1,0) [0|255] "" Vector__XXX

BA_ "VFrameFormat" BO_ 2566877458 1;
CM_ BO_ 2566877458 "0xB300009D 中通新能源 > 燃料电池客车 > 燃料电池发动机 | 部件: 燃料电池发动机";

BO_ 2566881298 ZT_FCEngine_18FF8012: 8 Vector__XXX
 SG_ B0 : 0|8@1+ (1,0) [0|255] "" Vector__XXX
 SG_ B1 : 8|8@1+ (1,0) [0|255] "" Vector__XXX
 SG_ B2 : 16|8@1+ (1,0) [0|255] "" Vector__XXX
 SG_ B3 : 24|8@1+ (1,0) [0|255] "" Vector__XXX
 SG_ B4 : 32|8@1+ (1,0) [0|255] "" Vector__XXX
 SG_ B5 : 40|8@1+ (1,0) [0|255] "" Vector__XXX
 SG_ B6 : 48|8@1+ (1,0) [0|255] "" Vector__XXX
 SG_ B7 : 56|8@1+ (1,0) [0|255] "" Vector__XXX

BA_ "VFrameFormat" BO_ 2566881298 1;
CM_ BO_ 2566881298 "0xB300009D 中通新能源 > 燃料电池客车 > 燃料电池发动机 | 部件: 燃料电池发动机";

BO_ 2566834933 ZT_HMS_18FECAF5: 8 Vector__XXX
 SG_ B0 : 0|8@1+ (1,0) [0|255] "" Vector__XXX
 SG_ B1 : 8|8@1+ (1,0) [0|255] "" Vector__XXX
 SG_ B2 : 16|8@1+ (1,0) [0|255] "" Vector__XXX
 SG_ B3 : 24|8@1+ (1,0) [0|255] "" Vector__XXX
 SG_ B4 : 32|8@1+ (1,0) [0|255] "" Vector__XXX
 SG_ B5 : 40|8@1+ (1,0) [0|255] "" Vector__XXX
 SG_ B6 : 48|8@1+ (1,0) [0|255] "" Vector__XXX
 SG_ B7 : 56|8@1+ (1,0) [0|255] "" Vector__XXX

BA_ "VFrameFormat" BO_ 2566834933 1;
CM_ BO_ 2566834933 "0xB300009E 中通新能源 > 燃料电池客车 > HMS 氢气管理系统 | 部件: HMS 氢气管理系统";

BO_ 2566889973 ZT_HMS_18FFA1F5: 8 Vector__XXX
 SG_ B0 : 0|8@1+ (1,0) [0|255] "" Vector__XXX
 SG_ B1 : 8|8@1+ (1,0) [0|255] "" Vector__XXX
 SG_ B2 : 16|8@1+ (1,0) [0|255] "" Vector__XXX
 SG_ B3 : 24|8@1+ (1,0) [0|255] "" Vector__XXX
 SG_ B4 : 32|8@1+ (1,0) [0|255] "" Vector__XXX
 SG_ B5 : 40|8@1+ (1,0) [0|255] "" Vector__XXX
 SG_ B6 : 48|8@1+ (1,0) [0|255] "" Vector__XXX
 SG_ B7 : 56|8@1+ (1,0) [0|255] "" Vector__XXX

BA_ "VFrameFormat" BO_ 2566889973 1;
CM_ BO_ 2566889973 "0xB300009E 中通新能源 > 燃料电池客车 > HMS 氢气管理系统 | 部件: HMS 氢气管理系统";

BO_ 2566890229 ZT_HMS_18FFA2F5: 8 Vector__XXX
 SG_ B0 : 0|8@1+ (1,0) [0|255] "" Vector__XXX
 SG_ B1 : 8|8@1+ (1,0) [0|255] "" Vector__XXX
 SG_ B2 : 16|8@1+ (1,0) [0|255] "" Vector__XXX
 SG_ B3 : 24|8@1+ (1,0) [0|255] "" Vector__XXX
 SG_ B4 : 32|8@1+ (1,0) [0|255] "" Vector__XXX
 SG_ B5 : 40|8@1+ (1,0) [0|255] "" Vector__XXX
 SG_ B6 : 48|8@1+ (1,0) [0|255] "" Vector__XXX
 SG_ B7 : 56|8@1+ (1,0) [0|255] "" Vector__XXX

BA_ "VFrameFormat" BO_ 2566890229 1;
CM_ BO_ 2566890229 "0xB300009E 中通新能源 > 燃料电池客车 > HMS 氢气管理系统 | 部件: HMS 氢气管理系统";

BO_ 2566890485 ZT_HMS_18FFA3F5: 8 Vector__XXX
 SG_ B0 : 0|8@1+ (1,0) [0|255] "" Vector__XXX
 SG_ B1 : 8|8@1+ (1,0) [0|255] "" Vector__XXX
 SG_ B2 : 16|8@1+ (1,0) [0|255] "" Vector__XXX
 SG_ B3 : 24|8@1+ (1,0) [0|255] "" Vector__XXX
 SG_ B4 : 32|8@1+ (1,0) [0|255] "" Vector__XXX
 SG_ B5 : 40|8@1+ (1,0) [0|255] "" Vector__XXX
 SG_ B6 : 48|8@1+ (1,0) [0|255] "" Vector__XXX
 SG_ B7 : 56|8@1+ (1,0) [0|255] "" Vector__XXX

BA_ "VFrameFormat" BO_ 2566890485 1;
CM_ BO_ 2566890485 "0xB300009E 中通新能源 > 燃料电池客车 > HMS 氢气管理系统 | 部件: HMS 氢气管理系统";

BO_ 2566890741 ZT_HMS_18FFA4F5: 8 Vector__XXX
 SG_ B0 : 0|8@1+ (1,0) [0|255] "" Vector__XXX
 SG_ B1 : 8|8@1+ (1,0) [0|255] "" Vector__XXX
 SG_ B2 : 16|8@1+ (1,0) [0|255] "" Vector__XXX
 SG_ B3 : 24|8@1+ (1,0) [0|255] "" Vector__XXX
 SG_ B4 : 32|8@1+ (1,0) [0|255] "" Vector__XXX
 SG_ B5 : 40|8@1+ (1,0) [0|255] "" Vector__XXX
 SG_ B6 : 48|8@1+ (1,0) [0|255] "" Vector__XXX
 SG_ B7 : 56|8@1+ (1,0) [0|255] "" Vector__XXX

BA_ "VFrameFormat" BO_ 2566890741 1;
CM_ BO_ 2566890741 "0xB300009E 中通新能源 > 燃料电池客车 > HMS 氢气管理系统 | 部件: HMS 氢气管理系统";

BO_ 2566890997 ZT_HMS_18FFA5F5: 8 Vector__XXX
 SG_ B0 : 0|8@1+ (1,0) [0|255] "" Vector__XXX
 SG_ B1 : 8|8@1+ (1,0) [0|255] "" Vector__XXX
 SG_ B2 : 16|8@1+ (1,0) [0|255] "" Vector__XXX
 SG_ B3 : 24|8@1+ (1,0) [0|255] "" Vector__XXX
 SG_ B4 : 32|8@1+ (1,0) [0|255] "" Vector__XXX
 SG_ B5 : 40|8@1+ (1,0) [0|255] "" Vector__XXX
 SG_ B6 : 48|8@1+ (1,0) [0|255] "" Vector__XXX
 SG_ B7 : 56|8@1+ (1,0) [0|255] "" Vector__XXX

BA_ "VFrameFormat" BO_ 2566890997 1;
CM_ BO_ 2566890997 "0xB300009E 中通新能源 > 燃料电池客车 > HMS 氢气管理系统 | 部件: HMS 氢气管理系统";

BO_ 2566891253 ZT_HMS_18FFA6F5: 8 Vector__XXX
 SG_ B0 : 0|8@1+ (1,0) [0|255] "" Vector__XXX
 SG_ B1 : 8|8@1+ (1,0) [0|255] "" Vector__XXX
 SG_ B2 : 16|8@1+ (1,0) [0|255] "" Vector__XXX
 SG_ B3 : 24|8@1+ (1,0) [0|255] "" Vector__XXX
 SG_ B4 : 32|8@1+ (1,0) [0|255] "" Vector__XXX
 SG_ B5 : 40|8@1+ (1,0) [0|255] "" Vector__XXX
 SG_ B6 : 48|8@1+ (1,0) [0|255] "" Vector__XXX
 SG_ B7 : 56|8@1+ (1,0) [0|255] "" Vector__XXX

BA_ "VFrameFormat" BO_ 2566891253 1;
CM_ BO_ 2566891253 "0xB300009E 中通新能源 > 燃料电池客车 > HMS 氢气管理系统 | 部件: HMS 氢气管理系统";

BO_ 2566891509 ZT_HMS_18FFA7F5: 8 Vector__XXX
 SG_ B0 : 0|8@1+ (1,0) [0|255] "" Vector__XXX
 SG_ B1 : 8|8@1+ (1,0) [0|255] "" Vector__XXX
 SG_ B2 : 16|8@1+ (1,0) [0|255] "" Vector__XXX
 SG_ B3 : 24|8@1+ (1,0) [0|255] "" Vector__XXX
 SG_ B4 : 32|8@1+ (1,0) [0|255] "" Vector__XXX
 SG_ B5 : 40|8@1+ (1,0) [0|255] "" Vector__XXX
 SG_ B6 : 48|8@1+ (1,0) [0|255] "" Vector__XXX
 SG_ B7 : 56|8@1+ (1,0) [0|255] "" Vector__XXX

BA_ "VFrameFormat" BO_ 2566891509 1;
CM_ BO_ 2566891509 "0xB300009E 中通新能源 > 燃料电池客车 > HMS 氢气管理系统 | 部件: HMS 氢气管理系统";

BO_ 2550245276 ZT_DCDC6KW_1801A79C: 8 Vector__XXX
 SG_ B0 : 0|8@1+ (1,0) [0|255] "" Vector__XXX
 SG_ B1 : 8|8@1+ (1,0) [0|255] "" Vector__XXX
 SG_ B2 : 16|8@1+ (1,0) [0|255] "" Vector__XXX
 SG_ B3 : 24|8@1+ (1,0) [0|255] "" Vector__XXX
 SG_ B4 : 32|8@1+ (1,0) [0|255] "" Vector__XXX
 SG_ B5 : 40|8@1+ (1,0) [0|255] "" Vector__XXX
 SG_ B6 : 48|8@1+ (1,0) [0|255] "" Vector__XXX
 SG_ B7 : 56|8@1+ (1,0) [0|255] "" Vector__XXX

BA_ "VFrameFormat" BO_ 2550245276 1;
CM_ BO_ 2550245276 "0xB300009F 中通新能源 > 燃料电池客车 > 6KW DC/DC（24V电瓶） | 部件: 6KW DC/DC（24V电瓶）";

BO_ 2550245532 ZT_DCDC6KW_1801A89C: 8 Vector__XXX
 SG_ B0 : 0|8@1+ (1,0) [0|255] "" Vector__XXX
 SG_ B1 : 8|8@1+ (1,0) [0|255] "" Vector__XXX
 SG_ B2 : 16|8@1+ (1,0) [0|255] "" Vector__XXX
 SG_ B3 : 24|8@1+ (1,0) [0|255] "" Vector__XXX
 SG_ B4 : 32|8@1+ (1,0) [0|255] "" Vector__XXX
 SG_ B5 : 40|8@1+ (1,0) [0|255] "" Vector__XXX
 SG_ B6 : 48|8@1+ (1,0) [0|255] "" Vector__XXX
 SG_ B7 : 56|8@1+ (1,0) [0|255] "" Vector__XXX

BA_ "VFrameFormat" BO_ 2550245532 1;
CM_ BO_ 2550245532 "0xB300009F 中通新能源 > 燃料电池客车 > 6KW DC/DC（24V电瓶） | 部件: 6KW DC/DC（24V电瓶）";

BO_ 2365541015 ZT_QZEco_0CFF4A97: 8 Vector__XXX
 SG_ B0 : 0|8@1+ (1,0) [0|255] "" Vector__XXX
 SG_ B1 : 8|8@1+ (1,0) [0|255] "" Vector__XXX
 SG_ B2 : 16|8@1+ (1,0) [0|255] "" Vector__XXX
 SG_ B3 : 24|8@1+ (1,0) [0|255] "" Vector__XXX
 SG_ B4 : 32|8@1+ (1,0) [0|255] "" Vector__XXX
 SG_ B5 : 40|8@1+ (1,0) [0|255] "" Vector__XXX
 SG_ B6 : 48|8@1+ (1,0) [0|255] "" Vector__XXX
 SG_ B7 : 56|8@1+ (1,0) [0|255] "" Vector__XXX

BA_ "VFrameFormat" BO_ 2365541015 1;
CM_ BO_ 2365541015 "0xB30000A1 中通新能源 > 燃料电池客车 > 清智智慧节能系统 | 部件: 清智智慧节能系统";

BO_ 2365541271 ZT_QZEco_0CFF4B97: 8 Vector__XXX
 SG_ B0 : 0|8@1+ (1,0) [0|255] "" Vector__XXX
 SG_ B1 : 8|8@1+ (1,0) [0|255] "" Vector__XXX
 SG_ B2 : 16|8@1+ (1,0) [0|255] "" Vector__XXX
 SG_ B3 : 24|8@1+ (1,0) [0|255] "" Vector__XXX
 SG_ B4 : 32|8@1+ (1,0) [0|255] "" Vector__XXX
 SG_ B5 : 40|8@1+ (1,0) [0|255] "" Vector__XXX
 SG_ B6 : 48|8@1+ (1,0) [0|255] "" Vector__XXX
 SG_ B7 : 56|8@1+ (1,0) [0|255] "" Vector__XXX

BA_ "VFrameFormat" BO_ 2365541271 1;
CM_ BO_ 2365541271 "0xB30000A1 中通新能源 > 燃料电池客车 > 清智智慧节能系统 | 部件: 清智智慧节能系统";

BO_ 2365541527 ZT_QZEco_0CFF4C97: 8 Vector__XXX
 SG_ B0 : 0|8@1+ (1,0) [0|255] "" Vector__XXX
 SG_ B1 : 8|8@1+ (1,0) [0|255] "" Vector__XXX
 SG_ B2 : 16|8@1+ (1,0) [0|255] "" Vector__XXX
 SG_ B3 : 24|8@1+ (1,0) [0|255] "" Vector__XXX
 SG_ B4 : 32|8@1+ (1,0) [0|255] "" Vector__XXX
 SG_ B5 : 40|8@1+ (1,0) [0|255] "" Vector__XXX
 SG_ B6 : 48|8@1+ (1,0) [0|255] "" Vector__XXX
 SG_ B7 : 56|8@1+ (1,0) [0|255] "" Vector__XXX

BA_ "VFrameFormat" BO_ 2365541527 1;
CM_ BO_ 2365541527 "0xB30000A1 中通新能源 > 燃料电池客车 > 清智智慧节能系统 | 部件: 清智智慧节能系统";

BO_ 2365541930 ZT_QZEco_0CFF4E2A: 8 Vector__XXX
 SG_ B0 : 0|8@1+ (1,0) [0|255] "" Vector__XXX
 SG_ B1 : 8|8@1+ (1,0) [0|255] "" Vector__XXX
 SG_ B2 : 16|8@1+ (1,0) [0|255] "" Vector__XXX
 SG_ B3 : 24|8@1+ (1,0) [0|255] "" Vector__XXX
 SG_ B4 : 32|8@1+ (1,0) [0|255] "" Vector__XXX
 SG_ B5 : 40|8@1+ (1,0) [0|255] "" Vector__XXX
 SG_ B6 : 48|8@1+ (1,0) [0|255] "" Vector__XXX
 SG_ B7 : 56|8@1+ (1,0) [0|255] "" Vector__XXX

BA_ "VFrameFormat" BO_ 2365541930 1;
CM_ BO_ 2365541930 "0xB30000A1 中通新能源 > 燃料电池客车 > 清智智慧节能系统 | 部件: 清智智慧节能系统";

BO_ 2566869251 ZT_TCU_18FF5103: 8 Vector__XXX
 SG_ B0 : 0|8@1+ (1,0) [0|255] "" Vector__XXX
 SG_ B1 : 8|8@1+ (1,0) [0|255] "" Vector__XXX
 SG_ B2 : 16|8@1+ (1,0) [0|255] "" Vector__XXX
 SG_ B3 : 24|8@1+ (1,0) [0|255] "" Vector__XXX
 SG_ B4 : 32|8@1+ (1,0) [0|255] "" Vector__XXX
 SG_ B5 : 40|8@1+ (1,0) [0|255] "" Vector__XXX
 SG_ B6 : 48|8@1+ (1,0) [0|255] "" Vector__XXX
 SG_ B7 : 56|8@1+ (1,0) [0|255] "" Vector__XXX

BA_ "VFrameFormat" BO_ 2566869251 1;
CM_ BO_ 2566869251 "0xB30000A2 中通新能源 > 燃料电池客车 > 变速箱控制器 | 部件: 变速箱控制器";

BO_ 2566884611 ZT_TCU_18FF8D03: 8 Vector__XXX
 SG_ B0 : 0|8@1+ (1,0) [0|255] "" Vector__XXX
 SG_ B1 : 8|8@1+ (1,0) [0|255] "" Vector__XXX
 SG_ B2 : 16|8@1+ (1,0) [0|255] "" Vector__XXX
 SG_ B3 : 24|8@1+ (1,0) [0|255] "" Vector__XXX
 SG_ B4 : 32|8@1+ (1,0) [0|255] "" Vector__XXX
 SG_ B5 : 40|8@1+ (1,0) [0|255] "" Vector__XXX
 SG_ B6 : 48|8@1+ (1,0) [0|255] "" Vector__XXX
 SG_ B7 : 56|8@1+ (1,0) [0|255] "" Vector__XXX

BA_ "VFrameFormat" BO_ 2566884611 1;
CM_ BO_ 2566884611 "0xB30000A2 中通新能源 > 燃料电池客车 > 变速箱控制器 | 部件: 变速箱控制器";

BO_ 2566849794 ZT_AdhesionTest_18FF0502: 8 Vector__XXX
 SG_ B0 : 0|8@1+ (1,0) [0|255] "" Vector__XXX
 SG_ B1 : 8|8@1+ (1,0) [0|255] "" Vector__XXX
 SG_ B2 : 16|8@1+ (1,0) [0|255] "" Vector__XXX
 SG_ B3 : 24|8@1+ (1,0) [0|255] "" Vector__XXX
 SG_ B4 : 32|8@1+ (1,0) [0|255] "" Vector__XXX
 SG_ B5 : 40|8@1+ (1,0) [0|255] "" Vector__XXX
 SG_ B6 : 48|8@1+ (1,0) [0|255] "" Vector__XXX
 SG_ B7 : 56|8@1+ (1,0) [0|255] "" Vector__XXX

BA_ "VFrameFormat" BO_ 2566849794 1;
CM_ BO_ 2566849794 "0xB30000A3 中通新能源 > 燃料电池客车 > 黏连检测设备/电脑 | 部件: 黏连检测设备/电脑";

BO_ 2566658287 ZT_VCU_18FC18EF: 8 Vector__XXX
 SG_ B0 : 0|8@1+ (1,0) [0|255] "" Vector__XXX
 SG_ B1 : 8|8@1+ (1,0) [0|255] "" Vector__XXX
 SG_ B2 : 16|8@1+ (1,0) [0|255] "" Vector__XXX
 SG_ B3 : 24|8@1+ (1,0) [0|255] "" Vector__XXX
 SG_ B4 : 32|8@1+ (1,0) [0|255] "" Vector__XXX
 SG_ B5 : 40|8@1+ (1,0) [0|255] "" Vector__XXX
 SG_ B6 : 48|8@1+ (1,0) [0|255] "" Vector__XXX
 SG_ B7 : 56|8@1+ (1,0) [0|255] "" Vector__XXX

BA_ "VFrameFormat" BO_ 2566658287 1;
CM_ BO_ 2566658287 "0xB30000A6 中通新能源 > 澳巴混合动力 > 7米澳巴混合动力客车 > VCU 整车控制器 | 0xB30000C7 中通新能源 > 澳巴混合动力 > 9米11米澳巴混合动力客车 > VCU 整车控制器 | 部件: VCU 整车控制器";

BO_ 2365523208 ZT_MCU_0CFF0508: 8 Vector__XXX
 SG_ B0 : 0|8@1+ (1,0) [0|255] "" Vector__XXX
 SG_ B1 : 8|8@1+ (1,0) [0|255] "" Vector__XXX
 SG_ B2 : 16|8@1+ (1,0) [0|255] "" Vector__XXX
 SG_ B3 : 24|8@1+ (1,0) [0|255] "" Vector__XXX
 SG_ B4 : 32|8@1+ (1,0) [0|255] "" Vector__XXX
 SG_ B5 : 40|8@1+ (1,0) [0|255] "" Vector__XXX
 SG_ B6 : 48|8@1+ (1,0) [0|255] "" Vector__XXX
 SG_ B7 : 56|8@1+ (1,0) [0|255] "" Vector__XXX

BA_ "VFrameFormat" BO_ 2365523208 1;
CM_ BO_ 2365523208 "0xB30000A7 中通新能源 > 澳巴混合动力 > 7米澳巴混合动力客车 > MCU 主驱电机控制器 | 0xB30000C8 中通新能源 > 澳巴混合动力 > 9米11米澳巴混合动力客车 > MCU 主驱电机控制器 | 部件: MCU 主驱电机控制器";

BO_ 2566883550 ZT_TMS_18FF88DE: 8 Vector__XXX
 SG_ B0 : 0|8@1+ (1,0) [0|255] "" Vector__XXX
 SG_ B1 : 8|8@1+ (1,0) [0|255] "" Vector__XXX
 SG_ B2 : 16|8@1+ (1,0) [0|255] "" Vector__XXX
 SG_ B3 : 24|8@1+ (1,0) [0|255] "" Vector__XXX
 SG_ B4 : 32|8@1+ (1,0) [0|255] "" Vector__XXX
 SG_ B5 : 40|8@1+ (1,0) [0|255] "" Vector__XXX
 SG_ B6 : 48|8@1+ (1,0) [0|255] "" Vector__XXX
 SG_ B7 : 56|8@1+ (1,0) [0|255] "" Vector__XXX

BA_ "VFrameFormat" BO_ 2566883550 1;
CM_ BO_ 2566883550 "0xB30000B8 中通新能源 > 澳巴混合动力 > 7米澳巴混合动力客车 > TMS 热管理 | 0xB30000D9 中通新能源 > 澳巴混合动力 > 9米11米澳巴混合动力客车 > TMS 热管理 | 部件: TMS 热管理";

BO_ 2364539904 ZT_Engine_0CF00400: 8 Vector__XXX
 SG_ B0 : 0|8@1+ (1,0) [0|255] "" Vector__XXX
 SG_ B1 : 8|8@1+ (1,0) [0|255] "" Vector__XXX
 SG_ B2 : 16|8@1+ (1,0) [0|255] "" Vector__XXX
 SG_ B3 : 24|8@1+ (1,0) [0|255] "" Vector__XXX
 SG_ B4 : 32|8@1+ (1,0) [0|255] "" Vector__XXX
 SG_ B5 : 40|8@1+ (1,0) [0|255] "" Vector__XXX
 SG_ B6 : 48|8@1+ (1,0) [0|255] "" Vector__XXX
 SG_ B7 : 56|8@1+ (1,0) [0|255] "" Vector__XXX

BA_ "VFrameFormat" BO_ 2364539904 1;
CM_ BO_ 2364539904 "0xB30000C0 中通新能源 > 澳巴混合动力 > 7米澳巴混合动力客车 > 发动机(玉柴燃气/柴油机) | 0xB30000E2 中通新能源 > 澳巴混合动力 > 9米11米澳巴混合动力客车 > 发动机(玉柴燃气/柴油机) | 部件: 发动机(玉柴燃气/柴油机)";

BO_ 2566719232 ZT_Engine_18FD0700: 8 Vector__XXX
 SG_ B0 : 0|8@1+ (1,0) [0|255] "" Vector__XXX
 SG_ B1 : 8|8@1+ (1,0) [0|255] "" Vector__XXX
 SG_ B2 : 16|8@1+ (1,0) [0|255] "" Vector__XXX
 SG_ B3 : 24|8@1+ (1,0) [0|255] "" Vector__XXX
 SG_ B4 : 32|8@1+ (1,0) [0|255] "" Vector__XXX
 SG_ B5 : 40|8@1+ (1,0) [0|255] "" Vector__XXX
 SG_ B6 : 48|8@1+ (1,0) [0|255] "" Vector__XXX
 SG_ B7 : 56|8@1+ (1,0) [0|255] "" Vector__XXX

BA_ "VFrameFormat" BO_ 2566719232 1;
CM_ BO_ 2566719232 "0xB30000C0 中通新能源 > 澳巴混合动力 > 7米澳巴混合动力客车 > 发动机(玉柴燃气/柴油机) | 0xB30000E2 中通新能源 > 澳巴混合动力 > 9米11米澳巴混合动力客车 > 发动机(玉柴燃气/柴油机) | 部件: 发动机(玉柴燃气/柴油机)";

BO_ 2566749184 ZT_Engine_18FD7C00: 8 Vector__XXX
 SG_ B0 : 0|8@1+ (1,0) [0|255] "" Vector__XXX
 SG_ B1 : 8|8@1+ (1,0) [0|255] "" Vector__XXX
 SG_ B2 : 16|8@1+ (1,0) [0|255] "" Vector__XXX
 SG_ B3 : 24|8@1+ (1,0) [0|255] "" Vector__XXX
 SG_ B4 : 32|8@1+ (1,0) [0|255] "" Vector__XXX
 SG_ B5 : 40|8@1+ (1,0) [0|255] "" Vector__XXX
 SG_ B6 : 48|8@1+ (1,0) [0|255] "" Vector__XXX
 SG_ B7 : 56|8@1+ (1,0) [0|255] "" Vector__XXX

BA_ "VFrameFormat" BO_ 2566749184 1;
CM_ BO_ 2566749184 "0xB30000C0 中通新能源 > 澳巴混合动力 > 7米澳巴混合动力客车 > 发动机(玉柴燃气/柴油机) | 0xB30000E2 中通新能源 > 澳巴混合动力 > 9米11米澳巴混合动力客车 > 发动机(玉柴燃气/柴油机) | 部件: 发动机(玉柴燃气/柴油机)";

BO_ 2566757120 ZT_Engine_18FD9B00: 8 Vector__XXX
 SG_ B0 : 0|8@1+ (1,0) [0|255] "" Vector__XXX
 SG_ B1 : 8|8@1+ (1,0) [0|255] "" Vector__XXX
 SG_ B2 : 16|8@1+ (1,0) [0|255] "" Vector__XXX
 SG_ B3 : 24|8@1+ (1,0) [0|255] "" Vector__XXX
 SG_ B4 : 32|8@1+ (1,0) [0|255] "" Vector__XXX
 SG_ B5 : 40|8@1+ (1,0) [0|255] "" Vector__XXX
 SG_ B6 : 48|8@1+ (1,0) [0|255] "" Vector__XXX
 SG_ B7 : 56|8@1+ (1,0) [0|255] "" Vector__XXX

BA_ "VFrameFormat" BO_ 2566757120 1;
CM_ BO_ 2566757120 "0xB30000C0 中通新能源 > 澳巴混合动力 > 7米澳巴混合动力客车 > 发动机(玉柴燃气/柴油机) | 0xB30000E2 中通新能源 > 澳巴混合动力 > 9米11米澳巴混合动力客车 > 发动机(玉柴燃气/柴油机) | 部件: 发动机(玉柴燃气/柴油机)";

BO_ 2566804992 ZT_Engine_18FE5600: 8 Vector__XXX
 SG_ B0 : 0|8@1+ (1,0) [0|255] "" Vector__XXX
 SG_ B1 : 8|8@1+ (1,0) [0|255] "" Vector__XXX
 SG_ B2 : 16|8@1+ (1,0) [0|255] "" Vector__XXX
 SG_ B3 : 24|8@1+ (1,0) [0|255] "" Vector__XXX
 SG_ B4 : 32|8@1+ (1,0) [0|255] "" Vector__XXX
 SG_ B5 : 40|8@1+ (1,0) [0|255] "" Vector__XXX
 SG_ B6 : 48|8@1+ (1,0) [0|255] "" Vector__XXX
 SG_ B7 : 56|8@1+ (1,0) [0|255] "" Vector__XXX

BA_ "VFrameFormat" BO_ 2566804992 1;
CM_ BO_ 2566804992 "0xB30000C0 中通新能源 > 澳巴混合动力 > 7米澳巴混合动力客车 > 发动机(玉柴燃气/柴油机) | 0xB30000E2 中通新能源 > 澳巴混合动力 > 9米11米澳巴混合动力客车 > 发动机(玉柴燃气/柴油机) | 部件: 发动机(玉柴燃气/柴油机)";

BO_ 2566809856 ZT_Engine_18FE6900: 8 Vector__XXX
 SG_ B0 : 0|8@1+ (1,0) [0|255] "" Vector__XXX
 SG_ B1 : 8|8@1+ (1,0) [0|255] "" Vector__XXX
 SG_ B2 : 16|8@1+ (1,0) [0|255] "" Vector__XXX
 SG_ B3 : 24|8@1+ (1,0) [0|255] "" Vector__XXX
 SG_ B4 : 32|8@1+ (1,0) [0|255] "" Vector__XXX
 SG_ B5 : 40|8@1+ (1,0) [0|255] "" Vector__XXX
 SG_ B6 : 48|8@1+ (1,0) [0|255] "" Vector__XXX
 SG_ B7 : 56|8@1+ (1,0) [0|255] "" Vector__XXX

BA_ "VFrameFormat" BO_ 2566809856 1;
CM_ BO_ 2566809856 "0xB30000C0 中通新能源 > 澳巴混合动力 > 7米澳巴混合动力客车 > 发动机(玉柴燃气/柴油机) | 0xB30000E2 中通新能源 > 澳巴混合动力 > 9米11米澳巴混合动力客车 > 发动机(玉柴燃气/柴油机) | 部件: 发动机(玉柴燃气/柴油机)";

BO_ 2566834688 ZT_Engine_18FECA00: 8 Vector__XXX
 SG_ B0 : 0|8@1+ (1,0) [0|255] "" Vector__XXX
 SG_ B1 : 8|8@1+ (1,0) [0|255] "" Vector__XXX
 SG_ B2 : 16|8@1+ (1,0) [0|255] "" Vector__XXX
 SG_ B3 : 24|8@1+ (1,0) [0|255] "" Vector__XXX
 SG_ B4 : 32|8@1+ (1,0) [0|255] "" Vector__XXX
 SG_ B5 : 40|8@1+ (1,0) [0|255] "" Vector__XXX
 SG_ B6 : 48|8@1+ (1,0) [0|255] "" Vector__XXX
 SG_ B7 : 56|8@1+ (1,0) [0|255] "" Vector__XXX

BA_ "VFrameFormat" BO_ 2566834688 1;
CM_ BO_ 2566834688 "0xB30000C0 中通新能源 > 澳巴混合动力 > 7米澳巴混合动力客车 > 发动机(玉柴燃气/柴油机) | 0xB30000E2 中通新能源 > 澳巴混合动力 > 9米11米澳巴混合动力客车 > 发动机(玉柴燃气/柴油机) | 部件: 发动机(玉柴燃气/柴油机)";

BO_ 2566842624 ZT_Engine_18FEE900: 8 Vector__XXX
 SG_ B0 : 0|8@1+ (1,0) [0|255] "" Vector__XXX
 SG_ B1 : 8|8@1+ (1,0) [0|255] "" Vector__XXX
 SG_ B2 : 16|8@1+ (1,0) [0|255] "" Vector__XXX
 SG_ B3 : 24|8@1+ (1,0) [0|255] "" Vector__XXX
 SG_ B4 : 32|8@1+ (1,0) [0|255] "" Vector__XXX
 SG_ B5 : 40|8@1+ (1,0) [0|255] "" Vector__XXX
 SG_ B6 : 48|8@1+ (1,0) [0|255] "" Vector__XXX
 SG_ B7 : 56|8@1+ (1,0) [0|255] "" Vector__XXX

BA_ "VFrameFormat" BO_ 2566842624 1;
CM_ BO_ 2566842624 "0xB30000C0 中通新能源 > 澳巴混合动力 > 7米澳巴混合动力客车 > 发动机(玉柴燃气/柴油机) | 0xB30000E2 中通新能源 > 澳巴混合动力 > 9米11米澳巴混合动力客车 > 发动机(玉柴燃气/柴油机) | 部件: 发动机(玉柴燃气/柴油机)";

BO_ 2566843904 ZT_Engine_18FEEE00: 8 Vector__XXX
 SG_ B0 : 0|8@1+ (1,0) [0|255] "" Vector__XXX
 SG_ B1 : 8|8@1+ (1,0) [0|255] "" Vector__XXX
 SG_ B2 : 16|8@1+ (1,0) [0|255] "" Vector__XXX
 SG_ B3 : 24|8@1+ (1,0) [0|255] "" Vector__XXX
 SG_ B4 : 32|8@1+ (1,0) [0|255] "" Vector__XXX
 SG_ B5 : 40|8@1+ (1,0) [0|255] "" Vector__XXX
 SG_ B6 : 48|8@1+ (1,0) [0|255] "" Vector__XXX
 SG_ B7 : 56|8@1+ (1,0) [0|255] "" Vector__XXX

BA_ "VFrameFormat" BO_ 2566843904 1;
CM_ BO_ 2566843904 "0xB30000C0 中通新能源 > 澳巴混合动力 > 7米澳巴混合动力客车 > 发动机(玉柴燃气/柴油机) | 0xB30000E2 中通新能源 > 澳巴混合动力 > 9米11米澳巴混合动力客车 > 发动机(玉柴燃气/柴油机) | 部件: 发动机(玉柴燃气/柴油机)";

BO_ 2566844160 ZT_Engine_18FEEF00: 8 Vector__XXX
 SG_ B0 : 0|8@1+ (1,0) [0|255] "" Vector__XXX
 SG_ B1 : 8|8@1+ (1,0) [0|255] "" Vector__XXX
 SG_ B2 : 16|8@1+ (1,0) [0|255] "" Vector__XXX
 SG_ B3 : 24|8@1+ (1,0) [0|255] "" Vector__XXX
 SG_ B4 : 32|8@1+ (1,0) [0|255] "" Vector__XXX
 SG_ B5 : 40|8@1+ (1,0) [0|255] "" Vector__XXX
 SG_ B6 : 48|8@1+ (1,0) [0|255] "" Vector__XXX
 SG_ B7 : 56|8@1+ (1,0) [0|255] "" Vector__XXX

BA_ "VFrameFormat" BO_ 2566844160 1;
CM_ BO_ 2566844160 "0xB30000C0 中通新能源 > 澳巴混合动力 > 7米澳巴混合动力客车 > 发动机(玉柴燃气/柴油机) | 0xB30000E2 中通新能源 > 澳巴混合动力 > 9米11米澳巴混合动力客车 > 发动机(玉柴燃气/柴油机) | 部件: 发动机(玉柴燃气/柴油机)";

BO_ 2566844928 ZT_Engine_18FEF200: 8 Vector__XXX
 SG_ B0 : 0|8@1+ (1,0) [0|255] "" Vector__XXX
 SG_ B1 : 8|8@1+ (1,0) [0|255] "" Vector__XXX
 SG_ B2 : 16|8@1+ (1,0) [0|255] "" Vector__XXX
 SG_ B3 : 24|8@1+ (1,0) [0|255] "" Vector__XXX
 SG_ B4 : 32|8@1+ (1,0) [0|255] "" Vector__XXX
 SG_ B5 : 40|8@1+ (1,0) [0|255] "" Vector__XXX
 SG_ B6 : 48|8@1+ (1,0) [0|255] "" Vector__XXX
 SG_ B7 : 56|8@1+ (1,0) [0|255] "" Vector__XXX

BA_ "VFrameFormat" BO_ 2566844928 1;
CM_ BO_ 2566844928 "0xB30000C0 中通新能源 > 澳巴混合动力 > 7米澳巴混合动力客车 > 发动机(玉柴燃气/柴油机) | 0xB30000E2 中通新能源 > 澳巴混合动力 > 9米11米澳巴混合动力客车 > 发动机(玉柴燃气/柴油机) | 部件: 发动机(玉柴燃气/柴油机)";

BO_ 2566845696 ZT_Engine_18FEF500: 8 Vector__XXX
 SG_ B0 : 0|8@1+ (1,0) [0|255] "" Vector__XXX
 SG_ B1 : 8|8@1+ (1,0) [0|255] "" Vector__XXX
 SG_ B2 : 16|8@1+ (1,0) [0|255] "" Vector__XXX
 SG_ B3 : 24|8@1+ (1,0) [0|255] "" Vector__XXX
 SG_ B4 : 32|8@1+ (1,0) [0|255] "" Vector__XXX
 SG_ B5 : 40|8@1+ (1,0) [0|255] "" Vector__XXX
 SG_ B6 : 48|8@1+ (1,0) [0|255] "" Vector__XXX
 SG_ B7 : 56|8@1+ (1,0) [0|255] "" Vector__XXX

BA_ "VFrameFormat" BO_ 2566845696 1;
CM_ BO_ 2566845696 "0xB30000C0 中通新能源 > 澳巴混合动力 > 7米澳巴混合动力客车 > 发动机(玉柴燃气/柴油机) | 0xB30000E2 中通新能源 > 澳巴混合动力 > 9米11米澳巴混合动力客车 > 发动机(玉柴燃气/柴油机) | 部件: 发动机(玉柴燃气/柴油机)";

BO_ 2566848256 ZT_Engine_18FEFF00: 8 Vector__XXX
 SG_ B0 : 0|8@1+ (1,0) [0|255] "" Vector__XXX
 SG_ B1 : 8|8@1+ (1,0) [0|255] "" Vector__XXX
 SG_ B2 : 16|8@1+ (1,0) [0|255] "" Vector__XXX
 SG_ B3 : 24|8@1+ (1,0) [0|255] "" Vector__XXX
 SG_ B4 : 32|8@1+ (1,0) [0|255] "" Vector__XXX
 SG_ B5 : 40|8@1+ (1,0) [0|255] "" Vector__XXX
 SG_ B6 : 48|8@1+ (1,0) [0|255] "" Vector__XXX
 SG_ B7 : 56|8@1+ (1,0) [0|255] "" Vector__XXX

BA_ "VFrameFormat" BO_ 2566848256 1;
CM_ BO_ 2566848256 "0xB30000C0 中通新能源 > 澳巴混合动力 > 7米澳巴混合动力客车 > 发动机(玉柴燃气/柴油机) | 0xB30000E2 中通新能源 > 澳巴混合动力 > 9米11米澳巴混合动力客车 > 发动机(玉柴燃气/柴油机) | 部件: 发动机(玉柴燃气/柴油机)";

BO_ 2566787596 ZT_EPB_18FE120C: 8 Vector__XXX
 SG_ B0 : 0|8@1+ (1,0) [0|255] "" Vector__XXX
 SG_ B1 : 8|8@1+ (1,0) [0|255] "" Vector__XXX
 SG_ B2 : 16|8@1+ (1,0) [0|255] "" Vector__XXX
 SG_ B3 : 24|8@1+ (1,0) [0|255] "" Vector__XXX
 SG_ B4 : 32|8@1+ (1,0) [0|255] "" Vector__XXX
 SG_ B5 : 40|8@1+ (1,0) [0|255] "" Vector__XXX
 SG_ B6 : 48|8@1+ (1,0) [0|255] "" Vector__XXX
 SG_ B7 : 56|8@1+ (1,0) [0|255] "" Vector__XXX

BA_ "VFrameFormat" BO_ 2566787596 1;
CM_ BO_ 2566787596 "0xB30000C2 中通新能源 > 澳巴混合动力 > 7米澳巴混合动力客车 > 科密电子手刹 | 0xB30000E4 中通新能源 > 澳巴混合动力 > 9米11米澳巴混合动力客车 > 科密电子手刹 | 部件: 科密电子手刹";

BO_ 2357304468 ZT_HCU_0C819C94: 8 Vector__XXX
 SG_ B0 : 0|8@1+ (1,0) [0|255] "" Vector__XXX
 SG_ B1 : 8|8@1+ (1,0) [0|255] "" Vector__XXX
 SG_ B2 : 16|8@1+ (1,0) [0|255] "" Vector__XXX
 SG_ B3 : 24|8@1+ (1,0) [0|255] "" Vector__XXX
 SG_ B4 : 32|8@1+ (1,0) [0|255] "" Vector__XXX
 SG_ B5 : 40|8@1+ (1,0) [0|255] "" Vector__XXX
 SG_ B6 : 48|8@1+ (1,0) [0|255] "" Vector__XXX
 SG_ B7 : 56|8@1+ (1,0) [0|255] "" Vector__XXX

BA_ "VFrameFormat" BO_ 2357304468 1;
CM_ BO_ 2357304468 "0xB30000C3 中通新能源 > 澳巴混合动力 > 7米澳巴混合动力客车 > HCU 混动控制单元 | 0xB30000E5 中通新能源 > 澳巴混合动力 > 9米11米澳巴混合动力客车 > HCU 混动控制单元 | 部件: HCU 混动控制单元";

BO_ 2357370004 ZT_HCU_0C829C94: 8 Vector__XXX
 SG_ B0 : 0|8@1+ (1,0) [0|255] "" Vector__XXX
 SG_ B1 : 8|8@1+ (1,0) [0|255] "" Vector__XXX
 SG_ B2 : 16|8@1+ (1,0) [0|255] "" Vector__XXX
 SG_ B3 : 24|8@1+ (1,0) [0|255] "" Vector__XXX
 SG_ B4 : 32|8@1+ (1,0) [0|255] "" Vector__XXX
 SG_ B5 : 40|8@1+ (1,0) [0|255] "" Vector__XXX
 SG_ B6 : 48|8@1+ (1,0) [0|255] "" Vector__XXX
 SG_ B7 : 56|8@1+ (1,0) [0|255] "" Vector__XXX

BA_ "VFrameFormat" BO_ 2357370004 1;
CM_ BO_ 2357370004 "0xB30000C3 中通新能源 > 澳巴混合动力 > 7米澳巴混合动力客车 > HCU 混动控制单元 | 0xB30000E5 中通新能源 > 澳巴混合动力 > 9米11米澳巴混合动力客车 > HCU 混动控制单元 | 部件: HCU 混动控制单元";

BO_ 2357435540 ZT_HCU_0C839C94: 8 Vector__XXX
 SG_ B0 : 0|8@1+ (1,0) [0|255] "" Vector__XXX
 SG_ B1 : 8|8@1+ (1,0) [0|255] "" Vector__XXX
 SG_ B2 : 16|8@1+ (1,0) [0|255] "" Vector__XXX
 SG_ B3 : 24|8@1+ (1,0) [0|255] "" Vector__XXX
 SG_ B4 : 32|8@1+ (1,0) [0|255] "" Vector__XXX
 SG_ B5 : 40|8@1+ (1,0) [0|255] "" Vector__XXX
 SG_ B6 : 48|8@1+ (1,0) [0|255] "" Vector__XXX
 SG_ B7 : 56|8@1+ (1,0) [0|255] "" Vector__XXX

BA_ "VFrameFormat" BO_ 2357435540 1;
CM_ BO_ 2357435540 "0xB30000C3 中通新能源 > 澳巴混合动力 > 7米澳巴混合动力客车 > HCU 混动控制单元 | 0xB30000E5 中通新能源 > 澳巴混合动力 > 9米11米澳巴混合动力客车 > HCU 混动控制单元 | 部件: HCU 混动控制单元";

BO_ 2357501076 ZT_HCU_0C849C94: 8 Vector__XXX
 SG_ B0 : 0|8@1+ (1,0) [0|255] "" Vector__XXX
 SG_ B1 : 8|8@1+ (1,0) [0|255] "" Vector__XXX
 SG_ B2 : 16|8@1+ (1,0) [0|255] "" Vector__XXX
 SG_ B3 : 24|8@1+ (1,0) [0|255] "" Vector__XXX
 SG_ B4 : 32|8@1+ (1,0) [0|255] "" Vector__XXX
 SG_ B5 : 40|8@1+ (1,0) [0|255] "" Vector__XXX
 SG_ B6 : 48|8@1+ (1,0) [0|255] "" Vector__XXX
 SG_ B7 : 56|8@1+ (1,0) [0|255] "" Vector__XXX

BA_ "VFrameFormat" BO_ 2357501076 1;
CM_ BO_ 2357501076 "0xB30000C3 中通新能源 > 澳巴混合动力 > 7米澳巴混合动力客车 > HCU 混动控制单元 | 0xB30000E5 中通新能源 > 澳巴混合动力 > 9米11米澳巴混合动力客车 > HCU 混动控制单元 | 部件: HCU 混动控制单元";

BO_ 2355143836 ZT_RCU_0C60A49C: 8 Vector__XXX
 SG_ B0 : 0|8@1+ (1,0) [0|255] "" Vector__XXX
 SG_ B1 : 8|8@1+ (1,0) [0|255] "" Vector__XXX
 SG_ B2 : 16|8@1+ (1,0) [0|255] "" Vector__XXX
 SG_ B3 : 24|8@1+ (1,0) [0|255] "" Vector__XXX
 SG_ B4 : 32|8@1+ (1,0) [0|255] "" Vector__XXX
 SG_ B5 : 40|8@1+ (1,0) [0|255] "" Vector__XXX
 SG_ B6 : 48|8@1+ (1,0) [0|255] "" Vector__XXX
 SG_ B7 : 56|8@1+ (1,0) [0|255] "" Vector__XXX

BA_ "VFrameFormat" BO_ 2355143836 1;
CM_ BO_ 2355143836 "0xB30000C4 中通新能源 > 澳巴混合动力 > 7米澳巴混合动力客车 > RCU 整车控制接收 | 部件: RCU 整车控制接收";

BO_ 2483328156 ZT_RCU_1404949C: 8 Vector__XXX
 SG_ B0 : 0|8@1+ (1,0) [0|255] "" Vector__XXX
 SG_ B1 : 8|8@1+ (1,0) [0|255] "" Vector__XXX
 SG_ B2 : 16|8@1+ (1,0) [0|255] "" Vector__XXX
 SG_ B3 : 24|8@1+ (1,0) [0|255] "" Vector__XXX
 SG_ B4 : 32|8@1+ (1,0) [0|255] "" Vector__XXX
 SG_ B5 : 40|8@1+ (1,0) [0|255] "" Vector__XXX
 SG_ B6 : 48|8@1+ (1,0) [0|255] "" Vector__XXX
 SG_ B7 : 56|8@1+ (1,0) [0|255] "" Vector__XXX

BA_ "VFrameFormat" BO_ 2483328156 1;
CM_ BO_ 2483328156 "0xB30000C4 中通新能源 > 澳巴混合动力 > 7米澳巴混合动力客车 > RCU 整车控制接收 | 0xB30000E6 中通新能源 > 澳巴混合动力 > 9米11米澳巴混合动力客车 > RCU 整车控制接收 | 部件: RCU 整车控制接收";

BO_ 2483393692 ZT_RCU_1405949C: 8 Vector__XXX
 SG_ B0 : 0|8@1+ (1,0) [0|255] "" Vector__XXX
 SG_ B1 : 8|8@1+ (1,0) [0|255] "" Vector__XXX
 SG_ B2 : 16|8@1+ (1,0) [0|255] "" Vector__XXX
 SG_ B3 : 24|8@1+ (1,0) [0|255] "" Vector__XXX
 SG_ B4 : 32|8@1+ (1,0) [0|255] "" Vector__XXX
 SG_ B5 : 40|8@1+ (1,0) [0|255] "" Vector__XXX
 SG_ B6 : 48|8@1+ (1,0) [0|255] "" Vector__XXX
 SG_ B7 : 56|8@1+ (1,0) [0|255] "" Vector__XXX

BA_ "VFrameFormat" BO_ 2483393692 1;
CM_ BO_ 2483393692 "0xB30000C4 中通新能源 > 澳巴混合动力 > 7米澳巴混合动力客车 > RCU 整车控制接收 | 0xB30000E6 中通新能源 > 澳巴混合动力 > 9米11米澳巴混合动力客车 > RCU 整车控制接收 | 部件: RCU 整车控制接收";

BO_ 2559677596 ZT_RCU_1891949C: 8 Vector__XXX
 SG_ B0 : 0|8@1+ (1,0) [0|255] "" Vector__XXX
 SG_ B1 : 8|8@1+ (1,0) [0|255] "" Vector__XXX
 SG_ B2 : 16|8@1+ (1,0) [0|255] "" Vector__XXX
 SG_ B3 : 24|8@1+ (1,0) [0|255] "" Vector__XXX
 SG_ B4 : 32|8@1+ (1,0) [0|255] "" Vector__XXX
 SG_ B5 : 40|8@1+ (1,0) [0|255] "" Vector__XXX
 SG_ B6 : 48|8@1+ (1,0) [0|255] "" Vector__XXX
 SG_ B7 : 56|8@1+ (1,0) [0|255] "" Vector__XXX

BA_ "VFrameFormat" BO_ 2559677596 1;
CM_ BO_ 2559677596 "0xB30000C4 中通新能源 > 澳巴混合动力 > 7米澳巴混合动力客车 > RCU 整车控制接收 | 0xB30000E6 中通新能源 > 澳巴混合动力 > 9米11米澳巴混合动力客车 > RCU 整车控制接收 | 部件: RCU 整车控制接收";

BO_ 2559743132 ZT_RCU_1892949C: 8 Vector__XXX
 SG_ B0 : 0|8@1+ (1,0) [0|255] "" Vector__XXX
 SG_ B1 : 8|8@1+ (1,0) [0|255] "" Vector__XXX
 SG_ B2 : 16|8@1+ (1,0) [0|255] "" Vector__XXX
 SG_ B3 : 24|8@1+ (1,0) [0|255] "" Vector__XXX
 SG_ B4 : 32|8@1+ (1,0) [0|255] "" Vector__XXX
 SG_ B5 : 40|8@1+ (1,0) [0|255] "" Vector__XXX
 SG_ B6 : 48|8@1+ (1,0) [0|255] "" Vector__XXX
 SG_ B7 : 56|8@1+ (1,0) [0|255] "" Vector__XXX

BA_ "VFrameFormat" BO_ 2559743132 1;
CM_ BO_ 2559743132 "0xB30000C4 中通新能源 > 澳巴混合动力 > 7米澳巴混合动力客车 > RCU 整车控制接收 | 0xB30000E6 中通新能源 > 澳巴混合动力 > 9米11米澳巴混合动力客车 > RCU 整车控制接收 | 部件: RCU 整车控制接收";

BO_ 2559808668 ZT_RCU_1893949C: 8 Vector__XXX
 SG_ B0 : 0|8@1+ (1,0) [0|255] "" Vector__XXX
 SG_ B1 : 8|8@1+ (1,0) [0|255] "" Vector__XXX
 SG_ B2 : 16|8@1+ (1,0) [0|255] "" Vector__XXX
 SG_ B3 : 24|8@1+ (1,0) [0|255] "" Vector__XXX
 SG_ B4 : 32|8@1+ (1,0) [0|255] "" Vector__XXX
 SG_ B5 : 40|8@1+ (1,0) [0|255] "" Vector__XXX
 SG_ B6 : 48|8@1+ (1,0) [0|255] "" Vector__XXX
 SG_ B7 : 56|8@1+ (1,0) [0|255] "" Vector__XXX

BA_ "VFrameFormat" BO_ 2559808668 1;
CM_ BO_ 2559808668 "0xB30000C4 中通新能源 > 澳巴混合动力 > 7米澳巴混合动力客车 > RCU 整车控制接收 | 0xB30000E6 中通新能源 > 澳巴混合动力 > 9米11米澳巴混合动力客车 > RCU 整车控制接收 | 部件: RCU 整车控制接收";

BO_ 2566719247 ZT_TCU_18FD070F: 8 Vector__XXX
 SG_ B0 : 0|8@1+ (1,0) [0|255] "" Vector__XXX
 SG_ B1 : 8|8@1+ (1,0) [0|255] "" Vector__XXX
 SG_ B2 : 16|8@1+ (1,0) [0|255] "" Vector__XXX
 SG_ B3 : 24|8@1+ (1,0) [0|255] "" Vector__XXX
 SG_ B4 : 32|8@1+ (1,0) [0|255] "" Vector__XXX
 SG_ B5 : 40|8@1+ (1,0) [0|255] "" Vector__XXX
 SG_ B6 : 48|8@1+ (1,0) [0|255] "" Vector__XXX
 SG_ B7 : 56|8@1+ (1,0) [0|255] "" Vector__XXX

BA_ "VFrameFormat" BO_ 2566719247 1;
CM_ BO_ 2566719247 "0xB30000C5 中通新能源 > 澳巴混合动力 > 7米澳巴混合动力客车 > CLU 变速控制 | 0xB30000E7 中通新能源 > 澳巴混合动力 > 9米11米澳巴混合动力客车 > CLU 变速控制 | 部件: CLU 变速控制";
